VERSION "June 2, 2025"

NS_ :

BS_:

BU_: VEH CH Receiver Receiver ChassisBus VehicleBus PartyBus

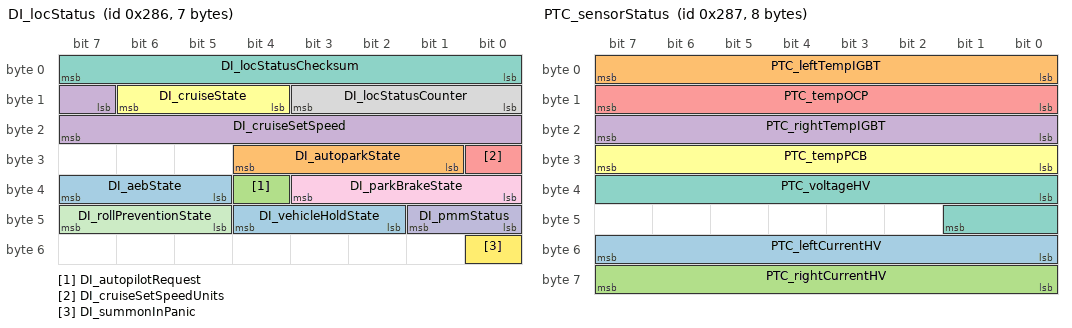
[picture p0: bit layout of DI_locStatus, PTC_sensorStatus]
BO_ 646 DI_locStatus: 7 VEH
 SG_ DI_aebState : 37|3@1+ (1,0) [0|0] "" Vector__XXX
 SG_ DI_autoparkState : 25|4@1+ (1,0) [0|0] "" Vector__XXX
 SG_ DI_autopilotRequest : 36|1@1+ (1,0) [0|0] "" Vector__XXX
 SG_ DI_cruiseSetSpeed : 15|9@1+ (0.5,0) [0|0] "speed" Vector__XXX
 SG_ DI_cruiseSetSpeedUnits : 24|1@1+ (1,0) [0|0] "" Vector__XXX
 SG_ DI_cruiseState : 12|3@1+ (1,0) [0|0] "" Vector__XXX
 SG_ DI_locStatusChecksum : 0|8@1+ (1,0) [0|0] "" Vector__XXX
 SG_ DI_locStatusCounter : 8|4@1+ (1,0) [0|0] "" Vector__XXX
 SG_ DI_parkBrakeState : 32|4@1+ (1,0) [0|0] "" Vector__XXX
 SG_ DI_pmmStatus : 40|2@1+ (1,0) [0|0] "" Vector__XXX
 SG_ DI_rollPreventionState : 45|3@1+ (1,0) [0|0] "" Vector__XXX
 SG_ DI_summonInPanic : 48|1@1+ (1,0) [0|0] "" Vector__XXX
 SG_ DI_vehicleHoldState : 42|3@1+ (1,0) [0|0] "" Vector__XXX

BO_ 647 PTC_sensorStatus: 8 VEH
 SG_ PTC_leftCurrentHV : 48|8@1+ (0.2,0) [0|0] "A" Vector__XXX
 SG_ PTC_leftTempIGBT : 0|8@1+ (1,-40) [0|0] "degC" Vector__XXX
 SG_ PTC_rightCurrentHV : 56|8@1+ (0.2,0) [0|0] "A" Vector__XXX
 SG_ PTC_rightTempIGBT : 16|8@1+ (1,-40) [0|0] "degC" Vector__XXX
 SG_ PTC_tempOCP : 8|8@1+ (1,-40) [0|0] "degC" Vector__XXX
 SG_ PTC_tempPCB : 24|8@1+ (1,-40) [0|0] "degC" Vector__XXX
 SG_ PTC_voltageHV : 32|10@1+ (0.5,0) [0|0] "V" Vector__XXX

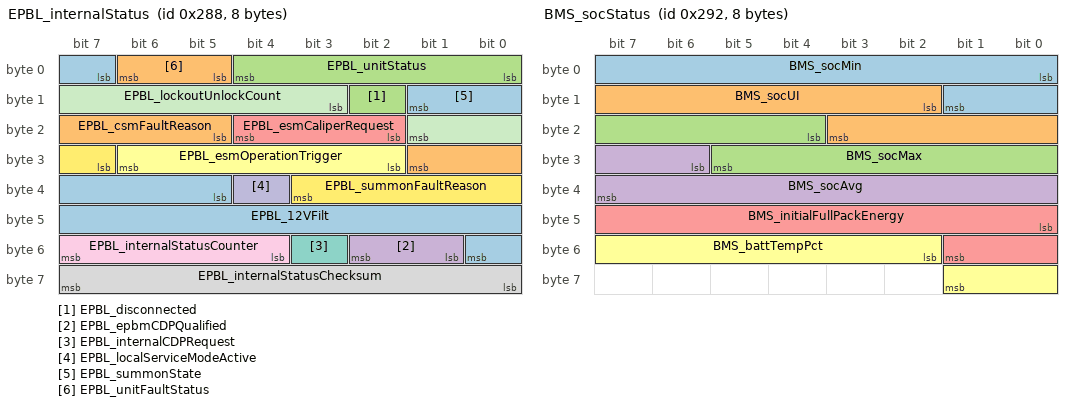
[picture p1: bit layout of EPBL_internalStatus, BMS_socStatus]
BO_ 648 EPBL_internalStatus: 8 VEH
 SG_ EPBL_12VFilt : 37|12@1+ (0.00544368,0) [0|0] "V" Vector__XXX
 SG_ EPBL_csmFaultReason : 21|5@1+ (1,0) [0|0] "" Vector__XXX
 SG_ EPBL_disconnected : 10|1@1+ (1,0) [0|0] "" Vector__XXX
 SG_ EPBL_epbmCDPQualified : 49|2@1+ (1,0) [0|0] "" Vector__XXX
 SG_ EPBL_esmCaliperRequest : 18|3@1+ (1,0) [0|0] "" Vector__XXX
 SG_ EPBL_esmOperationTrigger : 26|5@1+ (1,0) [0|0] "" Vector__XXX
 SG_ EPBL_internalCDPRequest : 51|1@1+ (1,0) [0|0] "" Vector__XXX
 SG_ EPBL_internalStatusChecksum : 56|8@1+ (1,0) [0|0] "" Vector__XXX
 SG_ EPBL_internalStatusCounter : 52|4@1+ (1,0) [0|0] "" Vector__XXX
 SG_ EPBL_localServiceModeActive : 36|1@1+ (1,0) [0|0] "" Vector__XXX
 SG_ EPBL_lockoutUnlockCount : 11|7@1+ (1,0) [0|0] "" Vector__XXX
 SG_ EPBL_summonFaultReason : 31|5@1+ (1,0) [0|0] "" Vector__XXX
 SG_ EPBL_summonState : 7|3@1+ (1,0) [0|0] "" Vector__XXX
 SG_ EPBL_unitFaultStatus : 5|2@1+ (1,0) [0|0] "" Vector__XXX
 SG_ EPBL_unitStatus : 0|5@1+ (1,0) [0|0] "" Vector__XXX

BO_ 658 BMS_socStatus: 8 VEH
 SG_ BMS_socMin : 0|10@1+ (0.1,0) [0|102.3] "%" Vector__XXX
 SG_ BMS_socUI : 10|10@1+ (0.1,0) [0|102.3] "%" Vector__XXX
 SG_ BMS_socMax : 20|10@1+ (0.1,0) [0|102.3] "%" Vector__XXX
 SG_ BMS_socAvg : 30|10@1+ (0.1,0) [0|102.3] "%" Vector__XXX
 SG_ BMS_initialFullPackEnergy : 40|10@1+ (0.1,0) [0|102.3] "kWh" Vector__XXX
 SG_ BMS_battTempPct : 50|8@1+ (0.4,0) [0|100] "%"  Receiver

BO_ 659 UI_chassisControl: 8 VEH
 SG_ UI_accOvertakeEnable : 18|2@1+ (1,0) [0|0] "" Vector__XXX
 SG_ UI_aebEnable : 20|2@1+ (1,0) [0|0] "" Vector__XXX
 SG_ UI_aesEnable : 22|2@1+ (1,0) [0|0] "" Vector__XXX
 SG_ UI_ahlbEnable : 24|2@1+ (1,0) [0|0] "" Vector__XXX
 SG_ UI_autoLaneChangeEnable : 32|2@1+ (1,0) [0|0] "" Vector__XXX
 SG_ UI_autoParkRequest : 28|4@1+ (1,0) [0|0] "" Vector__XXX
 SG_ UI_bsdEnable : 34|2@1+ (1,0) [0|0] "" Vector__XXX
 SG_ UI_chassisControlChecksum : 56|8@1+ (1,0) [0|0] "" Vector__XXX
 SG_ UI_chassisControlCounter : 52|4@1+ (1,0) [0|0] "" Vector__XXX
 SG_ UI_dasDebugEnable : 17|1@1+ (1,0) [0|0] "" Vector__XXX
 SG_ UI_distanceUnits : 16|1@1+ (1,0) [0|0] "" Vector__XXX
 SG_ UI_fcwEnable : 36|2@1+ (1,0) [0|0] "" Vector__XXX
 SG_ UI_fcwSensitivity : 38|2@1+ (1,0) [0|0] "" Vector__XXX
 SG_ UI_latControlEnable : 40|2@1+ (1,0) [0|0] "" Vector__XXX
 SG_ UI_ldwEnable : 42|2@1+ (1,0) [0|0] "" Vector__XXX
 SG_ UI_narrowGarages : 7|1@1+ (1,0) [0|0] "" Vector__XXX
 SG_ UI_parkBrakeRequest : 5|2@1+ (1,0) [0|0] "" Vector__XXX
 SG_ UI_pedalSafetyEnable : 44|2@1+ (1,0) [0|0] "" Vector__XXX
 SG_ UI_rebootAutopilot : 27|1@1+ (1,0) [0|0] "" Vector__XXX
 SG_ UI_redLightStopSignEnable : 46|2@1+ (1,0) [0|0] "" Vector__XXX
 SG_ UI_selfParkTune : 48|4@1+ (1,0) [0|0] "" Vector__XXX
 SG_ UI_steeringTuneRequest : 0|2@1+ (1,0) [0|0] "" Vector__XXX
 SG_ UI_suspensionLevelRequest : 13|3@1+ (1,0) [0|0] "" Vector__XXX
 SG_ UI_tractionControlMode : 2|3@1+ (1,0) [0|0] "" Vector__XXX
 SG_ UI_trailerMode : 12|1@1+ (1,0) [0|0] "" Vector__XXX
 SG_ UI_winchModeRequest : 8|2@1+ (1,0) [0|0] "" Vector__XXX
 SG_ UI_zeroSpeedConfirmed : 10|2@1+ (1,0) [0|0] "" Vector__XXX

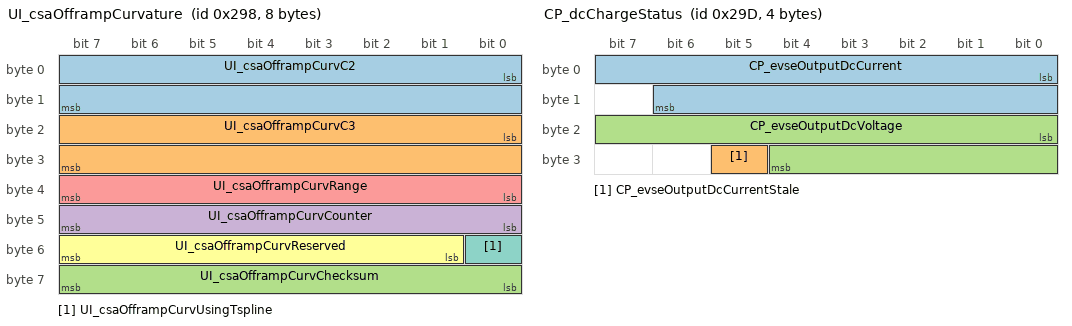
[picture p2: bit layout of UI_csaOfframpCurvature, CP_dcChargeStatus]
BO_ 664 UI_csaOfframpCurvature: 8 VEH
 SG_ UI_csaOfframpCurvC2 : 0|16@1- (1e-06,0) [0|0] "1/m" Vector__XXX
 SG_ UI_csaOfframpCurvC3 : 16|16@1- (4e-09,0) [0|0] "1/m2" Vector__XXX
 SG_ UI_csaOfframpCurvChecksum : 56|8@1+ (1,0) [0|0] "" Vector__XXX
 SG_ UI_csaOfframpCurvCounter : 40|8@1+ (1,0) [0|0] "" Vector__XXX
 SG_ UI_csaOfframpCurvRange : 32|8@1+ (2,0) [0|0] "m" Vector__XXX
 SG_ UI_csaOfframpCurvReserved : 49|7@1+ (1,0) [0|0] "" Vector__XXX
 SG_ UI_csaOfframpCurvUsingTspline : 48|1@1+ (1,0) [0|0] "" Vector__XXX

BO_ 669 CP_dcChargeStatus: 4 VEH
 SG_ CP_evseOutputDcCurrent : 0|15@1- (0.0732467,0) [-1200|1200] "A" Vector__XXX
 SG_ CP_evseOutputDcCurrentStale : 29|1@1+ (1,0) [0|1] "" Vector__XXX
 SG_ CP_evseOutputDcVoltage : 16|13@1+ (0.0732422,0) [0|599.927] "V" Vector__XXX

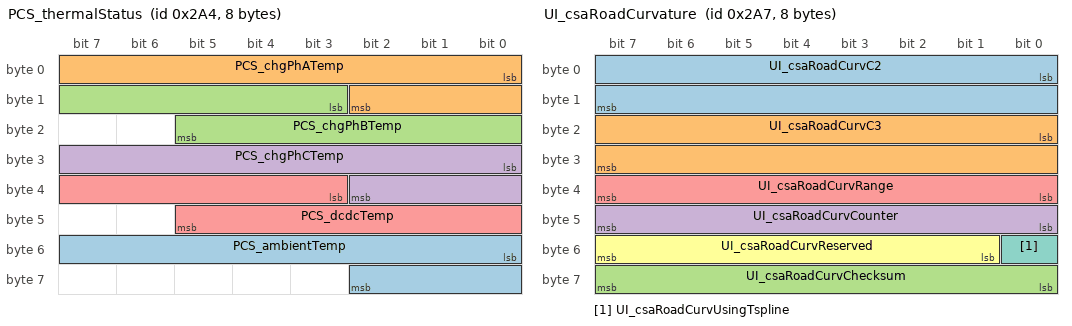
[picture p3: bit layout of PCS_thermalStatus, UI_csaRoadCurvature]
BO_ 676 PCS_thermalStatus: 8 VEH
 SG_ PCS_ambientTemp : 48|11@1- (0.1,40) [0|0] "C" Vector__XXX
 SG_ PCS_chgPhATemp : 0|11@1- (0.1,40) [0|0] "C" Vector__XXX
 SG_ PCS_chgPhBTemp : 11|11@1- (0.1,40) [0|0] "C" Vector__XXX
 SG_ PCS_chgPhCTemp : 24|11@1- (0.1,40) [0|0] "C" Vector__XXX
 SG_ PCS_dcdcTemp : 35|11@1- (0.1,40) [0|0] "C" Vector__XXX

BO_ 679 UI_csaRoadCurvature: 8 VEH
 SG_ UI_csaRoadCurvC2 : 0|16@1- (1e-06,0) [0|0] "1/m" Vector__XXX
 SG_ UI_csaRoadCurvC3 : 16|16@1- (4e-09,0) [0|0] "1/m2" Vector__XXX
 SG_ UI_csaRoadCurvChecksum : 56|8@1+ (1,0) [0|0] "" Vector__XXX
 SG_ UI_csaRoadCurvCounter : 40|8@1+ (1,0) [0|0] "" Vector__XXX
 SG_ UI_csaRoadCurvRange : 32|8@1+ (2,0) [0|0] "m" Vector__XXX
 SG_ UI_csaRoadCurvReserved : 49|7@1+ (1,0) [0|0] "" Vector__XXX
 SG_ UI_csaRoadCurvUsingTspline : 48|1@1+ (1,0) [0|0] "" Vector__XXX

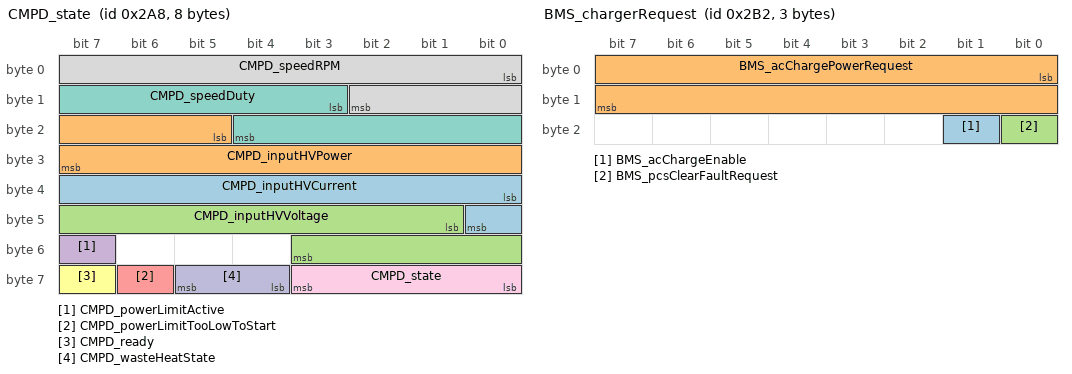
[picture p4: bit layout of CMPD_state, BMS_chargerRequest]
BO_ 680 CMPD_state: 8 VEH
 SG_ CMPD_inputHVCurrent : 32|9@1+ (0.1,0) [0|50] "A" Vector__XXX
 SG_ CMPD_inputHVPower : 21|11@1+ (10,0) [0|20000] "W" Vector__XXX
 SG_ CMPD_inputHVVoltage : 41|11@1+ (0.5,0) [0|1000] "V" Vector__XXX
 SG_ CMPD_powerLimitActive : 55|1@1+ (1,0) [0|1] "" Vector__XXX
 SG_ CMPD_powerLimitTooLowToStart : 62|1@1+ (1,0) [0|1] "" Vector__XXX
 SG_ CMPD_ready : 63|1@1+ (1,0) [0|1] "" Vector__XXX
 SG_ CMPD_speedDuty : 11|10@1+ (0.1,0) [0|100] "%" Vector__XXX
 SG_ CMPD_speedRPM : 0|11@1+ (10,0) [0|20000] "RPM" Vector__XXX
 SG_ CMPD_state : 56|4@1+ (1,0) [0|15] "" Vector__XXX
 SG_ CMPD_wasteHeatState : 60|2@1+ (1,0) [0|3] "" Vector__XXX

BO_ 681 EPBL_status: 8 VEH
 SG_ EPBL_blockDrive : 51|1@1+ (1,0) [0|0] "" Vector__XXX
 SG_ EPBL_bothDisconnected : 50|1@1+ (1,0) [0|0] "" Vector__XXX
 SG_ EPBL_brakeDiscWipeRequest : 30|2@1+ (1,0) [0|0] "" Vector__XXX
 SG_ EPBL_brakeHWConfigMismatch : 19|1@1+ (1,0) [0|0] "" Vector__XXX
 SG_ EPBL_brakeLight : 18|1@1+ (1,0) [0|0] "" Vector__XXX
 SG_ EPBL_cdpRequest : 27|1@1+ (1,0) [0|0] "" Vector__XXX
 SG_ EPBL_espPowerRequest : 46|1@1+ (1,0) [0|0] "" Vector__XXX
 SG_ EPBL_hornRequest : 48|1@1+ (1,0) [0|0] "" Vector__XXX
 SG_ EPBL_okToPark : 47|1@1+ (1,0) [0|0] "" Vector__XXX
 SG_ EPBL_requestUserConfirmation : 21|1@1+ (1,0) [0|0] "" Vector__XXX
 SG_ EPBL_statusChecksum : 56|8@1+ (1,0) [0|0] "" Vector__XXX
 SG_ EPBL_statusCounter : 52|4@1+ (1,0) [0|0] "" Vector__XXX
 SG_ EPBL_summonEnabled : 17|1@1+ (1,0) [0|0] "" Vector__XXX
 SG_ EPBL_systemStatus : 0|4@1+ (1,0) [0|0] "" Vector__XXX
 SG_ EPBL_telltale : 16|1@1+ (1,0) [0|0] "" Vector__XXX
 SG_ EPBL_uiButtonAvailable : 20|1@1+ (1,0) [0|0] "" Vector__XXX
 SG_ EPBL_updateMode : 24|1@1+ (1,0) [0|0] "" Vector__XXX
 SG_ EPBL_winchModeActive : 23|1@1+ (1,0) [0|0] "" Vector__XXX
 SG_ EPBL_winchModeAvailable : 49|1@1+ (1,0) [0|0] "" Vector__XXX
 SG_ EPBL_winchModeTimer : 32|12@1+ (1,0) [0|0] "" Vector__XXX

BO_ 690 BMS_chargerRequest: 3 VEH
 SG_ BMS_acChargeEnable : 17|1@1+ (1,0) [0|0] "" Vector__XXX
 SG_ BMS_acChargePowerRequest : 0|16@1+ (0.001,0) [0|0] "kW" Vector__XXX
 SG_ BMS_pcsClearFaultRequest : 16|1@1+ (1,0) [0|0] "" Vector__XXX

BO_ 691 VCRIGHT_logging1Hz: 8 VEH
 SG_ VCRIGHT_logging1HzIndex M : 0|4@1+ (1,0) [0|11] "" Vector__XXX
 SG_ VCRIGHT_LHPanelAirflowBlocked m3 : 54|1@1+ (1,0) [0|1] "" Vector__XXX
 SG_ VCRIGHT_RHPanelAirflowBlocked m3 : 55|1@1+ (1,0) [0|1] "" Vector__XXX
 SG_ VCRIGHT_cabinTempBreathLevel m1 : 56|8@1+ (0.5,-40) [-40|80] "C" Vector__XXX
 SG_ VCRIGHT_cabinTempFanCurrent m9 : 15|6@1- (0.001,0) [-0.01|0.05] "A" Vector__XXX
 SG_ VCRIGHT_cabinTempFanOutput m9 : 14|1@1+ (1,0) [0|1] "" Vector__XXX
 SG_ VCRIGHT_cabinTempGlassRoof m1 : 8|8@1+ (0.5,-40) [-40|80] "C" Vector__XXX
 SG_ VCRIGHT_cabinTempInterior m1 : 24|8@1+ (0.5,-40) [-40|80] "C" Vector__XXX
 SG_ VCRIGHT_cabinTempInteriorL2 m0 : 24|8@1+ (0.5,-40) [-40|80] "C" Vector__XXX
 SG_ VCRIGHT_cabinTempInteriorL3 m9 : 40|8@1+ (0.5,-40) [-40|80] "C" Vector__XXX
 SG_ VCRIGHT_cabinTempInteriorSunny m1 : 32|8@1+ (0.6,-40) [-40|100] "C" Vector__XXX
 SG_ VCRIGHT_cabinTempInteriorSunnyL2 m0 : 40|8@1+ (0.6,-40) [-40|100] "C" Vector__XXX
 SG_ VCRIGHT_cabinTempInteriorSunnyL3 m9 : 48|8@1+ (0.6,-40) [-40|100] "C" Vector__XXX
 SG_ VCRIGHT_cabinTempSideGlassLeft m1 : 40|8@1+ (0.5,-40) [-40|80] "C" Vector__XXX
 SG_ VCRIGHT_cabinTempSideGlassRight m1 : 48|8@1+ (0.5,-40) [-40|80] "C" Vector__XXX
 SG_ VCRIGHT_cabinTempTopPadAir m9 : 56|8@1+ (0.6,-40) [-40|100] "C" Vector__XXX
 SG_ VCRIGHT_cabinTempWindshield m1 : 16|8@1+ (0.5,-40) [-40|80] "C" Vector__XXX
 SG_ VCRIGHT_cloudinessProbability m9 : 33|7@1+ (1,0) [0|100] "%" Vector__XXX
 SG_ VCRIGHT_convectionDeliveredLeft m4 : 24|8@1+ (2,-254) [-254|256] "W/m2" Vector__XXX
 SG_ VCRIGHT_convectionDeliveredRight m4 : 32|8@1+ (2,-254) [-254|256] "W/m2" Vector__XXX
 SG_ VCRIGHT_convectionTargetLeft m4 : 8|8@1+ (2,-254) [-254|256] "W/m2" Vector__XXX
 SG_ VCRIGHT_convectionTargetRight m4 : 16|8@1+ (2,-254) [-254|256] "W/m2" Vector__XXX
 SG_ VCRIGHT_defrostAirflowBlocked m3 : 57|1@1+ (1,0) [0|1] "" Vector__XXX
 SG_ VCRIGHT_evapCondensationRate m10 : 47|9@1- (0.007,0) [-1|1] "g/s" Vector__XXX
 SG_ VCRIGHT_evapDryingRoutineRuntime m10 : 56|5@1+ (2,0) [0|60] "" Vector__XXX
 SG_ VCRIGHT_evapLoadInFresh m5 : 32|8@1+ (35,0) [0|8000] "W" Vector__XXX
 SG_ VCRIGHT_evapLoadInRecirc m5 : 40|8@1+ (35,0) [0|8000] "W" Vector__XXX
 SG_ VCRIGHT_evapWaterMass m10 : 40|7@1+ (6,0) [0|380] "Grams" Vector__XXX
 SG_ VCRIGHT_filterLifeBlowerTorque m9 : 4|10@1+ (0.006,-1.5) [-1.5|4.5] "Nm" Vector__XXX
 SG_ VCRIGHT_floorAirflowBlocked m3 : 56|1@1+ (1,0) [0|1] "" Vector__XXX
 SG_ VCRIGHT_hvacAirFlowModeRow1 m3 : 29|3@1+ (1,0) [0|7] "" Vector__XXX
 SG_ VCRIGHT_hvacAirFlowModeRow2 m3 : 32|3@1+ (1,0) [0|7] "" Vector__XXX
 SG_ VCRIGHT_hvacAirflowReason m3 : 48|4@1+ (1,0) [0|14] "" Vector__XXX
 SG_ VCRIGHT_hvacAutoTransitionReason m3 : 24|5@1+ (1,0) [0|19] "" Vector__XXX
 SG_ VCRIGHT_hvacCabOvrheatProtActive m9 : 30|1@1+ (1,0) [0|1] "" Vector__XXX
 SG_ VCRIGHT_hvacCabOvrheatProtAllowe m9 : 32|1@1+ (1,0) [0|1] "" Vector__XXX
 SG_ VCRIGHT_hvacCabinPurgeActive m9 : 29|1@1+ (1,0) [0|1] "" Vector__XXX
 SG_ VCRIGHT_hvacCabinPurgeAllowed m9 : 31|1@1+ (1,0) [0|1] "" Vector__XXX
 SG_ VCRIGHT_hvacIntakeEndStop m7 : 56|8@1+ (0.02,0) [0|5] "V" Vector__XXX
 SG_ VCRIGHT_hvacIntakeVoltage m6 : 56|8@1+ (0.02,0) [0|5] "V" Vector__XXX
 SG_ VCRIGHT_hvacIntakeZeroStop m8 : 56|8@1+ (0.02,0) [0|5] "V" Vector__XXX
 SG_ VCRIGHT_hvacLHBleedEndStop m7 : 8|8@1+ (0.02,0) [0|5] "V" Vector__XXX
 SG_ VCRIGHT_hvacLHBleedVoltage m6 : 8|8@1+ (0.02,0) [0|5] "V" Vector__XXX
 SG_ VCRIGHT_hvacLHBleedZeroStop m8 : 8|8@1+ (0.02,0) [0|5] "V" Vector__XXX
 SG_ VCRIGHT_hvacLHVaneEndStop m7 : 24|8@1+ (0.02,0) [0|5] "V" Vector__XXX
 SG_ VCRIGHT_hvacLHVaneVoltage m6 : 24|8@1+ (0.02,0) [0|5] "V" Vector__XXX
 SG_ VCRIGHT_hvacLHVaneZeroStop m8 : 24|8@1+ (0.02,0) [0|5] "V" Vector__XXX
 SG_ VCRIGHT_hvacLowerModeEndStop m7 : 48|8@1+ (0.02,0) [0|5] "V" Vector__XXX
 SG_ VCRIGHT_hvacLowerModeVoltage m6 : 48|8@1+ (0.02,0) [0|5] "V" Vector__XXX
 SG_ VCRIGHT_hvacLowerModeZeroStop m8 : 48|8@1+ (0.02,0) [0|5] "V" Vector__XXX
 SG_ VCRIGHT_hvacMassflowTarget m3 : 40|8@1+ (1,0) [0|200] "g/s" Vector__XXX
 SG_ VCRIGHT_hvacQdotFeedforward m5 : 16|16@1+ (1,-32767) [-32767|32767] "W" Vector__XXX
 SG_ VCRIGHT_hvacQdotLimitedLeft m3 : 52|1@1+ (1,0) [0|1] "" Vector__XXX
 SG_ VCRIGHT_hvacQdotLimitedRight m3 : 53|1@1+ (1,0) [0|1] "" Vector__XXX
 SG_ VCRIGHT_hvacRHBleedEndStop m7 : 16|8@1+ (0.02,0) [0|5] "V" Vector__XXX
 SG_ VCRIGHT_hvacRHBleedVoltage m6 : 16|8@1+ (0.02,0) [0|5] "V" Vector__XXX
 SG_ VCRIGHT_hvacRHBleedZeroStop m8 : 16|8@1+ (0.02,0) [0|5] "V" Vector__XXX
 SG_ VCRIGHT_hvacRHVaneEndStop m7 : 32|8@1+ (0.02,0) [0|5] "V" Vector__XXX
 SG_ VCRIGHT_hvacRHVaneVoltage m6 : 32|8@1+ (0.02,0) [0|5] "V" Vector__XXX
 SG_ VCRIGHT_hvacRHVaneZeroStop m8 : 32|8@1+ (0.02,0) [0|5] "V" Vector__XXX
 SG_ VCRIGHT_hvacSetTempActualLeft m3 : 8|8@1+ (0.1,15) [15|28] "C" Vector__XXX
 SG_ VCRIGHT_hvacSetTempActualRight m3 : 16|8@1+ (0.1,15) [15|28] "C" Vector__XXX
 SG_ VCRIGHT_hvacUpperModeEndStop m7 : 40|8@1+ (0.02,0) [0|5] "V" Vector__XXX
 SG_ VCRIGHT_hvacUpperModeVoltage m6 : 40|8@1+ (0.02,0) [0|5] "V" Vector__XXX
 SG_ VCRIGHT_hvacUpperModeZeroStop m8 : 40|8@1+ (0.02,0) [0|5] "V" Vector__XXX
 SG_ VCRIGHT_leftHeatOvertempProtect m10 : 61|1@1+ (1,0) [0|1] "" Vector__XXX
 SG_ VCRIGHT_pcbaTemperature m2 : 4|11@1+ (0.125,-40) [-40|150] "C" Vector__XXX
 SG_ VCRIGHT_ptcHeaterHvacActNotReady m5 : 7|1@1+ (1,0) [0|1] "" Vector__XXX
 SG_ VCRIGHT_ptcHeaterLAirPathBlocked m5 : 10|1@1+ (1,0) [0|1] "" Vector__XXX
 SG_ VCRIGHT_ptcHeaterNoAirflow m5 : 6|1@1+ (1,0) [0|1] "" Vector__XXX
 SG_ VCRIGHT_ptcHeaterNoHighVoltage m5 : 9|1@1+ (1,0) [0|1] "" Vector__XXX
 SG_ VCRIGHT_ptcHeaterNoUiRequest m5 : 8|1@1+ (1,0) [0|1] "" Vector__XXX
 SG_ VCRIGHT_ptcHeaterPwrDemandLeft m2 : 40|8@1+ (20,0) [0|5000] "W" Vector__XXX
 SG_ VCRIGHT_ptcHeaterPwrDemandRight m2 : 48|8@1+ (20,0) [0|5000] "W" Vector__XXX
 SG_ VCRIGHT_ptcHeaterRAirPathBlocked m5 : 11|1@1+ (1,0) [0|1] "" Vector__XXX
 SG_ VCRIGHT_ptcHeaterReqAirpathBlock m5 : 12|1@1+ (1,0) [0|1] "" Vector__XXX
 SG_ VCRIGHT_ptcHeaterTempDuctFault m5 : 5|1@1+ (1,0) [0|1] "" Vector__XXX
 SG_ VCRIGHT_ptcHeaterTempDuctHigh m5 : 4|1@1+ (1,0) [0|1] "" Vector__XXX
 SG_ VCRIGHT_rightHeatOvertempProtect m10 : 62|1@1+ (1,0) [0|1] "" Vector__XXX
 SG_ VCRIGHT_solarLoadLeftOccupant m4 : 48|7@1+ (2,0) [0|254] "W/m2" Vector__XXX
 SG_ VCRIGHT_solarLoadOnVehFiltered m9 : 21|8@1+ (4,0) [0|1020] "W/m2" Vector__XXX
 SG_ VCRIGHT_solarLoadOnVehicle m4 : 56|8@1+ (4,0) [0|1020] "W/m2" Vector__XXX
 SG_ VCRIGHT_solarLoadRightOccupant m4 : 40|7@1+ (2,0) [0|254] "W/m2" Vector__XXX
 SG_ VCRIGHT_tempDuctModeledLeft m10 : 4|9@1+ (0.3,-40) [-40|105] "C" Vector__XXX
 SG_ VCRIGHT_tempDuctModeledRight m10 : 13|9@1+ (0.3,-40) [-40|105] "C" Vector__XXX
 SG_ VCRIGHT_tempHtrSurfaceModeledL m10 : 22|9@1+ (0.3,-40) [-40|105] "C" Vector__XXX
 SG_ VCRIGHT_tempHtrSurfaceModeledR m10 : 31|9@1+ (0.3,-40) [-40|105] "C" Vector__XXX
 SG_ VCRIGHT_tempIncarCabinDeep m0 : 16|8@1+ (0.5,-40) [-40|85] "C" Vector__XXX
 SG_ VCRIGHT_tempIncarCabinMid m0 : 32|8@1+ (0.5,-40) [-40|85] "C" Vector__XXX
 SG_ VCRIGHT_tempIncarCabinProbe m0 : 8|8@1+ (0.5,-40) [-40|85] "C" Vector__XXX
 SG_ VCRIGHT_wattsHeaterLeftTotal m2 : 16|10@1+ (5,0) [0|4000] "W" Vector__XXX
 SG_ VCRIGHT_wattsHeaterRightTotal m2 : 26|10@1+ (5,0) [0|4000] "W" Vector__XXX

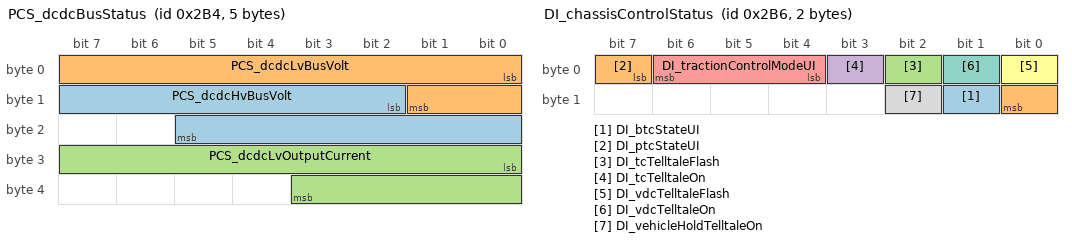
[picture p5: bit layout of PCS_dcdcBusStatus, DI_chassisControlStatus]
BO_ 692 PCS_dcdcBusStatus: 5 VEH
 SG_ PCS_dcdcHvBusVolt : 10|12@1+ (0.146484375,0) [0|599.853515625] "V" X
 SG_ PCS_dcdcLvBusVolt : 0|10@1+ (0.0390625,0) [0|39.9609375] "V" X
 SG_ PCS_dcdcLvOutputCurrent : 24|12@1+ (0.1,0) [0|400] "A" X

BO_ 694 DI_chassisControlStatus: 2 VEH
 SG_ DI_btcStateUI : 9|1@1+ (1,0) [0|0] "" Vector__XXX
 SG_ DI_ptcStateUI : 7|2@1+ (1,0) [0|0] "" Vector__XXX
 SG_ DI_tcTelltaleFlash : 2|1@1+ (1,0) [0|0] "" Vector__XXX
 SG_ DI_tcTelltaleOn : 3|1@1+ (1,0) [0|0] "" Vector__XXX
 SG_ DI_tractionControlModeUI : 4|3@1+ (1,0) [0|0] "" Vector__XXX
 SG_ DI_vdcTelltaleFlash : 0|1@1+ (1,0) [0|0] "" Vector__XXX
 SG_ DI_vdcTelltaleOn : 1|1@1+ (1,0) [0|0] "" Vector__XXX
 SG_ DI_vehicleHoldTelltaleOn : 10|1@1+ (1,0) [0|1] ""  Receiver

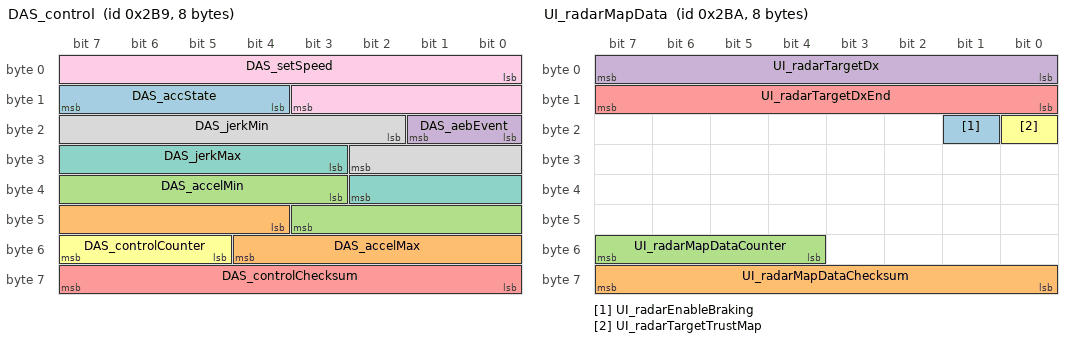
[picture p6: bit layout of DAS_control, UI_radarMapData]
BO_ 697 DAS_control: 8 CH
 SG_ DAS_accState : 12|4@1+ (1,0) [0|0] "" Vector__XXX
 SG_ DAS_accelMax : 44|9@1+ (0.04,-15) [0|0] "m/s^2" Vector__XXX
 SG_ DAS_accelMin : 35|9@1+ (0.04,-15) [0|0] "m/s^2" Vector__XXX
 SG_ DAS_aebEvent : 16|2@1+ (1,0) [0|0] "" Vector__XXX
 SG_ DAS_controlChecksum : 56|8@1+ (1,0) [0|0] "" Vector__XXX
 SG_ DAS_controlCounter : 53|3@1+ (1,0) [0|0] "" Vector__XXX
 SG_ DAS_jerkMax : 27|8@1+ (0.034,0) [0|0] "m/s^3" Vector__XXX
 SG_ DAS_jerkMin : 18|9@1+ (0.018,-9.1) [0|0] "m/s^3" Vector__XXX
 SG_ DAS_setSpeed : 0|12@1+ (0.1,0) [0|0] "kph" Vector__XXX

BO_ 698 UI_radarMapData: 8 VEH
 SG_ UI_radarEnableBraking : 17|1@1+ (1,0) [0|0] "" Vector__XXX
 SG_ UI_radarMapDataChecksum : 56|8@1+ (1,0) [0|0] "" Vector__XXX
 SG_ UI_radarMapDataCounter : 52|4@1+ (1,0) [0|0] "" Vector__XXX
 SG_ UI_radarTargetDx : 0|8@1+ (1,-95) [0|0] "m" Vector__XXX
 SG_ UI_radarTargetDxEnd : 8|8@1+ (1,0) [0|0] "m" Vector__XXX
 SG_ UI_radarTargetTrustMap : 16|1@1+ (1,0) [0|0] "" Vector__XXX

BO_ 701 ID2BDCP_dcPowerLimits: 4 VehicleBus
 SG_ CP_evseInstantDcPowerLimit : 0|13@1+ (0.0622559,0) [0|509.938] "kW"  Receiver
 SG_ CP_evseMaxDcPowerLimit : 16|13@1+ (0.0622559,0) [0|509.938] "kW"  Receiver

BO_ 705 VCFRONT_logging10Hz: 8 VEH
 SG_ VCFRONT_logging10HzIndex M : 0|3@1+ (1,0) [0|7] "" Vector__XXX
 SG_ VCFRONT_activeLouverAbnormalKT m4 : 3|1@1+ (1,0) [0|1] "" Vector__XXX
 SG_ VCFRONT_activeLouverCalibRange m4 : 53|8@1+ (1,630) [630|880] "ticks" Vector__XXX
 SG_ VCFRONT_activeLouverCommSuccess m4 : 63|1@1+ (1,0) [0|1] "" Vector__XXX
 SG_ VCFRONT_activeLouverDemand m4 : 32|7@1+ (1,0) [0|100] "%" Vector__XXX
 SG_ VCFRONT_activeLouverDisconnect m4 : 6|1@1+ (1,0) [0|1] "" Vector__XXX
 SG_ VCFRONT_activeLouverFalsStallCal m4 : 62|1@1+ (1,0) [0|1] "" Vector__XXX
 SG_ VCFRONT_activeLouverFalsStallRun m4 : 61|1@1+ (1,0) [0|1] "" Vector__XXX
 SG_ VCFRONT_activeLouverIsCalibrated m4 : 15|1@1+ (1,0) [0|1] "" Vector__XXX
 SG_ VCFRONT_activeLouverMotorCounts m4 : 16|11@1+ (1,-100) [-100|1900] "ticks" Vector__XXX
 SG_ VCFRONT_activeLouverMotorState m4 : 8|3@1+ (1,0) [0|7] "" Vector__XXX
 SG_ VCFRONT_activeLouverOverCurrent m4 : 4|1@1+ (1,0) [0|1] "" Vector__XXX
 SG_ VCFRONT_activeLouverOverTemp m4 : 5|1@1+ (1,0) [0|1] "" Vector__XXX
 SG_ VCFRONT_activeLouverStallCounter m4 : 40|3@1+ (1,0) [0|7] "" Vector__XXX
 SG_ VCFRONT_activeLouverStallLength m4 : 43|10@1+ (1,0) [0|1000] "ticks" Vector__XXX
 SG_ VCFRONT_activeLouverStalled m4 : 7|1@1+ (1,0) [0|1] "" Vector__XXX
 SG_ VCFRONT_activeLouverState m4 : 11|4@1+ (1,0) [0|8] "" Vector__XXX
 SG_ VCFRONT_compLimitDeadband m3 : 8|1@1+ (1,0) [0|1] "" Vector__XXX
 SG_ VCFRONT_compLimitNvh m3 : 6|1@1+ (1,0) [0|1] "" Vector__XXX
 SG_ VCFRONT_compLimitPresDischargeHi m3 : 3|1@1+ (1,0) [0|1] "" Vector__XXX
 SG_ VCFRONT_compLimitScrollSepRamp m3 : 7|1@1+ (1,0) [0|1] "" Vector__XXX
 SG_ VCFRONT_compLimitScrollSepRegion m3 : 5|1@1+ (1,0) [0|1] "" Vector__XXX
 SG_ VCFRONT_compLimitTempDischargeHi m3 : 4|1@1+ (1,0) [0|1] "" Vector__XXX
 SG_ VCFRONT_compLimitTempDischargeSi m3 : 19|1@1+ (1,0) [0|1] "" Vector__XXX
 SG_ VCFRONT_compRampRateUpMax m3 : 20|6@1+ (0.1,0) [0|6] "%/s" Vector__XXX
 SG_ VCFRONT_compStandbyCoastDownMode m3 : 15|1@1+ (1,0) [0|1] "" Vector__XXX
 SG_ VCFRONT_compStandbyCommunication m3 : 10|1@1+ (1,0) [0|1] "" Vector__XXX
 SG_ VCFRONT_compStandbyHVNotReady m3 : 11|1@1+ (1,0) [0|1] "" Vector__XXX
 SG_ VCFRONT_compStandbyHighSuctionSu m3 : 16|1@1+ (1,0) [0|1] "" Vector__XXX
 SG_ VCFRONT_compStandbyLowAmbient m3 : 12|1@1+ (1,0) [0|1] "" Vector__XXX
 SG_ VCFRONT_compStandbyLowDischPress m3 : 13|1@1+ (1,0) [0|1] "" Vector__XXX
 SG_ VCFRONT_compStandbyMultiplePdCut m3 : 17|1@1+ (1,0) [0|1] "" Vector__XXX
 SG_ VCFRONT_compStandbyRefrigNotOk m3 : 14|1@1+ (1,0) [0|1] "" Vector__XXX
 SG_ VCFRONT_compStandbySelfNotReady m3 : 9|1@1+ (1,0) [0|1] "" Vector__XXX
 SG_ VCFRONT_compStandbyShowroomMode m3 : 18|1@1+ (1,0) [0|1] "" Vector__XXX
 SG_ VCFRONT_coolantFlowAmbSourceActu m0 : 48|8@1+ (0.1,0) [0|25] "LPM" Vector__XXX
 SG_ VCFRONT_coolantFlowAmbSourceTarg m0 : 56|8@1+ (0.1,0) [0|25] "LPM" Vector__XXX
 SG_ VCFRONT_coolantTempBasedMode m2 : 3|2@1+ (1,0) [0|3] "" Vector__XXX
 SG_ VCFRONT_coolantValveAngleActual m2 : 8|11@1+ (0.25,-100) [-100|410] "deg" Vector__XXX
 SG_ VCFRONT_coolantValveAngleTarget m2 : 19|10@1+ (0.25,-5) [-5|245] "deg" Vector__XXX
 SG_ VCFRONT_coolantValveAngleTravel m2 : 40|10@1+ (5,0) [0|5000] "deg" Vector__XXX
 SG_ VCFRONT_coolantValveDuty m2 : 32|8@1- (1,0) [-100|100] "%" Vector__XXX
 SG_ VCFRONT_coolantValveISense m2 : 56|7@1+ (0.01,0) [0|1.2] "A" Vector__XXX
 SG_ VCFRONT_coolantValveModeWrong m2 : 5|1@1+ (1,0) [0|1] "" Vector__XXX
 SG_ VCFRONT_coolantValveState m2 : 29|2@1+ (1,0) [0|3] "" Vector__XXX
 SG_ VCFRONT_exvFlow m3 : 32|10@1+ (0.1,0) [0|100] "%" Vector__XXX
 SG_ VCFRONT_exvIsFlooding m3 : 42|1@1+ (1,0) [0|1] "" Vector__XXX
 SG_ VCFRONT_exvMotorState m3 : 28|4@1+ (1,0) [0|10] "" Vector__XXX
 SG_ VCFRONT_exvPrechillActive m3 : 43|1@1+ (1,0) [0|1] "" Vector__XXX
 SG_ VCFRONT_pumpBatSpiError m0 : 46|1@1+ (1,0) [0|1] "" Vector__XXX
 SG_ VCFRONT_pumpBatteryEnabled m0 : 41|1@1+ (1,0) [0|1] "" Vector__XXX
 SG_ VCFRONT_pumpBatteryInitd m0 : 39|1@1+ (1,0) [0|1] "" Vector__XXX
 SG_ VCFRONT_pumpBatteryOutVoltage m0 : 24|7@1+ (0.2,0) [0|20] "V" Vector__XXX
 SG_ VCFRONT_pumpBatteryPowerOn m0 : 43|1@1+ (1,0) [0|1] "" Vector__XXX
 SG_ VCFRONT_pumpBatteryRPMTarget m0 : 3|10@1+ (10,0) [0|10000] "rpm" Vector__XXX
 SG_ VCFRONT_pumpPowertrainEnabled m0 : 42|1@1+ (1,0) [0|1] "" Vector__XXX
 SG_ VCFRONT_pumpPowertrainInitd m0 : 40|1@1+ (1,0) [0|1] "" Vector__XXX
 SG_ VCFRONT_pumpPowertrainOutVoltage m0 : 32|7@1+ (0.2,0) [0|20] "V" Vector__XXX
 SG_ VCFRONT_pumpPowertrainPowerOn m0 : 44|1@1+ (1,0) [0|1] "" Vector__XXX
 SG_ VCFRONT_pumpPowertrainRPMTarget m0 : 13|10@1+ (10,0) [0|10000] "rpm" Vector__XXX
 SG_ VCFRONT_pumpPtSpiError m0 : 47|1@1+ (1,0) [0|1] "" Vector__XXX
 SG_ VCFRONT_pumpsWake m0 : 45|1@1+ (1,0) [0|1] "" Vector__XXX
 SG_ VCFRONT_radarHeaterCurrent m6 : 8|8@1+ (0.1,0) [0|25.5] "A" Vector__XXX
 SG_ VCFRONT_radarHeaterDuty m6 : 16|7@1+ (1,0) [0|100] "%" Vector__XXX
 SG_ VCFRONT_radarHeaterTargetVoltage m6 : 24|8@1+ (0.1,0) [0|16] "V" Vector__XXX
 SG_ VCFRONT_radiatorFanDemandLimit m1 : 48|7@1+ (1,0) [0|100] "%" Vector__XXX
 SG_ VCFRONT_radiatorFanDemandLimited m1 : 47|1@1+ (1,0) [0|1] "" Vector__XXX
 SG_ VCFRONT_radiatorFanEnabled m1 : 27|1@1+ (1,0) [0|1] "" Vector__XXX
 SG_ VCFRONT_radiatorFanInitd m1 : 26|1@1+ (1,0) [0|1] "" Vector__XXX
 SG_ VCFRONT_radiatorFanOutVoltage m1 : 8|7@1+ (0.2,0) [0|20] "V" Vector__XXX
 SG_ VCFRONT_radiatorFanPhaseCurrent m1 : 32|8@1+ (0.25,-10) [-10|50] "A" Vector__XXX
 SG_ VCFRONT_radiatorFanPhaseIMax m1 : 40|7@1+ (0.25,0) [5|35] "A" Vector__XXX
 SG_ VCFRONT_radiatorFanPowerOn m1 : 28|1@1+ (1,0) [0|1] "" Vector__XXX
 SG_ VCFRONT_radiatorFanRPMTarget m1 : 16|10@1+ (10,0) [0|10000] "rpm" Vector__XXX
 SG_ VCFRONT_refrigerantHasBeenFilled m3 : 27|1@1+ (1,0) [0|1] "" Vector__XXX
 SG_ VCFRONT_refrigerantValvesClosed m3 : 26|1@1+ (1,0) [0|1] "" Vector__XXX
 SG_ VCFRONT_solenoidEvapCurrent m3 : 58|6@1+ (0.04,0) [0|2.4] "A" Vector__XXX
 SG_ VCFRONT_subcoolFeedbackFlow m5 : 13|10@1- (0.1,0) [-50|50] "%" Vector__XXX
 SG_ VCFRONT_subcoolFeedforwardFlow m5 : 3|10@1+ (0.1,0) [0|100] "%" Vector__XXX
 SG_ VCFRONT_subcoolProtectionFlow m5 : 24|10@1+ (0.1,0) [0|100] "%" Vector__XXX
 SG_ VCFRONT_subcoolProtectionType m5 : 34|3@1+ (1,0) [0|4] "" Vector__XXX
 SG_ VCFRONT_tempDischargeSimulated m3 : 44|11@1+ (0.125,-40) [-40|150] "C" Vector__XXX
 SG_ VCFRONT_thmlFanSpiError m1 : 55|1@1+ (1,0) [0|1] "" Vector__XXX
 SG_ VCFRONT_usingSimulatedAmbTemp m3 : 57|1@1+ (1,0) [0|1] "" Vector__XXX
 SG_ VCFRONT_usingSimulatedDischTemp m3 : 56|1@1+ (1,0) [0|1] "" Vector__XXX
 SG_ VCFRONT_usingSimulatedSuctTemp m3 : 55|1@1+ (1,0) [0|1] "" Vector__XXX

BO_ 708 PCS_logging: 8 VEH
 SG_ PCS_logMessageSelect M : 0|5@1+ (1,0) [0|0] "" Vector__XXX
 SG_ PCS_chgPhAInputIrms m0 : 5|9@1+ (0.1,0) [0|0] "A" Vector__XXX
 SG_ PCS_chgPhAIntBusV m0 : 14|9@1+ (1,0) [0|0] "V" Vector__XXX
 SG_ PCS_chgPhAIntBusVTarget m0 : 23|9@1+ (1,0) [0|0] "V" Vector__XXX
 SG_ PCS_chgPhAOutputI m0 : 32|8@1+ (0.1,0) [0|0] "A" Vector__XXX
 SG_ PCS_chgPhBInputIrms m1 : 5|9@1+ (0.1,0) [0|0] "A" Vector__XXX
 SG_ PCS_chgPhBIntBusV m1 : 14|9@1+ (1,0) [0|0] "V" Vector__XXX
 SG_ PCS_chgPhBIntBusVTarget m1 : 23|9@1+ (1,0) [0|0] "V" Vector__XXX
 SG_ PCS_chgPhBOutputI m1 : 32|8@1+ (0.1,0) [0|0] "A" Vector__XXX
 SG_ PCS_chgPhCInputIrms m2 : 5|9@1+ (0.1,0) [0|0] "A" Vector__XXX
 SG_ PCS_chgPhCIntBusV m2 : 14|9@1+ (1,0) [0|0] "V" Vector__XXX
 SG_ PCS_chgPhCIntBusVTarget m2 : 23|9@1+ (1,0) [0|0] "V" Vector__XXX
 SG_ PCS_chgPhCOutputI m2 : 32|8@1+ (0.1,0) [0|0] "A" Vector__XXX
 SG_ PCS_chgInputL1NVrms m3 : 5|12@1+ (0.2,0) [0|0] "V" Vector__XXX
 SG_ PCS_chgInputL2NVrms m3 : 17|12@1+ (0.2,0) [0|0] "V" Vector__XXX
 SG_ PCS_chgInputL3NVrms m3 : 29|12@1+ (0.2,0) [0|0] "V" Vector__XXX
 SG_ PCS_chgInputL1L2Vrms m3 : 41|12@1+ (0.2,0) [0|0] "V" Vector__XXX
 SG_ PCS_chgInputNGVrms m3 : 53|9@1+ (1,0) [0|0] "V" Vector__XXX
 SG_ PCS_chgInputFrequencyL1N m4 : 8|12@1+ (0.01,40) [0|0] "Hz" Vector__XXX
 SG_ PCS_chgInputFrequencyL2N m4 : 20|12@1+ (0.01,40) [0|0] "Hz" Vector__XXX
 SG_ PCS_chgInputFrequencyL3N m4 : 32|12@1+ (0.01,40) [0|0] "Hz" Vector__XXX
 SG_ PCS_chgInternalPhaseConfig m4 : 44|3@1+ (1,0) [0|0] "" Vector__XXX
 SG_ PCS_chgOutputV m4 : 48|12@1+ (0.146484,0) [0|0] "V" Vector__XXX
 SG_ PCS_chgPhAState m5 : 5|4@1+ (1,0) [0|0] "" Vector__XXX
 SG_ PCS_chgPhBState m5 : 9|4@1+ (1,0) [0|0] "" Vector__XXX
 SG_ PCS_chgPhCState m5 : 13|4@1+ (1,0) [0|0] "" Vector__XXX
 SG_ PCS_chgPhALastShutdownReason m5 : 17|5@1+ (1,0) [0|0] "" Vector__XXX
 SG_ PCS_chgPhBLastShutdownReason m5 : 22|5@1+ (1,0) [0|0] "" Vector__XXX
 SG_ PCS_chgPhCLastShutdownReason m5 : 27|5@1+ (1,0) [0|0] "" Vector__XXX
 SG_ PCS_chgPhARetryCount m5 : 32|3@1+ (1,0) [0|0] "" Vector__XXX
 SG_ PCS_chgPhBRetryCount m5 : 35|3@1+ (1,0) [0|0] "" Vector__XXX
 SG_ PCS_chgPhCRetryCount m5 : 38|3@1+ (1,0) [0|0] "" Vector__XXX
 SG_ PCS_chgRetryCount m5 : 41|3@1+ (1,0) [0|0] "" Vector__XXX
 SG_ PCS_chgPhManCurrentToDist m5 : 44|10@1+ (0.1,0) [0|0] "A" Vector__XXX
 SG_ PCS_chgL1NPllLocked m5 : 54|1@1+ (1,0) [0|0] "" Vector__XXX
 SG_ PCS_chgL2NPllLocked m5 : 55|1@1+ (1,0) [0|0] "" Vector__XXX
 SG_ PCS_chgL3NPllLocked m5 : 56|1@1+ (1,0) [0|0] "" Vector__XXX
 SG_ PCS_chgL1L2PllLocked m5 : 57|1@1+ (1,0) [0|0] "" Vector__XXX
 SG_ PCS_chgNgPllLocked m5 : 58|1@1+ (1,0) [0|0] "" Vector__XXX
 SG_ PCS_chgPhManOptimalPhsToUse m5 : 59|2@1+ (1,0) [0|0] "" Vector__XXX
 SG_ PCS_chg5VL1Enable m5 : 61|1@1+ (1,0) [0|0] "" Vector__XXX
 SG_ PCS_dcdcMaxLvOutputCurrent m6 : 28|12@1+ (0.1,0) [0|0] "A" Vector__XXX
 SG_ PCS_dcdcCurrentLimit m6 : 40|12@1+ (0.1,0) [0|0] "A" Vector__XXX
 SG_ PCS_dcdcLvOutputCurrentTempLimit m6 : 52|12@1+ (0.1,0) [0|0] "A" Vector__XXX
 SG_ PCS_dcdcUnifiedCommand m7 : 5|10@1+ (0.001,0) [0|0] "1" Vector__XXX
 SG_ PCS_dcdcCLAControllerOutput m7 : 16|10@1+ (0.001,0) [0|0] "1" Vector__XXX
 SG_ PCS_dcdcTankVoltage m7 : 26|11@1- (1,0) [0|0] "V" Vector__XXX
 SG_ PCS_dcdcTankVoltageTarget m7 : 37|10@1+ (1,0) [0|0] "V" Vector__XXX
 SG_ PCS_dcdcClaCurrentFreq m7 : 48|12@1+ (0.0976563,0) [0|0] "kHz" Vector__XXX
 SG_ PCS_dcdcTCommMeasured m8 : 8|16@1- (0.00195313,0) [0|0] "us" Vector__XXX
 SG_ PCS_dcdcShortTimeUs m8 : 24|16@1+ (0.000488281,0) [0|0] "us" Vector__XXX
 SG_ PCS_dcdcHalfPeriodUs m8 : 40|16@1+ (0.000488281,0) [0|0] "us" Vector__XXX
 SG_ PCS_cpu2BootState m9 : 5|2@1+ (1,0) [0|0] "" Vector__XXX
 SG_ PCS_acChargeSelfTestState m9 : 7|1@1+ (1,0) [0|0] "" Vector__XXX
 SG_ PCS_1V5Min10s m9 : 8|11@1+ (0.001,0) [0|0] "V" Vector__XXX
 SG_ PCS_1V5Max10s m9 : 19|11@1+ (0.001,0) [0|0] "V" Vector__XXX
 SG_ PCS_1V2Min10s m9 : 32|11@1+ (0.001,0) [0|0] "V" Vector__XXX
 SG_ PCS_1V2Max10s m9 : 43|11@1+ (0.001,0) [0|0] "V" Vector__XXX
 SG_ PCS_numAlertsSet m9 : 56|7@1+ (1,0) [0|0] "" Vector__XXX
 SG_ PCS_chgPhAIntBusVMin10s m10 : 5|9@1+ (1,0) [0|0] "V" Vector__XXX
 SG_ PCS_chgPhAIntBusVMax10s m10 : 14|9@1+ (1,0) [0|0] "V" Vector__XXX
 SG_ PCS_chgPhAPchgVoltDeltaMax10s m10 : 23|8@1+ (0.5,0) [0|0] "V" Vector__XXX
 SG_ PCS_chgPhALifetimekWh m10 : 31|24@1+ (0.01,0) [0|0] "kWh" Vector__XXX
 SG_ PCS_chgPhATransientRetryCount m10 : 55|9@1+ (0.1,0) [0|0] "-" Vector__XXX
 SG_ PCS_chgPhBIntBusVMin10s m11 : 5|9@1+ (1,0) [0|0] "V" Vector__XXX
 SG_ PCS_chgPhBIntBusVMax10s m11 : 14|9@1+ (1,0) [0|0] "V" Vector__XXX
 SG_ PCS_chgPhBPchgVoltDeltaMax10s m11 : 23|8@1+ (0.5,0) [0|0] "V" Vector__XXX
 SG_ PCS_chgPhBLifetimekWh m11 : 31|24@1+ (0.01,0) [0|0] "kWh" Vector__XXX
 SG_ PCS_chgPhBTransientRetryCount m11 : 55|9@1+ (0.1,0) [0|0] "-" Vector__XXX
 SG_ PCS_chgPhCIntBusVMin10s m12 : 5|9@1+ (1,0) [0|0] "V" Vector__XXX
 SG_ PCS_chgPhCIntBusVMax10s m12 : 14|9@1+ (1,0) [0|0] "V" Vector__XXX
 SG_ PCS_chgPhCPchgVoltDeltaMax10s m12 : 23|8@1+ (0.5,0) [0|0] "V" Vector__XXX
 SG_ PCS_chgPhCLifetimekWh m12 : 31|24@1+ (0.01,0) [0|0] "kWh" Vector__XXX
 SG_ PCS_chgPhCTransientRetryCount m12 : 55|9@1+ (0.1,0) [0|0] "-" Vector__XXX
 SG_ PCS_chgInputL1NVPeak10s m13 : 5|9@1+ (1,0) [0|0] "V" Vector__XXX
 SG_ PCS_chgInputL2NVPeak10s m13 : 14|9@1+ (1,0) [0|0] "V" Vector__XXX
 SG_ PCS_chgInputL3NVPeak10s m13 : 23|9@1+ (1,0) [0|0] "V" Vector__XXX
 SG_ PCS_chgInputFreqWobblePHAPeak m13 : 32|8@1+ (0.01,0) [0|0] "Hz" Vector__XXX
 SG_ PCS_chgInputFreqWobblePHBPeak m13 : 40|8@1+ (0.01,0) [0|0] "Hz" Vector__XXX
 SG_ PCS_chgInputFreqWobblePHCPeak m13 : 48|8@1+ (0.01,0) [0|0] "Hz" Vector__XXX
 SG_ PCS_dLogPhAChannel1Content m14 : 5|2@1+ (1,0) [0|0] "" Vector__XXX
 SG_ PCS_dLogPhBChannel1Content m14 : 8|2@1+ (1,0) [0|0] "" Vector__XXX
 SG_ PCS_dLogPhCChannel1Content m14 : 10|2@1+ (1,0) [0|0] "" Vector__XXX
 SG_ PCS_dLogPhAChannel1Data m14 : 16|16@1- (0.02,0) [0|0] "-" Vector__XXX
 SG_ PCS_dLogPhBChannel1Data m14 : 32|16@1- (0.02,0) [0|0] "-" Vector__XXX
 SG_ PCS_dLogPhCChannel1Data m14 : 48|16@1- (0.02,0) [0|0] "-" Vector__XXX
 SG_ PCS_dLogPhAChannel2Content m15 : 5|2@1+ (1,0) [0|0] "" Vector__XXX
 SG_ PCS_dLogPhBChannel2Content m15 : 8|2@1+ (1,0) [0|0] "" Vector__XXX
 SG_ PCS_dLogPhCChannel2Content m15 : 10|2@1+ (1,0) [0|0] "" Vector__XXX
 SG_ PCS_dLogPhAChannel2Data m15 : 16|16@1- (0.02,0) [0|0] "-" Vector__XXX
 SG_ PCS_dLogPhBChannel2Data m15 : 32|16@1- (0.02,0) [0|0] "-" Vector__XXX
 SG_ PCS_dLogPhCChannel2Data m15 : 48|16@1- (0.02,0) [0|0] "-" Vector__XXX
 SG_ PCS_dLogPhAChannel3Content m16 : 5|2@1+ (1,0) [0|0] "" Vector__XXX
 SG_ PCS_dLogPhBChannel3Content m16 : 8|2@1+ (1,0) [0|0] "" Vector__XXX
 SG_ PCS_dLogPhCChannel3Content m16 : 10|2@1+ (1,0) [0|0] "" Vector__XXX
 SG_ PCS_dLogPhAChannel3Data m16 : 16|16@1- (0.02,0) [0|0] "-" Vector__XXX
 SG_ PCS_dLogPhBChannel3Data m16 : 32|16@1- (0.02,0) [0|0] "-" Vector__XXX
 SG_ PCS_dLogPhCChannel3Data m16 : 48|16@1- (0.02,0) [0|0] "-" Vector__XXX
 SG_ PCS_dLogPhAChannel4Content m17 : 5|2@1+ (1,0) [0|0] "" Vector__XXX
 SG_ PCS_dLogPhBChannel4Content m17 : 8|2@1+ (1,0) [0|0] "" Vector__XXX
 SG_ PCS_dLogPhCChannel4Content m17 : 10|2@1+ (1,0) [0|0] "" Vector__XXX
 SG_ PCS_dLogPhAChannel4Data m17 : 16|16@1- (0.02,0) [0|0] "-" Vector__XXX
 SG_ PCS_dLogPhBChannel4Data m17 : 32|16@1- (0.02,0) [0|0] "-" Vector__XXX
 SG_ PCS_dLogPhCChannel4Data m17 : 48|16@1- (0.02,0) [0|0] "-" Vector__XXX
 SG_ PCS_dcdcIntervalMaxFrequency m18 : 8|12@1+ (1,0) [0|0] "kHz" Vector__XXX
 SG_ PCS_dcdcIntervalMaxHvBusVolt m18 : 24|13@1+ (0.1,0) [0|0] "V" Vector__XXX
 SG_ PCS_dcdcIntervalMaxLvBusVolt m18 : 37|9@1+ (0.1,0) [0|0] "V" Vector__XXX
 SG_ PCS_dcdcIntervalMaxLvOutputCurr m18 : 48|12@1+ (1,0) [0|0] "A" Vector__XXX
 SG_ PCS_dcdcIntervalMinFrequency m19 : 8|12@1+ (1,0) [0|0] "kHz" Vector__XXX
 SG_ PCS_dcdcIntervalMinHvBusVolt m19 : 24|13@1+ (0.1,0) [0|0] "V" Vector__XXX
 SG_ PCS_dcdcIntervalMinLvBusVolt m19 : 37|9@1+ (0.1,0) [0|0] "V" Vector__XXX
 SG_ PCS_dcdcIntervalMinLvOutputCurr m19 : 48|12@1+ (1,0) [0|0] "A" Vector__XXX
 SG_ PCS_chgPhANoFlowBucket m20 : 5|9@1+ (0.01,0) [0|0] "-" Vector__XXX
 SG_ PCS_chgPhBNoFlowBucket m20 : 14|9@1+ (0.01,0) [0|0] "-" Vector__XXX
 SG_ PCS_chgPhCNoFlowBucket m20 : 23|9@1+ (0.01,0) [0|0] "-" Vector__XXX
 SG_ PCS_chgInputL1NVdc m21 : 5|10@1- (1,0) [0|0] "V" Vector__XXX
 SG_ PCS_chgInputL2NVdc m21 : 16|10@1- (1,0) [0|0] "V" Vector__XXX
 SG_ PCS_chgInputL3NVdc m21 : 26|10@1- (1,0) [0|0] "V" Vector__XXX
 SG_ PCS_chgInputL1L2Vdc m21 : 36|10@1- (1,0) [0|0] "V" Vector__XXX
 SG_ PCS_chgInputNGVdc m21 : 46|10@1- (1,0) [0|0] "V" Vector__XXX
 SG_ PCS_dcdc12vSupportLifetimekWh m22 : 8|24@1+ (0.01,0) [0|0] "kWh" Vector__XXX

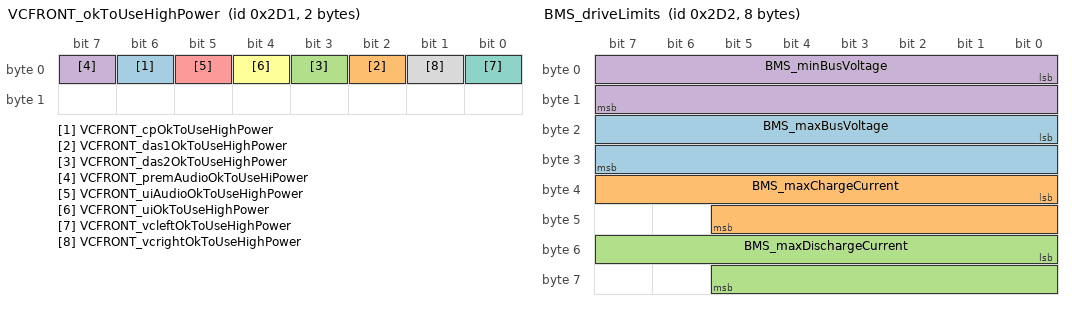
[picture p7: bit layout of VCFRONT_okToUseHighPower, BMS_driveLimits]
BO_ 721 VCFRONT_okToUseHighPower: 2 VEH
 SG_ VCFRONT_cpOkToUseHighPower : 6|1@1+ (1,0) [0|0] "" Vector__XXX
 SG_ VCFRONT_das1OkToUseHighPower : 2|1@1+ (1,0) [0|0] "" Vector__XXX
 SG_ VCFRONT_das2OkToUseHighPower : 3|1@1+ (1,0) [0|0] "" Vector__XXX
 SG_ VCFRONT_premAudioOkToUseHiPower : 7|1@1+ (1,0) [0|0] "" Vector__XXX
 SG_ VCFRONT_uiAudioOkToUseHighPower : 5|1@1+ (1,0) [0|0] "" Vector__XXX
 SG_ VCFRONT_uiOkToUseHighPower : 4|1@1+ (1,0) [0|0] "" Vector__XXX
 SG_ VCFRONT_vcleftOkToUseHighPower : 0|1@1+ (1,0) [0|0] "" Vector__XXX
 SG_ VCFRONT_vcrightOkToUseHighPower : 1|1@1+ (1,0) [0|0] "" Vector__XXX

BO_ 722 BMS_driveLimits: 8 VEH
 SG_ BMS_maxBusVoltage : 16|16@1+ (0.01,0) [0|430] "V" Vector__XXX
 SG_ BMS_maxChargeCurrent : 32|14@1+ (0.1,0) [0|1638.2] "A" Vector__XXX
 SG_ BMS_maxDischargeCurrent : 48|14@1+ (0.128,0) [0|2096.9] "A" Vector__XXX
 SG_ BMS_minBusVoltage : 0|16@1+ (0.01,0) [0|430] "V" Vector__XXX

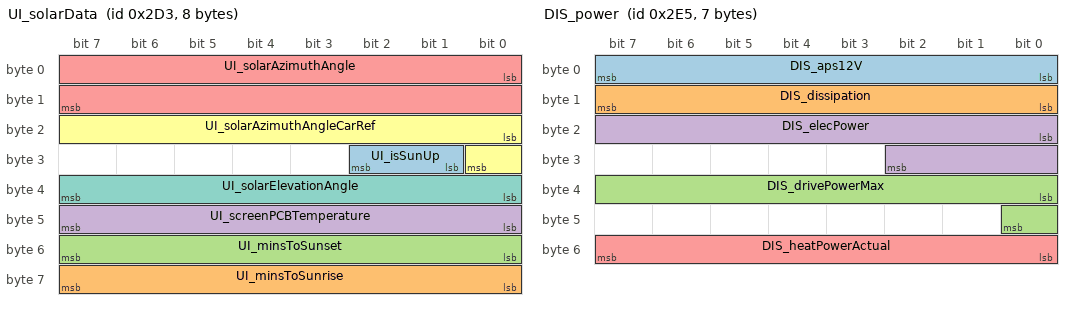
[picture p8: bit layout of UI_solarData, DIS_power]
BO_ 723 UI_solarData: 8 VEH
 SG_ UI_isSunUp : 25|2@1+ (1,0) [0|0] "" Vector__XXX
 SG_ UI_minsToSunrise : 56|8@1+ (10,0) [0|0] "min" Vector__XXX
 SG_ UI_minsToSunset : 48|8@1+ (10,0) [0|0] "min" Vector__XXX
 SG_ UI_screenPCBTemperature : 40|8@1- (0.5,40) [0|0] "degC" Vector__XXX
 SG_ UI_solarAzimuthAngle : 0|16@1- (1,0) [0|0] "degrees" Vector__XXX
 SG_ UI_solarAzimuthAngleCarRef : 16|9@1- (1,0) [0|0] "degrees" Vector__XXX
 SG_ UI_solarElevationAngle : 32|8@1- (1,0) [0|0] "degrees" Vector__XXX

BO_ 737 VCFRONT_status: 8 VEH
 SG_ VCFRONT_statusIndex M : 0|3@1+ (1,0) [0|6] "" Vector__XXX
 SG_ VCFRONT_12VARailStable m5 : 5|1@1+ (1,0) [0|1] "" Vector__XXX
 SG_ VCFRONT_12VBRailStable m5 : 6|1@1+ (1,0) [0|1] "" Vector__XXX
 SG_ VCFRONT_12VOverchargeCounter m4 : 16|4@1+ (1,0) [0|15] "" Vector__XXX
 SG_ VCFRONT_5VARailStable m5 : 3|1@1+ (1,0) [0|1] "" Vector__XXX
 SG_ VCFRONT_5VBRailStable m5 : 4|1@1+ (1,0) [0|1] "" Vector__XXX
 SG_ VCFRONT_AS8510Voltage m5 : 28|12@1+ (0.00544368,0) [0|22.2864] "V" Vector__XXX
 SG_ VCFRONT_ChargePumpVoltageStable m5 : 9|1@1+ (1,0) [0|1] "" Vector__XXX
 SG_ VCFRONT_HSDInitCompleteU13 m5 : 11|1@1+ (1,0) [0|1] "" Vector__XXX
 SG_ VCFRONT_HSDInitCompleteU16 m5 : 12|1@1+ (1,0) [0|1] "" Vector__XXX
 SG_ VCFRONT_IBSFault m4 : 15|1@1+ (1,0) [0|1] "" Vector__XXX
 SG_ VCFRONT_PCSMia m4 : 14|1@1+ (1,0) [0|1] "" Vector__XXX
 SG_ VCFRONT_PEResetLineState m5 : 10|1@1+ (1,0) [0|1] "" Vector__XXX
 SG_ VCFRONT_airCompressorStatus m0 : 25|3@1+ (1,0) [0|7] "" Vector__XXX
 SG_ VCFRONT_anyClosureOpen m0 : 49|1@1+ (1,0) [0|1] "" Vector__XXX
 SG_ VCFRONT_anyDoorOpen m0 : 50|1@1+ (1,0) [0|1] "" Vector__XXX
 SG_ VCFRONT_batterySMState m1 : 16|4@1+ (1,0) [0|8] "" Vector__XXX
 SG_ VCFRONT_chargeNeeded m4 : 13|1@1+ (1,0) [0|1] "" Vector__XXX
 SG_ VCFRONT_chillerDemandActive m3 : 26|1@1+ (1,0) [0|1] "" Vector__XXX
 SG_ VCFRONT_compPerfRecoveryLimited m3 : 27|1@1+ (1,0) [0|1] "" Vector__XXX
 SG_ VCFRONT_coolantFillRoutineStatus m3 : 50|2@1+ (1,0) [0|3] "" Vector__XXX
 SG_ VCFRONT_crashDetectedType m0 : 20|2@1+ (1,0) [0|2] "" Vector__XXX
 SG_ VCFRONT_crashState m0 : 22|2@1+ (1,0) [0|2] "" Vector__XXX
 SG_ VCFRONT_crashUnlockOverrideSet m0 : 24|1@1+ (1,0) [0|1] "" Vector__XXX
 SG_ VCFRONT_epasWakeLine m1 : 4|1@1+ (1,0) [0|1] "" Vector__XXX
 SG_ VCFRONT_freezeEvapITerm m3 : 24|1@1+ (1,0) [0|1] "" Vector__XXX
 SG_ VCFRONT_frunkAccessPost m0 : 62|1@1+ (1,0) [0|1] "" Vector__XXX
 SG_ VCFRONT_frunkInteriorRelSwitch m0 : 48|1@1+ (1,0) [0|1] "" Vector__XXX
 SG_ VCFRONT_frunkLatchStatus m0 : 3|4@1+ (1,0) [0|8] "" Vector__XXX
 SG_ VCFRONT_frunkLatchType m0 : 58|2@1+ (1,0) [0|2] "" Vector__XXX
 SG_ VCFRONT_hasLowRefrigerant m3 : 29|1@1+ (1,0) [0|1] "" Vector__XXX
 SG_ VCFRONT_headlampLeftFanStatus m0 : 60|1@1+ (1,0) [0|1] "" Vector__XXX
 SG_ VCFRONT_headlampRightFanStatus m0 : 61|1@1+ (1,0) [0|1] "" Vector__XXX
 SG_ VCFRONT_headlightLeftVPosition m0 : 28|10@1+ (1,0) [0|1023] "ticks" Vector__XXX
 SG_ VCFRONT_headlightRightVPosition m0 : 38|10@1+ (1,0) [0|1023] "ticks" Vector__XXX
 SG_ VCFRONT_homelinkCommStatus m2 : 48|2@1+ (1,0) [0|3] "" Vector__XXX
 SG_ VCFRONT_homelinkV2Response0 m2 : 8|8@1+ (1,0) [0|255] "" Vector__XXX
 SG_ VCFRONT_homelinkV2Response1 m2 : 16|8@1+ (1,0) [0|255] "" Vector__XXX
 SG_ VCFRONT_homelinkV2Response2 m2 : 24|8@1+ (1,0) [0|255] "" Vector__XXX
 SG_ VCFRONT_homelinkV2Response3 m2 : 32|8@1+ (1,0) [0|255] "" Vector__XXX
 SG_ VCFRONT_homelinkV2Response4 m2 : 40|8@1+ (1,0) [0|255] "" Vector__XXX
 SG_ VCFRONT_hornOn m0 : 51|1@1+ (1,0) [0|1] "" Vector__XXX
 SG_ VCFRONT_hvacPerfTestCommand m3 : 48|2@1+ (1,0) [0|2] "" Vector__XXX
 SG_ VCFRONT_iBoosterStateDBG m1 : 5|3@1+ (1,0) [0|4] "" Vector__XXX
 SG_ VCFRONT_iBoosterWakeLine m1 : 3|1@1+ (1,0) [0|1] "" Vector__XXX
 SG_ VCFRONT_isActiveHeatingBattery m0 : 63|1@1+ (1,0) [0|1] "" Vector__XXX
 SG_ VCFRONT_isColdStartRunning m3 : 30|1@1+ (1,0) [0|1] "" Vector__XXX
 SG_ VCFRONT_isEvapOperationAllowed m3 : 25|1@1+ (1,0) [0|1] "" Vector__XXX
 SG_ VCFRONT_isHeatPumpOilPurgeActive m3 : 31|1@1+ (1,0) [0|1] "" Vector__XXX
 SG_ VCFRONT_maxEvapHeatRejection m3 : 8|8@1+ (65,0) [0|16575] "W" Vector__XXX
 SG_ VCFRONT_minEvapHeatRejection m3 : 16|8@1+ (10,0) [0|2500] "W" Vector__XXX
 SG_ VCFRONT_pressureRefrigDischarge m3 : 40|8@1+ (0.125,0) [0|31.75] "bar" Vector__XXX
 SG_ VCFRONT_pressureRefrigSuction m3 : 32|7@1+ (0.125,0) [0|11.5] "bar" Vector__XXX
 SG_ VCFRONT_radarHeaterState m0 : 52|3@1+ (1,0) [0|4] "" Vector__XXX
 SG_ VCFRONT_railAState m5 : 7|1@1+ (1,0) [0|1] "" Vector__XXX
 SG_ VCFRONT_railBState m5 : 8|1@1+ (1,0) [0|1] "" Vector__XXX
 SG_ VCFRONT_refrigFillRoutineStatus m3 : 52|2@1+ (1,0) [0|3] ""  Receiver
 SG_ VCFRONT_reverseBatteryFault m4 : 30|1@1+ (1,0) [0|1] "" Vector__XXX
 SG_ VCFRONT_shortedCellFaultCounter m4 : 44|3@1+ (1,0) [0|7] "" Vector__XXX
 SG_ VCFRONT_silentWakeIBSCurrent m4 : 32|12@1- (0.1,-204.7) [-409.5|0] "mA" Vector__XXX
 SG_ VCFRONT_sleepCurrent m1 : 32|12@1- (0.1,-204.7) [-409.5|0] "mA" Vector__XXX
 SG_ VCFRONT_tempCompTargetVoltage m4 : 3|10@1+ (0.01,9) [9|16] "V" Vector__XXX
 SG_ VCFRONT_timeSpentSleeping m1 : 24|8@1+ (1,0) [0|255] "s" Vector__XXX
 SG_ VCFRONT_vbatMonitorVoltage m5 : 16|12@1+ (0.00544368,0) [0|22.2864] "V" Vector__XXX
 SG_ VCFRONT_vbatProt m5 : 40|12@1+ (0.00544368,0) [0|22.2919] "V" Vector__XXX
 SG_ VCFRONT_vehicleStatusDBG m1 : 8|5@1+ (1,0) [0|17] "" Vector__XXX
 SG_ VCFRONT_voltageDropCounter m4 : 20|4@1+ (1,0) [0|15] "" Vector__XXX
 SG_ VCFRONT_voltageFloorReachedCount m4 : 24|4@1+ (1,0) [0|15] "" Vector__XXX
 SG_ VCFRONT_voltageProfile m4 : 28|2@1+ (1,0) [0|3] "" Vector__XXX
 SG_ VCFRONT_wiperPosition m0 : 12|3@1+ (1,0) [0|4] "" Vector__XXX
 SG_ VCFRONT_wiperSpeed m0 : 8|4@1+ (1,0) [0|8] "" Vector__XXX
 SG_ VCFRONT_wiperState m0 : 16|4@1+ (1,0) [0|12] "" Vector__XXX

BO_ 741 DIS_power: 7 VEH
 SG_ DIS_aps12V : 0|8@1+ (0.1,0) [0|0] "V" Vector__XXX
 SG_ DIS_dissipation : 8|8@1+ (125,0) [0|0] "W" Vector__XXX
 SG_ DIS_drivePowerMax : 32|9@1+ (1,0) [0|0] "kW" Vector__XXX
 SG_ DIS_elecPower : 16|11@1- (0.5,0) [0|0] "kW" Vector__XXX
 SG_ DIS_heatPowerActual : 48|8@1+ (0.08,0) [0|0] "kW" Vector__XXX

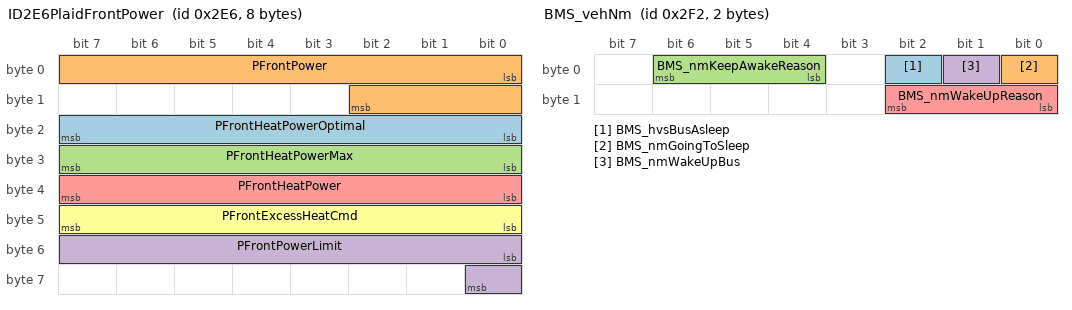
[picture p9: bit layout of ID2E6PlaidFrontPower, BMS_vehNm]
BO_ 742 ID2E6PlaidFrontPower: 8 VehicleBus
 SG_ PFrontHeatPowerOptimal : 16|8@1+ (0.08,0) [0|20.4] "kW"  Receiver
 SG_ PFrontPower : 0|11@1- (0.5,0) [-512|511.5] "kW"  Receiver
 SG_ PFrontHeatPowerMax : 24|8@1+ (0.08,0) [0|20.4] "kW"  Receiver
 SG_ PFrontPowerLimit : 48|9@1+ (1,0) [0|400] "kW"  Receiver
 SG_ PFrontHeatPower : 32|8@1+ (0.08,0) [0|20.4] "kW"  Receiver
 SG_ PFrontExcessHeatCmd : 40|8@1+ (0.08,0) [0|20] "kW"  Receiver

BO_ 744 EPBR_status: 8 VEH
 SG_ EPBR_blockDrive : 51|1@1+ (1,0) [0|0] "" Vector__XXX
 SG_ EPBR_bothDisconnected : 50|1@1+ (1,0) [0|0] "" Vector__XXX
 SG_ EPBR_brakeDiscWipeRequest : 30|2@1+ (1,0) [0|0] "" Vector__XXX
 SG_ EPBR_brakeHWConfigMismatch : 19|1@1+ (1,0) [0|0] "" Vector__XXX
 SG_ EPBR_brakeLight : 18|1@1+ (1,0) [0|0] "" Vector__XXX
 SG_ EPBR_cdpRequest : 27|1@1+ (1,0) [0|0] "" Vector__XXX
 SG_ EPBR_espPowerRequest : 46|1@1+ (1,0) [0|0] "" Vector__XXX
 SG_ EPBR_hornRequest : 48|1@1+ (1,0) [0|0] "" Vector__XXX
 SG_ EPBR_okToPark : 47|1@1+ (1,0) [0|0] "" Vector__XXX
 SG_ EPBR_requestUserConfirmation : 21|1@1+ (1,0) [0|0] "" Vector__XXX
 SG_ EPBR_statusChecksum : 56|8@1+ (1,0) [0|0] "" Vector__XXX
 SG_ EPBR_statusCounter : 52|4@1+ (1,0) [0|0] "" Vector__XXX
 SG_ EPBR_summonEnabled : 17|1@1+ (1,0) [0|0] "" Vector__XXX
 SG_ EPBR_systemStatus : 0|4@1+ (1,0) [0|0] "" Vector__XXX
 SG_ EPBR_telltale : 16|1@1+ (1,0) [0|0] "" Vector__XXX
 SG_ EPBR_uiButtonAvailable : 20|1@1+ (1,0) [0|0] "" Vector__XXX
 SG_ EPBR_updateMode : 24|1@1+ (1,0) [0|0] "" Vector__XXX
 SG_ EPBR_winchModeActive : 23|1@1+ (1,0) [0|0] "" Vector__XXX
 SG_ EPBR_winchModeAvailable : 49|1@1+ (1,0) [0|0] "" Vector__XXX
 SG_ EPBR_winchModeTimer : 32|12@1+ (1,0) [0|0] "" Vector__XXX

BO_ 753 VCFRONT_eFuseDebugStatus: 8 VEH
 SG_ VCFRONT_eFuseDebugStatusIndex M : 0|5@1+ (1,0) [0|0] "" Vector__XXX
 SG_ VCFRONT_rightControllerState m0 : 8|2@1+ (1,0) [0|0] "" Vector__XXX
 SG_ VCFRONT_rightControllerFault m0 : 10|1@1+ (1,0) [0|0] "" Vector__XXX
 SG_ VCFRONT_vcrightSelfTestResult m0 : 11|4@1+ (1,0) [0|0] "" Vector__XXX
 SG_ VCFRONT_rightControllerTemp m0 : 15|11@1+ (0.125,-40) [0|0] "degC" Vector__XXX
 SG_ VCFRONT_rightControllerVoltage m0 : 31|16@1+ (0.1,0) [0|0] "V" Vector__XXX
 SG_ VCFRONT_rightControllerCurrent m0 : 47|16@1+ (0.1,0) [0|0] "A" Vector__XXX
 SG_ VCFRONT_leftControllerState m1 : 8|2@1+ (1,0) [0|0] "" Vector__XXX
 SG_ VCFRONT_leftControllerFault m1 : 10|1@1+ (1,0) [0|0] "" Vector__XXX
 SG_ VCFRONT_vcleftSelfTestResult m1 : 11|4@1+ (1,0) [0|0] "" Vector__XXX
 SG_ VCFRONT_leftControllerTemp m1 : 15|11@1+ (0.125,-40) [0|0] "degC" Vector__XXX
 SG_ VCFRONT_leftControllerVoltage m1 : 31|16@1+ (0.1,0) [0|0] "V" Vector__XXX
 SG_ VCFRONT_leftControllerCurrent m1 : 47|16@1+ (0.1,0) [0|0] "A" Vector__XXX
 SG_ VCFRONT_PCSState m2 : 8|2@1+ (1,0) [0|0] "" Vector__XXX
 SG_ VCFRONT_PCSFault m2 : 10|1@1+ (1,0) [0|0] "" Vector__XXX
 SG_ VCFRONT_pcsSelfTestResult m2 : 11|4@1+ (1,0) [0|0] "" Vector__XXX
 SG_ VCFRONT_PCSTemp m2 : 15|11@1+ (0.125,-40) [0|0] "degC" Vector__XXX
 SG_ VCFRONT_PCSVoltage m2 : 31|16@1+ (0.1,0) [0|0] "V" Vector__XXX
 SG_ VCFRONT_PCSCurrent m2 : 47|16@1- (0.1,0) [0|0] "A" Vector__XXX
 SG_ VCFRONT_iBoosterState m3 : 8|2@1+ (1,0) [0|0] "" Vector__XXX
 SG_ VCFRONT_iBoosterFault m3 : 10|1@1+ (1,0) [0|0] "" Vector__XXX
 SG_ VCFRONT_iBoosterSelfTestResult m3 : 11|4@1+ (1,0) [0|0] "" Vector__XXX
 SG_ VCFRONT_iBoosterTemp m3 : 15|11@1+ (0.125,-40) [0|0] "degC" Vector__XXX
 SG_ VCFRONT_iBoosterVoltage m3 : 31|16@1+ (0.1,0) [0|0] "V" Vector__XXX
 SG_ VCFRONT_iBoosterCurrent m3 : 47|16@1+ (0.1,0) [0|0] "A" Vector__XXX
 SG_ VCFRONT_EPAS3PState m4 : 8|2@1+ (1,0) [0|0] "" Vector__XXX
 SG_ VCFRONT_EPAS3PFault m4 : 10|1@1+ (1,0) [0|0] "" Vector__XXX
 SG_ VCFRONT_EPAS3PSelfTestResult m4 : 11|4@1+ (1,0) [0|0] "" Vector__XXX
 SG_ VCFRONT_EPAS3PTemp m4 : 15|11@1+ (0.125,-40) [0|0] "degC" Vector__XXX
 SG_ VCFRONT_EPAS3PVoltage m4 : 31|16@1+ (0.1,0) [0|0] "V" Vector__XXX
 SG_ VCFRONT_EPAS3PCurrent m4 : 47|16@1+ (0.1,0) [0|0] "A" Vector__XXX
 SG_ VCFRONT_EPAS3SState m5 : 8|2@1+ (1,0) [0|0] "" Vector__XXX
 SG_ VCFRONT_EPAS3SFault m5 : 10|1@1+ (1,0) [0|0] "" Vector__XXX
 SG_ VCFRONT_EPAS3SSelfTestResult m5 : 11|4@1+ (1,0) [0|0] "" Vector__XXX
 SG_ VCFRONT_EPAS3STemp m5 : 15|11@1+ (0.125,-40) [0|0] "degC" Vector__XXX
 SG_ VCFRONT_EPAS3SVoltage m5 : 31|16@1+ (0.1,0) [0|0] "V" Vector__XXX
 SG_ VCFRONT_EPAS3SCurrent m5 : 47|16@1+ (0.1,0) [0|0] "A" Vector__XXX
 SG_ VCFRONT_ESPMotorState m6 : 8|2@1+ (1,0) [0|0] "" Vector__XXX
 SG_ VCFRONT_ESPMotorFault m6 : 10|1@1+ (1,0) [0|0] "" Vector__XXX
 SG_ VCFRONT_ESPMotorSelfTestResult m6 : 11|4@1+ (1,0) [0|0] "" Vector__XXX
 SG_ VCFRONT_ESPMotorTemp m6 : 15|11@1+ (0.125,-40) [0|0] "degC" Vector__XXX
 SG_ VCFRONT_ESPMotorVoltage m6 : 31|16@1+ (0.1,0) [0|0] "V" Vector__XXX
 SG_ VCFRONT_ESPMotorCurrent m6 : 47|16@1+ (0.1,0) [0|0] "A" Vector__XXX
 SG_ VCFRONT_ESPValveState m7 : 8|2@1+ (1,0) [0|0] "" Vector__XXX
 SG_ VCFRONT_ESPValveFault m7 : 10|1@1+ (1,0) [0|0] "" Vector__XXX
 SG_ VCFRONT_ESPValveTemp m7 : 12|11@1+ (0.125,-40) [0|0] "degC" Vector__XXX
 SG_ VCFRONT_ESPValveVoltage m7 : 28|16@1+ (0.1,0) [0|0] "V" Vector__XXX
 SG_ VCFRONT_ESPValveCurrent m7 : 44|16@1+ (0.1,0) [0|0] "A" Vector__XXX
 SG_ VCFRONT_autopilot1State m8 : 8|2@1+ (1,0) [0|0] "" Vector__XXX
 SG_ VCFRONT_autopilot1Fault m8 : 10|1@1+ (1,0) [0|0] "" Vector__XXX
 SG_ VCFRONT_autopilot1Temp m8 : 11|11@1+ (0.125,-40) [0|0] "degC" Vector__XXX
 SG_ VCFRONT_autopilot1Voltage m8 : 27|16@1+ (0.1,0) [0|0] "V" Vector__XXX
 SG_ VCFRONT_autopilot1Current m8 : 43|16@1+ (0.1,0) [0|0] "A" Vector__XXX
 SG_ VCFRONT_autopilot2State m9 : 8|2@1+ (1,0) [0|0] "" Vector__XXX
 SG_ VCFRONT_autopilot2Fault m9 : 10|1@1+ (1,0) [0|0] "" Vector__XXX
 SG_ VCFRONT_autopilot2Temp m9 : 11|11@1+ (0.125,-40) [0|0] "degC" Vector__XXX
 SG_ VCFRONT_autopilot2Voltage m9 : 27|16@1+ (0.1,0) [0|0] "V" Vector__XXX
 SG_ VCFRONT_autopilot2Current m9 : 43|16@1+ (0.1,0) [0|0] "A" Vector__XXX
 SG_ VCFRONT_sleepBypassState m10 : 8|1@1+ (1,0) [0|0] "" Vector__XXX
 SG_ VCFRONT_sleepBypassFault m10 : 9|1@1+ (1,0) [0|0] "" Vector__XXX
 SG_ VCFRONT_sleepBypassVoltage m10 : 10|16@1+ (0.1,0) [0|0] "V" Vector__XXX
 SG_ VCFRONT_sleepBypassCurrent m10 : 26|16@1+ (0.1,0) [0|0] "A" Vector__XXX
 SG_ VCFRONT_uiAudioState m11 : 5|1@1+ (1,0) [0|0] "" Vector__XXX
 SG_ VCFRONT_uiAudioFault m11 : 6|1@1+ (1,0) [0|0] "" Vector__XXX
 SG_ VCFRONT_uiAudioCurrent m11 : 8|16@1+ (0.1,0) [0|0] "A" Vector__XXX
 SG_ VCFRONT_uiState m11 : 24|1@1+ (1,0) [0|0] "" Vector__XXX
 SG_ VCFRONT_uiFault m11 : 25|1@1+ (1,0) [0|0] "" Vector__XXX
 SG_ VCFRONT_uiCurrent m11 : 32|16@1+ (0.1,0) [0|0] "A" Vector__XXX
 SG_ VCFRONT_headlampLeftState m12 : 8|1@1+ (1,0) [0|0] "" Vector__XXX
 SG_ VCFRONT_headlampLeftFault m12 : 9|1@1+ (1,0) [0|0] "" Vector__XXX
 SG_ VCFRONT_headlampLeftCurrent m12 : 10|10@1+ (0.1,0) [0|0] "A" Vector__XXX
 SG_ VCFRONT_headlampLeftVoltage m12 : 20|8@1+ (0.1,0) [0|0] "V" Vector__XXX
 SG_ VCFRONT_headlampRightState m12 : 28|1@1+ (1,0) [0|0] "" Vector__XXX
 SG_ VCFRONT_headlampRightFault m12 : 29|1@1+ (1,0) [0|0] "" Vector__XXX
 SG_ VCFRONT_headlampRightCurrent m12 : 30|10@1+ (0.1,0) [0|0] "A" Vector__XXX
 SG_ VCFRONT_headlampRightVoltage m12 : 40|8@1+ (0.1,0) [0|0] "V" Vector__XXX
 SG_ VCFRONT_headlampLeftTemperature m12 : 48|8@1- (1,-40) [0|0] "degC" Vector__XXX
 SG_ VCFRONT_headlampRightTemperature m12 : 56|8@1- (1,-40) [0|0] "degC" Vector__XXX
 SG_ VCFRONT_vbatFusedHighState m13 : 8|1@1+ (1,0) [0|0] "" Vector__XXX
 SG_ VCFRONT_vbatFusedHighFault m13 : 9|1@1+ (1,0) [0|0] "" Vector__XXX
 SG_ VCFRONT_vbatFusedSelfTestResult m13 : 10|4@1+ (1,0) [0|0] "" Vector__XXX
 SG_ VCFRONT_vbatFusedHighTemp m13 : 14|11@1+ (0.125,-40) [0|0] "degC" Vector__XXX
 SG_ VCFRONT_vbatFusedHighVoltage m13 : 30|16@1+ (0.1,0) [0|0] "V" Vector__XXX
 SG_ VCFRONT_vbatFusedHighCurrent m13 : 46|16@1+ (0.1,0) [0|0] "A" Vector__XXX
 SG_ VCFRONT_pump1AndFanState m14 : 5|1@1+ (1,0) [0|0] "" Vector__XXX
 SG_ VCFRONT_pump1AndFanCurrent m14 : 6|16@1+ (0.1,0) [0|0] "A" Vector__XXX
 SG_ VCFRONT_pump1AndFanVoltage m14 : 22|12@1+ (0.1,0) [0|0] "V" Vector__XXX
 SG_ VCFRONT_pump2AndAirCompState m14 : 34|1@1+ (1,0) [0|0] "" Vector__XXX
 SG_ VCFRONT_pump2AndAirCompCurrent m14 : 35|16@1+ (0.1,0) [0|0] "A" Vector__XXX
 SG_ VCFRONT_pump2AndAirCompVoltage m14 : 51|12@1+ (0.1,0) [0|0] "V" Vector__XXX
 SG_ VCFRONT_railA_12v m15 : 8|12@1+ (0.00544368,0) [0|0] "V" Vector__XXX
 SG_ VCFRONT_railB_12v m15 : 20|12@1+ (0.00544368,0) [0|0] "V" Vector__XXX
 SG_ VCFRONT_railA_5v m15 : 32|12@1+ (0.00544368,0) [0|0] "V" Vector__XXX
 SG_ VCFRONT_railB_5v m15 : 44|12@1+ (0.00544368,0) [0|0] "V" Vector__XXX
 SG_ VCFRONT_eFuseLockoutVoltage m16 : 8|12@1+ (0.00544368,0) [0|0] "V" Vector__XXX
 SG_ VCFRONT_ChargePumpVoltage m16 : 24|16@1+ (0.00544368,0) [0|0] "V" Vector__XXX
 SG_ VCFRONT_vbatProt m16 : 40|12@1+ (0.00544368,0) [0|0] "V" Vector__XXX

BO_ 754 BMS_vehNm: 2 VEH
 SG_ BMS_hvsBusAsleep : 2|1@1+ (1,0) [0|0] "" Vector__XXX
 SG_ BMS_nmGoingToSleep : 0|1@1+ (1,0) [0|0] "" Vector__XXX
 SG_ BMS_nmKeepAwakeReason : 4|3@1+ (1,0) [0|0] "" Vector__XXX
 SG_ BMS_nmWakeUpBus : 1|1@1+ (1,0) [0|0] "" Vector__XXX
 SG_ BMS_nmWakeUpReason : 8|3@1+ (1,0) [0|0] "" Vector__XXX

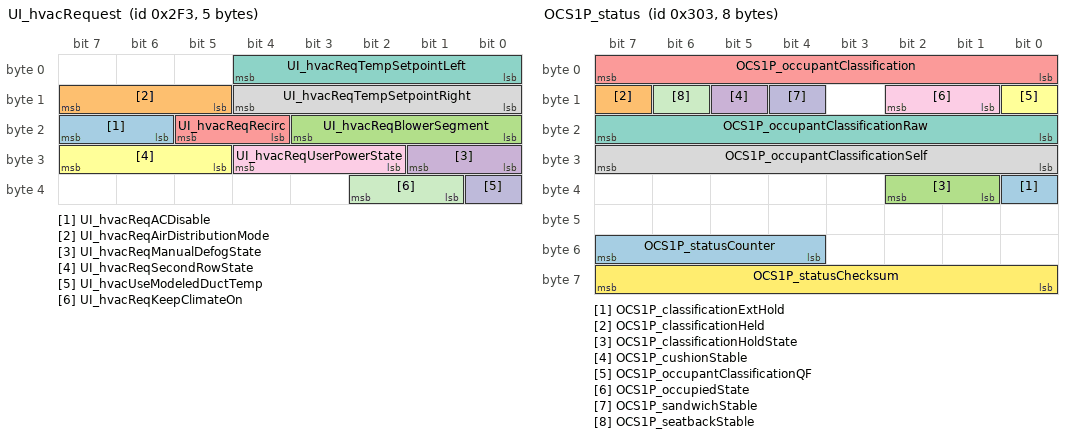
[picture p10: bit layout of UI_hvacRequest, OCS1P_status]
BO_ 755 UI_hvacRequest: 5 VEH
 SG_ UI_hvacReqACDisable : 22|2@1+ (1,0) [0|0] "" Vector__XXX
 SG_ UI_hvacReqAirDistributionMode : 13|3@1+ (1,0) [0|0] "" Vector__XXX
 SG_ UI_hvacReqBlowerSegment : 16|4@1+ (1,0) [0|0] "" Vector__XXX
 SG_ UI_hvacReqManualDefogState : 24|2@1+ (1,0) [0|0] "" Vector__XXX
 SG_ UI_hvacReqRecirc : 20|2@1+ (1,0) [0|0] "" Vector__XXX
 SG_ UI_hvacReqSecondRowState : 29|3@1+ (1,0) [0|0] "" Vector__XXX
 SG_ UI_hvacReqTempSetpointLeft : 0|5@1+ (0.5,15) [0|0] "degC" Vector__XXX
 SG_ UI_hvacReqTempSetpointRight : 8|5@1+ (0.5,15) [0|0] "degC" Vector__XXX
 SG_ UI_hvacReqUserPowerState : 26|3@1+ (1,0) [0|0] "" Vector__XXX
 SG_ UI_hvacUseModeledDuctTemp : 32|1@1+ (1,0) [0|0] "" Vector__XXX
 SG_ UI_hvacReqKeepClimateOn : 33|2@1+ (1,0) [0|3] "" Vector__XXX

BO_ 768 BMS_info: 8 VEH
 SG_ BMS_infoIndex M : 0|8@1+ (1,0) [0|0] "" Vector__XXX
 SG_ BMS_buildType m10 : 8|3@1+ (1,0) [0|0] "" Vector__XXX
 SG_ BMS_buildConfigId m10 : 16|16@1+ (1,0) [0|0] "" Vector__XXX
 SG_ BMS_hardwareId m10 : 32|16@1+ (1,0) [0|0] "" Vector__XXX
 SG_ BMS_componentId m10 : 48|16@1+ (1,0) [0|0] "" Vector__XXX
 SG_ BMS_pcbaId m11 : 16|8@1+ (1,0) [0|0] "" Vector__XXX
 SG_ BMS_assemblyId m11 : 24|8@1+ (1,0) [0|0] "" Vector__XXX
 SG_ BMS_usageId m11 : 32|16@1+ (1,0) [0|0] "" Vector__XXX
 SG_ BMS_subUsageId m11 : 48|16@1+ (1,0) [0|0] "" Vector__XXX
 SG_ BMS_platformType m13 : 8|8@1+ (1,0) [0|0] "" Vector__XXX
 SG_ BMS_appCrc m13 : 32|32@1+ (1,0) [0|0] "" Vector__XXX
 SG_ BMS_appGitHash m17 : 10|54@1+ (4,0) [0|0] "" Vector__XXX
 SG_ BMS_bootGitHash m18 : 10|54@1+ (4,0) [0|0] "" Vector__XXX
 SG_ BMS_bootUdsProtoVersion m20 : 8|8@1+ (1,0) [0|0] "" Vector__XXX
 SG_ BMS_bootCrc m20 : 32|32@1+ (1,0) [0|0] "" Vector__XXX

BO_ 769 VCFRONT_info: 8 VEH
 SG_ VCFRONT_infoIndex M : 0|8@1+ (1,0) [0|0] "" Vector__XXX
 SG_ VCFRONT_infoBuildType m10 : 8|3@1+ (1,0) [0|0] "" Vector__XXX
 SG_ VCFRONT_infoBuildConfigId m10 : 16|16@1+ (1,0) [0|0] "" Vector__XXX
 SG_ VCFRONT_infoHardwareId m10 : 32|16@1+ (1,0) [0|0] "" Vector__XXX
 SG_ VCFRONT_infoComponentId m10 : 48|16@1+ (1,0) [0|0] "" Vector__XXX
 SG_ VCFRONT_infoPcbaId m11 : 8|8@1+ (1,0) [0|0] "" Vector__XXX
 SG_ VCFRONT_infoAssemblyId m11 : 16|8@1+ (1,0) [0|0] "" Vector__XXX
 SG_ VCFRONT_infoUsageId m11 : 24|16@1+ (1,0) [0|0] "" Vector__XXX
 SG_ VCFRONT_infoSubUsageId m11 : 40|16@1+ (1,0) [0|0] "" Vector__XXX
 SG_ VCFRONT_infoAppCrc m13 : 8|32@1+ (1,0) [0|0] "" Vector__XXX
 SG_ VCFRONT_hcmlAppCRC m16 : 32|32@1+ (1,0) [0|0] "" Vector__XXX
 SG_ VCFRONT_infoAppGitHash m17 : 10|54@1+ (4,0) [0|0] "" Vector__XXX
 SG_ VCFRONT_infoBootGitHash m18 : 10|54@1+ (4,0) [0|0] "" Vector__XXX
 SG_ VCFRONT_infoPlatformType m19 : 8|8@1+ (1,0) [0|0] "" Vector__XXX
 SG_ VCFRONT_infoBootUdsProtoVersion m20 : 8|16@1+ (1,0) [0|0] "" Vector__XXX
 SG_ VCFRONT_infoBootCrc m20 : 24|32@1+ (1,0) [0|0] "" Vector__XXX
 SG_ VCFRONT_hcmrAppCRC m23 : 32|32@1+ (1,0) [0|0] "" Vector__XXX
 SG_ VCFRONT_infoSubcomponent3 m24 : 32|32@1+ (1,0) [0|0] "" Vector__XXX
 SG_ VCFRONT_infoSubcomponent4 m31 : 32|32@1+ (1,0) [0|0] "" Vector__XXX
 SG_ VCFRONT_infoSubcomponent5 m32 : 32|32@1+ (1,0) [0|4294970000] ""  Receiver
 SG_ VCFRONT_infoSubcomponent6 m33 : 32|32@1+ (1,0) [0|4294970000] ""  Receiver

BO_ 770 VCLEFT_info: 8 VEH
 SG_ VCLEFT_infoIndex M : 0|8@1+ (1,0) [0|0] "" Vector__XXX
 SG_ VCLEFT_infoBuildType m10 : 8|3@1+ (1,0) [0|0] "" Vector__XXX
 SG_ VCLEFT_infoBuildConfigId m10 : 16|16@1+ (1,0) [0|0] "" Vector__XXX
 SG_ VCLEFT_infoHardwareId m10 : 32|16@1+ (1,0) [0|0] "" Vector__XXX
 SG_ VCLEFT_infoComponentId m10 : 48|16@1+ (1,0) [0|0] "" Vector__XXX
 SG_ VCLEFT_infoPcbaId m11 : 8|8@1+ (1,0) [0|0] "" Vector__XXX
 SG_ VCLEFT_infoAssemblyId m11 : 16|8@1+ (1,0) [0|0] "" Vector__XXX
 SG_ VCLEFT_infoUsageId m11 : 24|16@1+ (1,0) [0|0] "" Vector__XXX
 SG_ VCLEFT_infoSubUsageId m11 : 40|16@1+ (1,0) [0|0] "" Vector__XXX
 SG_ VCLEFT_infoAppCrc m13 : 8|32@1+ (1,0) [0|0] "" Vector__XXX
 SG_ VCLEFT_infoSubcomponent1 m16 : 32|32@1+ (1,0) [0|0] "" Vector__XXX
 SG_ VCLEFT_infoAppGitHash m17 : 10|54@1+ (4,0) [0|0] "" Vector__XXX
 SG_ VCLEFT_infoBootGitHash m18 : 10|54@1+ (4,0) [0|0] "" Vector__XXX
 SG_ VCLEFT_infoPlatformType m19 : 8|8@1+ (1,0) [0|0] "" Vector__XXX
 SG_ VCLEFT_infoBootUdsProtoVersion m20 : 8|16@1+ (1,0) [0|0] "" Vector__XXX
 SG_ VCLEFT_infoBootCrc m20 : 24|32@1+ (1,0) [0|0] "" Vector__XXX
 SG_ VCLEFT_swcAppCRC m23 : 32|32@1+ (1,0) [0|0] "" Vector__XXX
 SG_ VCLEFT_infoSubcomponent3 m24 : 32|32@1+ (1,0) [0|0] "" Vector__XXX
 SG_ VCLEFT_infoCBCAppCRC m31 : 32|32@1+ (1,0) [0|0] "" Vector__XXX

BO_ 771 OCS1P_status: 8 VEH
 SG_ OCS1P_classificationExtHold : 32|1@1+ (1,0) [0|0] "" Vector__XXX
 SG_ OCS1P_classificationHeld : 15|1@1+ (1,0) [0|0] "" Vector__XXX
 SG_ OCS1P_classificationHoldState : 33|2@1+ (1,0) [0|0] "" Vector__XXX
 SG_ OCS1P_cushionStable : 13|1@1+ (1,0) [0|0] "" Vector__XXX
 SG_ OCS1P_occupantClassification : 0|8@1+ (1,0) [0|0] "" Vector__XXX
 SG_ OCS1P_occupantClassificationQF : 8|1@1+ (1,0) [0|0] "" Vector__XXX
 SG_ OCS1P_occupantClassificationRaw : 16|8@1+ (1,0) [0|0] "" Vector__XXX
 SG_ OCS1P_occupantClassificationSelf : 24|8@1+ (1,0) [0|0] "" Vector__XXX
 SG_ OCS1P_occupiedState : 9|2@1+ (1,0) [0|0] "" Vector__XXX
 SG_ OCS1P_sandwichStable : 12|1@1+ (1,0) [0|0] "" Vector__XXX
 SG_ OCS1P_seatbackStable : 14|1@1+ (1,0) [0|0] "" Vector__XXX
 SG_ OCS1P_statusChecksum : 56|8@1+ (1,0) [0|0] "" Vector__XXX
 SG_ OCS1P_statusCounter : 52|4@1+ (1,0) [0|0] "" Vector__XXX

BO_ 772 PM_alertMatrix1: 8 VEH
 SG_ PM_a001_absoluteTorque : 0|1@1+ (1,0) [0|0] "" Vector__XXX
 SG_ PM_a002_accumulatedTorque : 1|1@1+ (1,0) [0|0] "" Vector__XXX
 SG_ PM_a003_torqueReversal : 2|1@1+ (1,0) [0|0] "" Vector__XXX
 SG_ PM_a004_regenTorque : 3|1@1+ (1,0) [0|0] "" Vector__XXX
 SG_ PM_a005_torqueInNeutral : 4|1@1+ (1,0) [0|0] "" Vector__XXX
 SG_ PM_a006_inconsistentDIGear : 5|1@1+ (1,0) [0|0] "" Vector__XXX
 SG_ PM_a007_watchdogReset : 6|1@1+ (1,0) [0|0] "" Vector__XXX
 SG_ PM_a008_memoryError : 7|1@1+ (1,0) [0|0] "" Vector__XXX
 SG_ PM_a009_espMIA : 8|1@1+ (1,0) [0|0] "" Vector__XXX
 SG_ PM_a010_diMIA : 9|1@1+ (1,0) [0|0] "" Vector__XXX
 SG_ PM_a011_phaseCurrentIrrational : 10|1@1+ (1,0) [0|0] "" Vector__XXX
 SG_ PM_a012_canDataBusA : 11|1@1+ (1,0) [0|0] "" Vector__XXX
 SG_ PM_a013_canHardwareBusA : 12|1@1+ (1,0) [0|0] "" Vector__XXX
 SG_ PM_a014_accelPedalError : 13|1@1+ (1,0) [0|0] "" Vector__XXX
 SG_ PM_a015_shifterMIA : 14|1@1+ (1,0) [0|0] "" Vector__XXX
 SG_ PM_a016_cruiseMIA : 15|1@1+ (1,0) [0|0] "" Vector__XXX
 SG_ PM_a017_brakeMIA : 16|1@1+ (1,0) [0|0] "" Vector__XXX
 SG_ PM_a018_encoderIrrational : 17|1@1+ (1,0) [0|0] "" Vector__XXX
 SG_ PM_a019_statorTempIrrational : 18|1@1+ (1,0) [0|0] "" Vector__XXX
 SG_ PM_a023_crsCmdOffStateOn : 22|1@1+ (1,0) [0|0] "" Vector__XXX
 SG_ PM_a024_brakeIrrational : 23|1@1+ (1,0) [0|0] "" Vector__XXX
 SG_ PM_a026_diHeartBeatMIA : 25|1@1+ (1,0) [0|0] "" Vector__XXX
 SG_ PM_a027_torqueOutOfMap : 26|1@1+ (1,0) [0|0] "" Vector__XXX
 SG_ PM_a028_torqueCmdError : 27|1@1+ (1,0) [0|0] "" Vector__XXX
 SG_ PM_a030_inconsistentAebState : 29|1@1+ (1,0) [0|0] "" Vector__XXX
 SG_ PM_a031_highStackUsage : 30|1@1+ (1,0) [0|0] "" Vector__XXX
 SG_ PM_a032_registerConfigError : 31|1@1+ (1,0) [0|0] "" Vector__XXX
 SG_ PM_a033_selfTest : 32|1@1+ (1,0) [0|0] "" Vector__XXX
 SG_ PM_a034_trqCrossCheck : 33|1@1+ (1,0) [0|0] "" Vector__XXX
 SG_ PM_a038_inconsistentTorqueSign : 37|1@1+ (1,0) [0|0] "" Vector__XXX
 SG_ PM_a039_disMIA : 38|1@1+ (1,0) [0|0] "" Vector__XXX
 SG_ PM_a040_pmMIA : 39|1@1+ (1,0) [0|0] "" Vector__XXX
 SG_ PM_a041_dasMIA : 40|1@1+ (1,0) [0|0] "" Vector__XXX
 SG_ PM_a042_gtwMIA : 41|1@1+ (1,0) [0|0] "" Vector__XXX
 SG_ PM_a043_inconsistentConfig : 42|1@1+ (1,0) [0|0] "" Vector__XXX
 SG_ PM_a044_ebrIntervention : 43|1@1+ (1,0) [0|0] "" Vector__XXX
 SG_ PM_a045_motorMovementDetected : 44|1@1+ (1,0) [0|0] "" Vector__XXX
 SG_ PM_a046_inconsVehicleHoldState : 45|1@1+ (1,0) [0|0] "" Vector__XXX
 SG_ PM_a047_inconsAutoparkState : 46|1@1+ (1,0) [0|0] "" Vector__XXX
 SG_ PM_a048_stabilityControlInhibit : 47|1@1+ (1,0) [0|0] "" Vector__XXX
 SG_ PM_a049_stbCtrlInWrongDir : 48|1@1+ (1,0) [0|0] "" Vector__XXX
 SG_ PM_a050_excessiveStbCtrlTrq : 49|1@1+ (1,0) [0|0] "" Vector__XXX
 SG_ PM_a051_unintDecelStbCtrl : 50|1@1+ (1,0) [0|0] "" Vector__XXX
 SG_ PM_a052_stbCtrlDrvrDecelCflct : 51|1@1+ (1,0) [0|0] "" Vector__XXX
 SG_ PM_a053_vcfrontMIA : 52|1@1+ (1,0) [0|0] "" Vector__XXX
 SG_ PM_a054_uiMIA : 53|1@1+ (1,0) [0|0] "" Vector__XXX
 SG_ PM_a055_resolver : 54|1@1+ (1,0) [0|0] "" Vector__XXX
 SG_ PM_a056_canHardwareBusB : 55|1@1+ (1,0) [0|0] "" Vector__XXX
 SG_ PM_a057_canDataBusB : 56|1@1+ (1,0) [0|0] "" Vector__XXX
 SG_ PM_a058_cmpMIA : 57|1@1+ (1,0) [0|0] "" Vector__XXX
 SG_ PM_a059_ptcMIA : 58|1@1+ (1,0) [0|0] "" Vector__XXX
 SG_ PM_a061_DIPMVersionMismatch : 60|1@1+ (1,0) [0|0] "" Vector__XXX
 SG_ PM_a063_debugAlert : 62|1@1+ (1,0) [0|0] "" Vector__XXX
 SG_ PM_a064_torqueIntervention : 63|1@1+ (1,0) [0|0] "" Vector__XXX

BO_ 774 VCRIGHT_info: 8 VEH
 SG_ VCRIGHT_infoIndex M : 0|8@1+ (1,0) [0|0] "" Vector__XXX
 SG_ VCRIGHT_infoBuildType m10 : 8|3@1+ (1,0) [0|0] "" Vector__XXX
 SG_ VCRIGHT_infoBuildConfigId m10 : 16|16@1+ (1,0) [0|0] "" Vector__XXX
 SG_ VCRIGHT_infoHardwareId m10 : 32|16@1+ (1,0) [0|0] "" Vector__XXX
 SG_ VCRIGHT_infoComponentId m10 : 48|16@1+ (1,0) [0|0] "" Vector__XXX
 SG_ VCRIGHT_infoPcbaId m11 : 8|8@1+ (1,0) [0|0] "" Vector__XXX
 SG_ VCRIGHT_infoAssemblyId m11 : 16|8@1+ (1,0) [0|0] "" Vector__XXX
 SG_ VCRIGHT_infoUsageId m11 : 24|16@1+ (1,0) [0|0] "" Vector__XXX
 SG_ VCRIGHT_infoSubUsageId m11 : 40|16@1+ (1,0) [0|0] "" Vector__XXX
 SG_ VCRIGHT_infoAppCrc m13 : 8|32@1+ (1,0) [0|0] "" Vector__XXX
 SG_ VCRIGHT_infoAppGitHash m17 : 10|54@1+ (4,0) [0|0] "" Vector__XXX
 SG_ VCRIGHT_infoBootGitHash m18 : 10|54@1+ (4,0) [0|0] "" Vector__XXX
 SG_ VCRIGHT_infoPlatformType m19 : 8|8@1+ (1,0) [0|0] "" Vector__XXX
 SG_ VCRIGHT_infoBootUdsProtoVersion m20 : 8|16@1+ (1,0) [0|0] "" Vector__XXX
 SG_ VCRIGHT_infoBootCrc m20 : 24|32@1+ (1,0) [0|0] "" Vector__XXX

BO_ 777 DAS_object: 8 CH
 SG_ DAS_objectId M : 0|3@1+ (1,0) [0|0] "" Vector__XXX
 SG_ DAS_leadVehType m0 : 3|3@1+ (1,0) [0|0] "" Vector__XXX
 SG_ DAS_leadVehRelevantForControl m0 : 7|1@1+ (1,0) [0|0] "" Vector__XXX
 SG_ DAS_leadVehDx m0 : 8|8@1+ (0.5,0) [0|0] "m" Vector__XXX
 SG_ DAS_leadVehVxRel m0 : 16|4@1+ (4,-30) [0|0] "m/s" Vector__XXX
 SG_ DAS_leadVehDy m0 : 20|7@1+ (0.35,-22.05) [0|0] "m" Vector__XXX
 SG_ DAS_leadVehId m0 : 27|7@1+ (1,0) [0|0] "" Vector__XXX
 SG_ DAS_leadVeh2Type m0 : 34|3@1+ (1,0) [0|0] "" Vector__XXX
 SG_ DAS_leadVeh2RelevantForControl m0 : 38|1@1+ (1,0) [0|0] "" Vector__XXX
 SG_ DAS_leadVeh2Dx m0 : 39|8@1+ (0.5,0) [0|0] "m" Vector__XXX
 SG_ DAS_leadVeh2VxRel m0 : 47|4@1+ (4,-30) [0|0] "m/s" Vector__XXX
 SG_ DAS_leadVeh2Dy m0 : 51|7@1+ (0.35,-22.05) [0|0] "m" Vector__XXX
 SG_ DAS_leadVeh2Id m0 : 58|6@1+ (1,0) [0|0] "" Vector__XXX
 SG_ DAS_leftVehType m1 : 3|3@1+ (1,0) [0|0] "" Vector__XXX
 SG_ DAS_leftVehRelevantForControl m1 : 7|1@1+ (1,0) [0|0] "" Vector__XXX
 SG_ DAS_leftVehDx m1 : 8|8@1+ (0.5,0) [0|0] "m" Vector__XXX
 SG_ DAS_leftVehVxRel m1 : 16|4@1+ (4,-30) [0|0] "m/s" Vector__XXX
 SG_ DAS_leftVehDy m1 : 20|7@1+ (0.35,-22.05) [0|0] "m" Vector__XXX
 SG_ DAS_leftVehId m1 : 27|7@1+ (1,0) [0|0] "" Vector__XXX
 SG_ DAS_leftVeh2Type m1 : 34|3@1+ (1,0) [0|0] "" Vector__XXX
 SG_ DAS_leftVeh2RelevantForControl m1 : 38|1@1+ (1,0) [0|0] "" Vector__XXX
 SG_ DAS_leftVeh2Dx m1 : 39|8@1+ (0.5,0) [0|0] "m" Vector__XXX
 SG_ DAS_leftVeh2VxRel m1 : 47|4@1+ (4,-30) [0|0] "m/s" Vector__XXX
 SG_ DAS_leftVeh2Dy m1 : 51|7@1+ (0.35,-22.05) [0|0] "m" Vector__XXX
 SG_ DAS_leftVeh2Id m1 : 58|6@1+ (1,0) [0|0] "" Vector__XXX
 SG_ DAS_rightVehType m2 : 3|3@1+ (1,0) [0|0] "" Vector__XXX
 SG_ DAS_rightVehRelevantForControl m2 : 7|1@1+ (1,0) [0|0] "" Vector__XXX
 SG_ DAS_rightVehDx m2 : 8|8@1+ (0.5,0) [0|0] "m" Vector__XXX
 SG_ DAS_rightVehVxRel m2 : 16|4@1+ (4,-30) [0|0] "m/s" Vector__XXX
 SG_ DAS_rightVehDy m2 : 20|7@1+ (0.35,-22.05) [0|0] "m" Vector__XXX
 SG_ DAS_rightVehId m2 : 27|7@1+ (1,0) [0|0] "" Vector__XXX
 SG_ DAS_rightVeh2Type m2 : 34|3@1+ (1,0) [0|0] "" Vector__XXX
 SG_ DAS_rightVeh2RelevantForControl m2 : 38|1@1+ (1,0) [0|0] "" Vector__XXX
 SG_ DAS_rightVeh2Dx m2 : 39|8@1+ (0.5,0) [0|0] "m" Vector__XXX
 SG_ DAS_rightVeh2VxRel m2 : 47|4@1+ (4,-30) [0|0] "m/s" Vector__XXX
 SG_ DAS_rightVeh2Dy m2 : 51|7@1+ (0.35,-22.05) [0|0] "m" Vector__XXX
 SG_ DAS_rightVeh2Id m2 : 58|6@1+ (1,0) [0|0] "" Vector__XXX
 SG_ DAS_cutinVehType m3 : 3|3@1+ (1,0) [0|0] "" Vector__XXX
 SG_ DAS_cutinVehRelevantForControl m3 : 7|1@1+ (1,0) [0|0] "" Vector__XXX
 SG_ DAS_cutinVehDx m3 : 8|8@1+ (0.5,0) [0|0] "m" Vector__XXX
 SG_ DAS_cutinVehVxRel m3 : 16|4@1+ (4,-30) [0|0] "m/s" Vector__XXX
 SG_ DAS_cutinVehDy m3 : 20|7@1+ (0.35,-22.05) [0|0] "m" Vector__XXX
 SG_ DAS_cutinVehId m3 : 27|7@1+ (1,0) [0|0] "" Vector__XXX
 SG_ DAS_roadSignColor m4 : 3|3@1+ (1,0) [0|0] "" Vector__XXX
 SG_ DAS_roadSignId m4 : 6|8@1+ (1,0) [0|0] "" Vector__XXX
 SG_ DAS_roadSignStopLineDist m4 : 14|10@1+ (0.2,-20) [0|0] "m" Vector__XXX
 SG_ DAS_roadSignControlActive m4 : 24|1@1+ (1,0) [0|0] "" Vector__XXX
 SG_ DAS_roadSignSource m4 : 25|2@1+ (1,0) [0|0] "" Vector__XXX
 SG_ DAS_roadSignArrow m4 : 27|3@1+ (1,0) [0|0] "" Vector__XXX
 SG_ DAS_roadSignOrientation m4 : 30|2@1+ (1,0) [0|0] "" Vector__XXX
 SG_ DAS_leadVehHeading m5 : 8|8@1+ (0.0245437,-3.14159) [0|0] "rad" Vector__XXX
 SG_ DAS_leadVeh2Heading m5 : 16|8@1+ (0.0245437,-3.14159) [0|0] "rad" Vector__XXX
 SG_ DAS_leftVehHeading m5 : 24|8@1+ (0.0245437,-3.14159) [0|0] "rad" Vector__XXX
 SG_ DAS_leftVeh2Heading m5 : 32|8@1+ (0.0245437,-3.14159) [0|0] "rad" Vector__XXX
 SG_ DAS_rightVehHeading m5 : 40|8@1+ (0.0245437,-3.14159) [0|0] "rad" Vector__XXX
 SG_ DAS_rightVeh2Heading m5 : 48|8@1+ (0.0245437,-3.14159) [0|0] "rad" Vector__XXX
 SG_ DAS_cutinVehHeading m5 : 56|8@1+ (0.0245437,-3.14159) [0|0] "rad" Vector__XXX

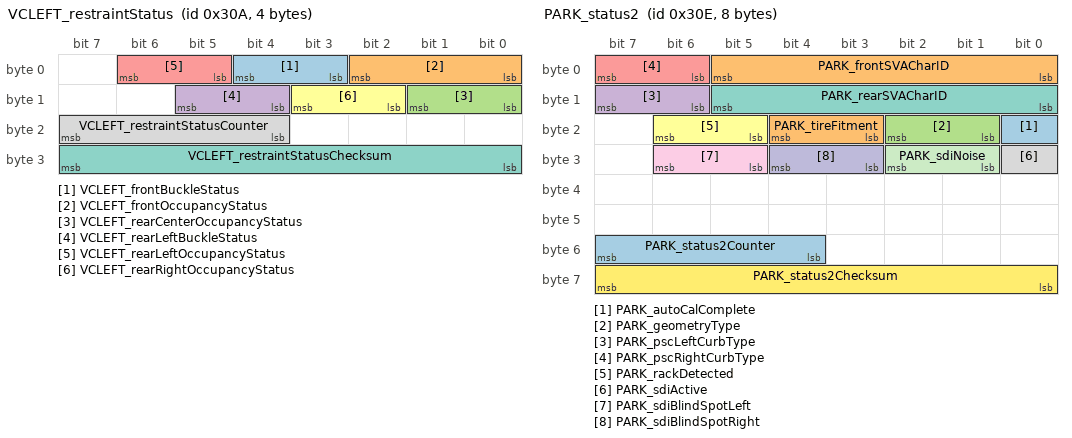
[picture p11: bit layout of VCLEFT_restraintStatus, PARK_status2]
BO_ 778 VCLEFT_restraintStatus: 4 VEH
 SG_ VCLEFT_frontBuckleStatus : 3|2@1+ (1,0) [0|0] "" Vector__XXX
 SG_ VCLEFT_frontOccupancyStatus : 0|3@1+ (1,0) [0|0] "" Vector__XXX
 SG_ VCLEFT_rearCenterOccupancyStatus : 8|2@1+ (1,0) [0|0] "" Vector__XXX
 SG_ VCLEFT_rearLeftBuckleStatus : 12|2@1+ (1,0) [0|0] "" Vector__XXX
 SG_ VCLEFT_rearLeftOccupancyStatus : 5|2@1+ (1,0) [0|0] "" Vector__XXX
 SG_ VCLEFT_rearRightOccupancyStatus : 10|2@1+ (1,0) [0|0] "" Vector__XXX
 SG_ VCLEFT_restraintStatusChecksum : 24|8@1+ (1,0) [0|0] "" Vector__XXX
 SG_ VCLEFT_restraintStatusCounter : 20|4@1+ (1,0) [0|0] "" Vector__XXX

BO_ 782 PARK_status2: 8 CH
 SG_ PARK_autoCalComplete : 16|1@1+ (1,0) [0|0] "" Vector__XXX
 SG_ PARK_frontSVACharID : 0|6@1+ (1,0) [0|0] "" Vector__XXX
 SG_ PARK_geometryType : 17|2@1+ (1,0) [0|0] "" Vector__XXX
 SG_ PARK_pscLeftCurbType : 14|2@1+ (1,0) [0|0] "" Vector__XXX
 SG_ PARK_pscRightCurbType : 6|2@1+ (1,0) [0|0] "" Vector__XXX
 SG_ PARK_rackDetected : 21|2@1+ (1,0) [0|0] "" Vector__XXX
 SG_ PARK_rearSVACharID : 8|6@1+ (1,0) [0|0] "" Vector__XXX
 SG_ PARK_sdiActive : 24|1@1+ (1,0) [0|0] "" Vector__XXX
 SG_ PARK_sdiBlindSpotLeft : 29|2@1+ (1,0) [0|0] "" Vector__XXX
 SG_ PARK_sdiBlindSpotRight : 27|2@1+ (1,0) [0|0] "" Vector__XXX
 SG_ PARK_sdiNoise : 25|2@1+ (1,0) [0|0] "" Vector__XXX
 SG_ PARK_status2Checksum : 56|8@1+ (1,0) [0|0] "" Vector__XXX
 SG_ PARK_status2Counter : 52|4@1+ (1,0) [0|0] "" Vector__XXX
 SG_ PARK_tireFitment : 19|2@1+ (1,0) [0|0] "" Vector__XXX

BO_ 784 HVP_info: 8 VEH
 SG_ HVP_infoIndex M : 0|8@1+ (1,0) [0|0] "" Vector__XXX
 SG_ HVP_buildType m10 : 8|3@1+ (1,0) [0|0] "" Vector__XXX
 SG_ HVP_buildConfigId m10 : 16|16@1+ (1,0) [0|0] "" Vector__XXX
 SG_ HVP_hardwareId m10 : 32|16@1+ (1,0) [0|0] "" Vector__XXX
 SG_ HVP_componentId m10 : 48|16@1+ (1,0) [0|0] "" Vector__XXX
 SG_ HVP_pcbaId m11 : 16|8@1+ (1,0) [0|0] "" Vector__XXX
 SG_ HVP_assemblyId m11 : 24|8@1+ (1,0) [0|0] "" Vector__XXX
 SG_ HVP_usageId m11 : 32|16@1+ (1,0) [0|0] "" Vector__XXX
 SG_ HVP_subUsageId m11 : 48|16@1+ (1,0) [0|0] "" Vector__XXX
 SG_ HVP_platformType m13 : 8|8@1+ (1,0) [0|0] "" Vector__XXX
 SG_ HVP_appCrc m13 : 32|32@1+ (1,0) [0|0] "" Vector__XXX
 SG_ HVP_appGitHash m17 : 10|54@1+ (4,0) [0|0] "" Vector__XXX
 SG_ HVP_bootGitHash m18 : 10|54@1+ (4,0) [0|0] "" Vector__XXX
 SG_ HVP_bootUdsProtoVersion m20 : 8|8@1+ (1,0) [0|0] "" Vector__XXX
 SG_ HVP_bootCrc m20 : 32|32@1+ (1,0) [0|0] "" Vector__XXX

BO_ 785 EPAS3S_info: 8 CH
 SG_ EPAS3S_infoIndex M : 0|8@1+ (1,0) [0|0] "" Vector__XXX
 SG_ EPAS3S_infoBuildType m10 : 8|8@1+ (1,0) [0|0] "" Vector__XXX
 SG_ EPAS3S_infoComponentID m10 : 48|16@1+ (1,0) [0|0] "" Vector__XXX
 SG_ EPAS3S_infoPcbaID m11 : 16|8@1+ (1,0) [0|0] "" Vector__XXX
 SG_ EPAS3S_infoAssemblyID m11 : 24|8@1+ (1,0) [0|0] "" Vector__XXX
 SG_ EPAS3S_infoUsageID m11 : 32|16@1+ (1,0) [0|0] "" Vector__XXX
 SG_ EPAS3S_infoBootUdsProtoVersion m20 : 8|8@1+ (1,0) [0|0] "" Vector__XXX
 SG_ EPAS3S_infoBootloaderCRC m20 : 32|32@1+ (1,0) [0|0] "" Vector__XXX
 SG_ EPAS3S_infoApplicationCRC m13 : 32|32@1+ (1,0) [0|0] "" Vector__XXX

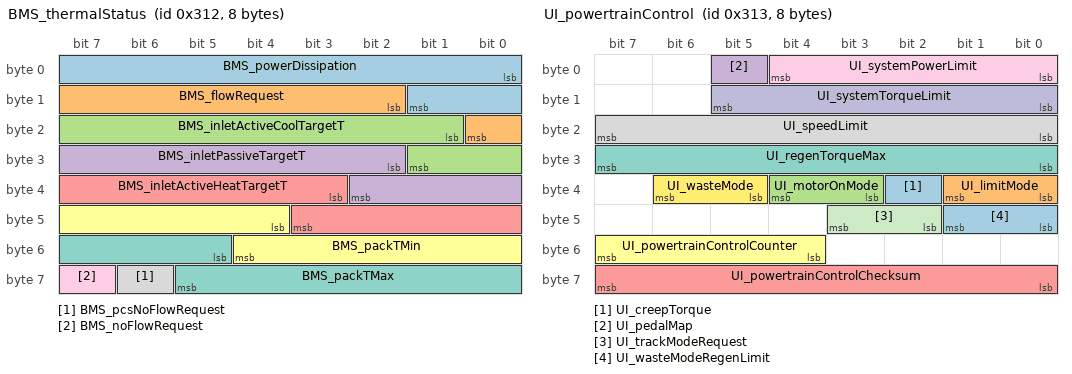
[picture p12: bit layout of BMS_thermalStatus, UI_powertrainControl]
BO_ 786 BMS_thermalStatus: 8 VEH
 SG_ BMS_powerDissipation : 0|10@1+ (0.02,0) [0|0] "kW" Vector__XXX
 SG_ BMS_flowRequest : 10|7@1+ (0.3,0) [0|0] "LPM" Vector__XXX
 SG_ BMS_inletActiveCoolTargetT : 17|9@1+ (0.25,-25) [0|0] "DegC" Vector__XXX
 SG_ BMS_inletPassiveTargetT : 26|9@1+ (0.25,-25) [0|0] "DegC" Vector__XXX
 SG_ BMS_inletActiveHeatTargetT : 35|9@1+ (0.25,-25) [0|0] "DegC" Vector__XXX
 SG_ BMS_packTMin : 44|9@1+ (0.25,-25) [-25|100] "DegC" Vector__XXX
 SG_ BMS_packTMax : 53|9@1+ (0.25,-25) [-25|100] "DegC" Vector__XXX
 SG_ BMS_pcsNoFlowRequest : 62|1@1+ (1,0) [0|0] "" Vector__XXX
 SG_ BMS_noFlowRequest : 63|1@1+ (1,0) [0|0] "" Vector__XXX

BO_ 787 UI_powertrainControl: 8 VEH
 SG_ UI_creepTorque : 34|1@1+ (1,0) [0|0] "" Vector__XXX
 SG_ UI_limitMode : 32|2@1+ (1,0) [0|0] "" Vector__XXX
 SG_ UI_motorOnMode : 35|2@1+ (1,0) [0|0] "" Vector__XXX
 SG_ UI_pedalMap : 5|1@1+ (1,0) [0|0] "" Vector__XXX
 SG_ UI_powertrainControlChecksum : 56|8@1+ (1,0) [0|0] "" Vector__XXX
 SG_ UI_powertrainControlCounter : 52|4@1+ (1,0) [0|0] "" Vector__XXX
 SG_ UI_regenTorqueMax : 24|8@1+ (0.5,0) [0|0] "%" Vector__XXX
 SG_ UI_speedLimit : 16|8@1+ (1,50) [0|0] "kph" Vector__XXX
 SG_ UI_systemPowerLimit : 0|5@1+ (20,20) [0|0] "kW" Vector__XXX
 SG_ UI_systemTorqueLimit : 8|6@1+ (100,4000) [0|0] "Nm" Vector__XXX
 SG_ UI_trackModeRequest : 42|2@1+ (1,0) [0|0] "" Vector__XXX
 SG_ UI_wasteMode : 37|2@1+ (1,0) [0|0] "" Vector__XXX
 SG_ UI_wasteModeRegenLimit : 40|2@1+ (1,0) [0|0] "" Vector__XXX

BO_ 789 DI_temperature: 8 VEH
 SG_ DI_temperatureIndex M : 0|1@1+ (1,0) [0|1] "" Vector__XXX
 SG_ DI_inverterT m0 : 8|8@1+ (1,-40) [0|0] "DegC" Vector__XXX
 SG_ DI_statorT m0 : 16|8@1+ (1,-40) [0|0] "DegC" Vector__XXX
 SG_ DI_dcCapT m0 : 24|8@1+ (1,-40) [0|0] "DegC" Vector__XXX
 SG_ DI_heatsinkT m0 : 32|8@1+ (1,-40) [0|0] "DegC" Vector__XXX
 SG_ DI_inverterTpct m0 : 40|8@1+ (0.4,0) [0|0] "%" Vector__XXX
 SG_ DI_statorTpct m0 : 48|8@1+ (0.4,0) [0|0] "%" Vector__XXX
 SG_ DI_inverterTQF m0 : 56|2@1+ (1,0) [0|3] "" Vector__XXX

BO_ 790 PM_info: 8 VEH
 SG_ PM_infoIndex M : 0|8@1+ (1,0) [0|0] "" Vector__XXX
 SG_ PM_buildType m10 : 8|8@1+ (1,0) [0|0] "" Vector__XXX
 SG_ PM_buildConfigurationId m10 : 16|16@1+ (1,0) [0|0] "" Vector__XXX
 SG_ PM_hardwareId m10 : 32|8@1+ (1,0) [0|0] "" Vector__XXX
 SG_ PM_componentId m10 : 48|16@1+ (1,0) [0|0] "" Vector__XXX
 SG_ PM_pcbaId m11 : 16|8@1+ (1,0) [0|0] "" Vector__XXX
 SG_ PM_assemblyId m11 : 24|8@1+ (1,0) [0|0] "" Vector__XXX
 SG_ PM_usageId m11 : 32|16@1+ (1,0) [0|0] "" Vector__XXX
 SG_ PM_subUsageId m11 : 48|16@1+ (1,0) [0|0] "" Vector__XXX
 SG_ PM_applicationCrc m13 : 32|32@1+ (1,0) [0|0] "" Vector__XXX
 SG_ PM_bootloaderSvnRevision m14 : 8|24@1+ (1,0) [0|0] "" Vector__XXX
 SG_ PM_bootloaderSvnUrlHash m14 : 32|32@1+ (1,0) [0|0] "" Vector__XXX
 SG_ PM_appGitHash m17 : 10|54@1+ (4,0) [0|0] "" Vector__XXX
 SG_ PM_bootGitHash m18 : 10|54@1+ (4,0) [0|0] "" Vector__XXX
 SG_ PM_platformTyp m19 : 8|8@1+ (1,0) [0|0] "" Vector__XXX
 SG_ PM_udsProtocolVersion m20 : 8|8@1+ (1,0) [0|0] "" Vector__XXX
 SG_ PM_bootloaderCrc m20 : 32|32@1+ (1,0) [0|0] "" Vector__XXX

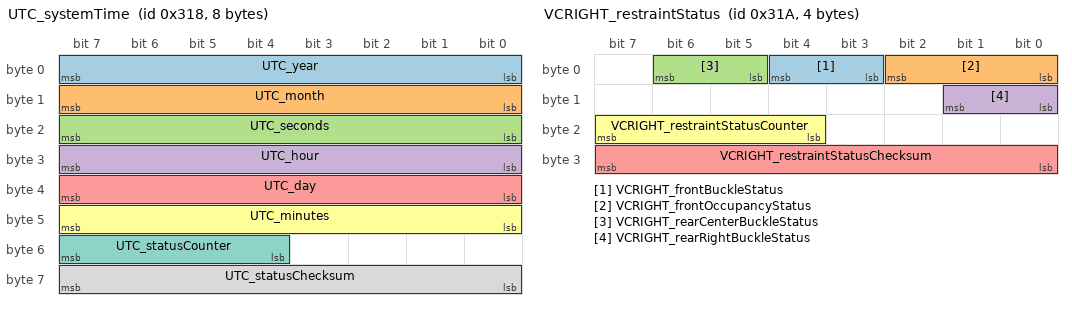
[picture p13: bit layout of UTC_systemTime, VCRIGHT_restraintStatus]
BO_ 792 UTC_systemTime: 8 VEH
 SG_ UTC_year : 0|8@1+ (1,0) [0|0] "" Vector__XXX
 SG_ UTC_month : 8|8@1+ (1,0) [0|0] "" Vector__XXX
 SG_ UTC_seconds : 16|8@1+ (1,0) [0|0] "" Vector__XXX
 SG_ UTC_hour : 24|8@1+ (1,0) [0|0] "" Vector__XXX
 SG_ UTC_day : 32|8@1+ (1,0) [0|0] "" Vector__XXX
 SG_ UTC_minutes : 40|8@1+ (1,0) [0|0] "" Vector__XXX
 SG_ UTC_statusCounter : 52|4@1+ (1,0) [0|0] "" Vector__XXX
 SG_ UTC_statusChecksum : 56|8@1+ (1,0) [0|0] "" Vector__XXX

BO_ 793 VCSEC_info: 8 VEH
 SG_ VCSEC_infoIndex M : 0|8@1+ (1,0) [0|0] "" Vector__XXX
 SG_ VCSEC_infoBuildType m10 : 8|3@1+ (1,0) [0|0] "" Vector__XXX
 SG_ VCSEC_infoBuildConfigId m10 : 16|16@1+ (1,0) [0|0] "" Vector__XXX
 SG_ VCSEC_infoHardwareId m10 : 32|16@1+ (1,0) [0|0] "" Vector__XXX
 SG_ VCSEC_infoComponentId m10 : 48|16@1+ (1,0) [0|0] "" Vector__XXX
 SG_ VCSEC_infoPcbaId m11 : 8|8@1+ (1,0) [0|0] "" Vector__XXX
 SG_ VCSEC_infoAssemblyId m11 : 16|8@1+ (1,0) [0|0] "" Vector__XXX
 SG_ VCSEC_infoUsageId m11 : 32|16@1+ (1,0) [0|0] "" Vector__XXX
 SG_ VCSEC_infoSubUsageId m11 : 48|16@1+ (1,0) [0|0] "" Vector__XXX
 SG_ VCSEC_infoAppCrc m13 : 32|32@1+ (1,0) [0|0] "" Vector__XXX
 SG_ VCSEC_infoSubcomponent1 m16 : 32|32@1+ (1,0) [0|0] "" Vector__XXX
 SG_ VCSEC_infoAppGitHash m17 : 10|54@1+ (4,0) [0|0] "" Vector__XXX
 SG_ VCSEC_infoBootGitHash m18 : 10|54@1+ (4,0) [0|0] "" Vector__XXX
 SG_ VCSEC_infoPlatformType m19 : 8|8@1+ (1,0) [0|0] "" Vector__XXX
 SG_ VCSEC_infoBootUdsProtoVersion m20 : 8|16@1+ (1,0) [0|0] "" Vector__XXX
 SG_ VCSEC_infoBootCrc m20 : 24|32@1+ (1,0) [0|0] "" Vector__XXX
 SG_ VCSEC_infoSubcomponent2 m23 : 32|32@1+ (1,0) [0|0] "" Vector__XXX
 SG_ VCSEC_infoSubcomponent3 m24 : 32|32@1+ (1,0) [0|0] "" Vector__XXX
 SG_ VCSEC_infoSubcomponent4 m31 : 32|32@1+ (1,0) [0|0] "" Vector__XXX

BO_ 794 VCRIGHT_restraintStatus: 4 VEH
 SG_ VCRIGHT_frontBuckleStatus : 3|2@1+ (1,0) [0|0] "" Vector__XXX
 SG_ VCRIGHT_frontOccupancyStatus : 0|3@1+ (1,0) [0|0] "" Vector__XXX
 SG_ VCRIGHT_rearCenterBuckleStatus : 5|2@1+ (1,0) [0|0] "" Vector__XXX
 SG_ VCRIGHT_rearRightBuckleStatus : 8|2@1+ (1,0) [0|0] "" Vector__XXX
 SG_ VCRIGHT_restraintStatusChecksum : 24|8@1+ (1,0) [0|0] "" Vector__XXX
 SG_ VCRIGHT_restraintStatusCounter : 20|4@1+ (1,0) [0|0] "" Vector__XXX

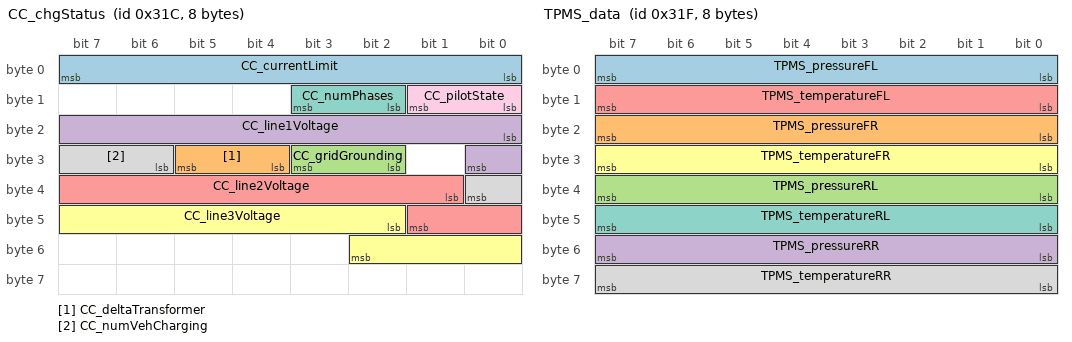
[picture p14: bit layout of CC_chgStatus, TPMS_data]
BO_ 796 CC_chgStatus: 8 VEH
 SG_ CC_currentLimit : 0|8@1+ (0.5,0) [0|0] "A" Vector__XXX
 SG_ CC_deltaTransformer : 28|2@1+ (1,0) [0|0] "" Vector__XXX
 SG_ CC_gridGrounding : 26|2@1+ (1,0) [0|0] "" Vector__XXX
 SG_ CC_line1Voltage : 16|9@1+ (1,0) [0|0] "V" Vector__XXX
 SG_ CC_line2Voltage : 33|9@1+ (1,0) [0|0] "V" Vector__XXX
 SG_ CC_line3Voltage : 42|9@1+ (1,0) [0|0] "V" Vector__XXX
 SG_ CC_numPhases : 10|2@1+ (1,0) [0|0] "" Vector__XXX
 SG_ CC_numVehCharging : 30|3@1+ (1,0) [0|0] "" Vector__XXX
 SG_ CC_pilotState : 8|2@1+ (1,0) [0|0] "" Vector__XXX

BO_ 797 CC_chgStatus2: 8 VEH
 SG_ CC_chgStatus2Index M : 0|8@1+ (1,0) [0|0] "" Vector__XXX
 SG_ CC_buttonState m0 : 8|1@1+ (1,0) [0|0] "" Vector__XXX

BO_ 798 CP_alertMatrix: 8 VEH
 SG_ CP_matrixIndex M : 0|4@1+ (1,0) [0|0] "" Vector__XXX
 SG_ CP_a001_canRx m0 : 4|1@1+ (1,0) [0|0] "" Vector__XXX
 SG_ CP_a002_canTx m0 : 5|1@1+ (1,0) [0|0] "" Vector__XXX
 SG_ CP_a003_canError m0 : 6|1@1+ (1,0) [0|0] "" Vector__XXX
 SG_ CP_a004_proximityRationality m0 : 7|1@1+ (1,0) [0|0] "" Vector__XXX
 SG_ CP_a005_gbdcLiveDisconnect m0 : 8|1@1+ (1,0) [0|0] "" Vector__XXX
 SG_ CP_a006_lostCommsBMS m0 : 9|1@1+ (1,0) [0|0] "" Vector__XXX
 SG_ CP_a007_watchdog m0 : 10|1@1+ (1,0) [0|0] "" Vector__XXX
 SG_ CP_a008_memoryError m0 : 11|1@1+ (1,0) [0|0] "" Vector__XXX
 SG_ CP_a009_coverOpen m0 : 12|1@1+ (1,0) [0|0] "" Vector__XXX
 SG_ CP_a010_pilotRationality m0 : 13|1@1+ (1,0) [0|0] "" Vector__XXX
 SG_ CP_a011_eeprom m0 : 14|1@1+ (1,0) [0|0] "" Vector__XXX
 SG_ CP_a012_ledDriver m0 : 15|1@1+ (1,0) [0|0] "" Vector__XXX
 SG_ CP_a013_lostCommsGTW m0 : 16|1@1+ (1,0) [0|0] "" Vector__XXX
 SG_ CP_a014_lostCommsCHG m0 : 17|1@1+ (1,0) [0|0] "" Vector__XXX
 SG_ CP_a015_apsVov m0 : 18|1@1+ (1,0) [0|0] "" Vector__XXX
 SG_ CP_a016_apsVuv m0 : 19|1@1+ (1,0) [0|0] "" Vector__XXX
 SG_ CP_a017_fiveVov m0 : 20|1@1+ (1,0) [0|0] "" Vector__XXX
 SG_ CP_a018_fiveVuv m0 : 21|1@1+ (1,0) [0|0] "" Vector__XXX
 SG_ CP_a019_threeVov m0 : 22|1@1+ (1,0) [0|0] "" Vector__XXX
 SG_ CP_a020_threeVuv m0 : 23|1@1+ (1,0) [0|0] "" Vector__XXX
 SG_ CP_a021_zeroVov m0 : 24|1@1+ (1,0) [0|0] "" Vector__XXX
 SG_ CP_a022_zeroVuv m0 : 25|1@1+ (1,0) [0|0] "" Vector__XXX
 SG_ CP_a023_gbdcSessionFailed m0 : 26|1@1+ (1,0) [0|0] "" Vector__XXX
 SG_ CP_a024_ledsUC m0 : 27|1@1+ (1,0) [0|0] "" Vector__XXX
 SG_ CP_a025_ledsOC m0 : 28|1@1+ (1,0) [0|0] "" Vector__XXX
 SG_ CP_a026_networkManagement m0 : 29|1@1+ (1,0) [0|0] "" Vector__XXX
 SG_ CP_a027_doorSensorOutOfSpec m0 : 30|1@1+ (1,0) [0|0] "" Vector__XXX
 SG_ CP_a028_insertEnableMismatch m0 : 31|1@1+ (1,0) [0|0] "" Vector__XXX
 SG_ CP_a029_doorClosedProxPilot m0 : 32|1@1+ (1,0) [0|0] "" Vector__XXX
 SG_ CP_a030_busOff m0 : 33|1@1+ (1,0) [0|0] "" Vector__XXX
 SG_ CP_a031_doorClosedCommandedOpen m0 : 34|1@1+ (1,0) [0|0] "" Vector__XXX
 SG_ CP_a032_doorOpenExpectedClosed m0 : 35|1@1+ (1,0) [0|0] "" Vector__XXX
 SG_ CP_a033_spiOpen m0 : 36|1@1+ (1,0) [0|0] "" Vector__XXX
 SG_ CP_a034_calibrationIncomplete m0 : 37|1@1+ (1,0) [0|0] "" Vector__XXX
 SG_ CP_a035_latchMovement_1 m0 : 38|1@1+ (1,0) [0|0] "" Vector__XXX
 SG_ CP_a036_latchNotDisengaged m0 : 39|1@1+ (1,0) [0|0] "" Vector__XXX
 SG_ CP_a037_latchNotEngaged m0 : 40|1@1+ (1,0) [0|0] "" Vector__XXX
 SG_ CP_a038_latchNotBlocking m0 : 41|1@1+ (1,0) [0|0] "" Vector__XXX
 SG_ CP_a039_latchMovement_2 m0 : 42|1@1+ (1,0) [0|0] "" Vector__XXX
 SG_ CP_a040_doNotUse m0 : 43|1@1+ (1,0) [0|0] "" Vector__XXX
 SG_ CP_a041_doorSensorUnplugged m0 : 44|1@1+ (1,0) [0|0] "" Vector__XXX
 SG_ CP_a042_doorAssemblyBroken m0 : 45|1@1+ (1,0) [0|0] "" Vector__XXX
 SG_ CP_a043_doorPotIrrational m0 : 46|1@1+ (1,0) [0|0] "" Vector__XXX
 SG_ CP_a044_lostCommsHVP m0 : 47|1@1+ (1,0) [0|0] "" Vector__XXX
 SG_ CP_a045_lostCommsVCSEC m0 : 48|1@1+ (1,0) [0|0] "" Vector__XXX
 SG_ CP_a046_lostCommsEVSE m0 : 49|1@1+ (1,0) [0|0] "" Vector__XXX
 SG_ CP_a047_lostCommsVCFRONT m0 : 50|1@1+ (1,0) [0|0] "" Vector__XXX
 SG_ CP_a048_lostCommsUI m0 : 51|1@1+ (1,0) [0|0] "" Vector__XXX
 SG_ CP_a049_multipleCablesDetected m0 : 52|1@1+ (1,0) [0|0] "" Vector__XXX
 SG_ CP_a050_latchNotConnected m0 : 53|1@1+ (1,0) [0|0] "" Vector__XXX
 SG_ CP_a051_doorInductiveSensorMIA m0 : 54|1@1+ (1,0) [0|0] "" Vector__XXX
 SG_ CP_a052_evseNotSupported m0 : 55|1@1+ (1,0) [0|0] "" Vector__XXX
 SG_ CP_a053_proxLatchedNoPilot m0 : 56|1@1+ (1,0) [0|0] "" Vector__XXX
 SG_ CP_a054_cableNotSecured m0 : 57|1@1+ (1,0) [0|0] "" Vector__XXX
 SG_ CP_a055_chargeStoppedNoPilot m0 : 58|1@1+ (1,0) [0|0] "" Vector__XXX
 SG_ CP_a056_proxDisconnected m0 : 59|1@1+ (1,0) [0|0] "" Vector__XXX
 SG_ CP_a057_evseFaulted m0 : 60|1@1+ (1,0) [0|0] "" Vector__XXX
 SG_ CP_a058_acChargingBlocked m0 : 61|1@1+ (1,0) [0|0] "" Vector__XXX
 SG_ CP_a059_swcanError m0 : 62|1@1+ (1,0) [0|0] "" Vector__XXX
 SG_ CP_a060_lostCommsPCS m0 : 63|1@1+ (1,0) [0|0] "" Vector__XXX
 SG_ CP_a061_uhfReceiverMIA m1 : 4|1@1+ (1,0) [0|0] "" Vector__XXX
 SG_ CP_a062_scOutOfService m1 : 5|1@1+ (1,0) [0|0] "" Vector__XXX
 SG_ CP_a063_scUpdateInProgress m1 : 6|1@1+ (1,0) [0|0] "" Vector__XXX
 SG_ CP_a064_superchargingBlocked m1 : 7|1@1+ (1,0) [0|0] "" Vector__XXX
 SG_ CP_a065_selfTestFailed m1 : 8|1@1+ (1,0) [0|0] "" Vector__XXX
 SG_ CP_a066_proxLatchedIdlePilot m1 : 9|1@1+ (1,0) [0|0] "" Vector__XXX
 SG_ CP_a067_gbdcConnFault m1 : 10|1@1+ (1,0) [0|0] "" Vector__XXX
 SG_ CP_a068_doorSensorMismatch m1 : 11|1@1+ (1,0) [0|0] "" Vector__XXX
 SG_ CP_a069_doorInductiveSensorError m1 : 12|1@1+ (1,0) [0|0] "" Vector__XXX
 SG_ CP_a256_unused m1 : 13|1@1+ (1,0) [0|0] "" Vector__XXX

BO_ 799 TPMS_data: 8 CH
 SG_ TPMS_pressureFL : 0|8@1+ (0.025,0) [0|0] "bar" Vector__XXX
 SG_ TPMS_pressureFR : 16|8@1+ (0.025,0) [0|0] "bar" Vector__XXX
 SG_ TPMS_pressureRL : 32|8@1+ (0.025,0) [0|0] "bar" Vector__XXX
 SG_ TPMS_pressureRR : 48|8@1+ (0.025,0) [0|0] "bar" Vector__XXX
 SG_ TPMS_temperatureFL : 8|8@1+ (1,-40) [0|0] "degC" Vector__XXX
 SG_ TPMS_temperatureFR : 24|8@1+ (1,-40) [0|0] "degC" Vector__XXX
 SG_ TPMS_temperatureRL : 40|8@1+ (1,-40) [0|0] "degC" Vector__XXX
 SG_ TPMS_temperatureRR : 56|8@1+ (1,-40) [0|0] "degC" Vector__XXX

BO_ 800 BMS_alertMatrix: 8 VEH
 SG_ BMS_matrixIndex M : 0|4@1+ (1,0) [0|0] "" Vector__XXX
 SG_ BMS_a017_SW_Brick_OV m0 : 20|1@1+ (1,0) [0|0] "" Vector__XXX
 SG_ BMS_a018_SW_Brick_UV m0 : 21|1@1+ (1,0) [0|0] "" Vector__XXX
 SG_ BMS_a019_SW_Module_OT m0 : 22|1@1+ (1,0) [0|0] "" Vector__XXX
 SG_ BMS_a021_SW_Dr_Limits_Regulation m0 : 24|1@1+ (1,0) [0|0] "" Vector__XXX
 SG_ BMS_a022_SW_Over_Current m0 : 25|1@1+ (1,0) [0|0] "" Vector__XXX
 SG_ BMS_a023_SW_Stack_OV m0 : 26|1@1+ (1,0) [0|0] "" Vector__XXX
 SG_ BMS_a024_SW_Islanded_Brick m0 : 27|1@1+ (1,0) [0|0] "" Vector__XXX
 SG_ BMS_a025_SW_PwrBalance_Anomaly m0 : 28|1@1+ (1,0) [0|0] "" Vector__XXX
 SG_ BMS_a026_SW_HFCurrent_Anomaly m0 : 29|1@1+ (1,0) [0|0] "" Vector__XXX
 SG_ BMS_a034_SW_Passive_Isolation m0 : 37|1@1+ (1,0) [0|0] "" Vector__XXX
 SG_ BMS_a035_SW_Isolation m0 : 38|1@1+ (1,0) [0|0] "" Vector__XXX
 SG_ BMS_a036_SW_HvpHvilFault m0 : 39|1@1+ (1,0) [0|0] "" Vector__XXX
 SG_ BMS_a037_SW_Flood_Port_Open m0 : 40|1@1+ (1,0) [0|0] "" Vector__XXX
 SG_ BMS_a039_SW_DC_Link_Over_Voltage m0 : 42|1@1+ (1,0) [0|0] "" Vector__XXX
 SG_ BMS_a041_SW_Power_On_Reset m0 : 44|1@1+ (1,0) [0|0] "" Vector__XXX
 SG_ BMS_a042_SW_MPU_Error m0 : 45|1@1+ (1,0) [0|0] "" Vector__XXX
 SG_ BMS_a043_SW_Watch_Dog_Reset m0 : 46|1@1+ (1,0) [0|0] "" Vector__XXX
 SG_ BMS_a044_SW_Assertion m0 : 47|1@1+ (1,0) [0|0] "" Vector__XXX
 SG_ BMS_a045_SW_Exception m0 : 48|1@1+ (1,0) [0|0] "" Vector__XXX
 SG_ BMS_a046_SW_Task_Stack_Usage m0 : 49|1@1+ (1,0) [0|0] "" Vector__XXX
 SG_ BMS_a047_SW_Task_Stack_Overflow m0 : 50|1@1+ (1,0) [0|0] "" Vector__XXX
 SG_ BMS_a048_SW_Log_Upload_Request m0 : 51|1@1+ (1,0) [0|0] "" Vector__XXX
 SG_ BMS_a050_SW_Brick_Voltage_MIA m0 : 53|1@1+ (1,0) [0|0] "" Vector__XXX
 SG_ BMS_a051_SW_HVC_Vref_Bad m0 : 54|1@1+ (1,0) [0|0] "" Vector__XXX
 SG_ BMS_a052_SW_PCS_MIA m0 : 55|1@1+ (1,0) [0|0] "" Vector__XXX
 SG_ BMS_a053_SW_ThermalModel_Sanity m0 : 56|1@1+ (1,0) [0|0] "" Vector__XXX
 SG_ BMS_a054_SW_Ver_Supply_Fault m0 : 57|1@1+ (1,0) [0|0] "" Vector__XXX
 SG_ BMS_a059_SW_Pack_Voltage_Sensing m0 : 62|1@1+ (1,0) [0|0] "" Vector__XXX
 SG_ BMS_a060_SW_Leakage_Test_Failure m0 : 63|1@1+ (1,0) [0|0] "" Vector__XXX
 SG_ BMS_a061_robinBrickOverVoltage m1 : 4|1@1+ (1,0) [0|0] "" Vector__XXX
 SG_ BMS_a062_SW_BrickV_Imbalance m1 : 5|1@1+ (1,0) [0|0] "" Vector__XXX
 SG_ BMS_a063_SW_ChargePort_Fault m1 : 6|1@1+ (1,0) [0|0] "" Vector__XXX
 SG_ BMS_a064_SW_SOC_Imbalance m1 : 7|1@1+ (1,0) [0|0] "" Vector__XXX
 SG_ BMS_a069_SW_Low_Power m1 : 12|1@1+ (1,0) [0|0] "" Vector__XXX
 SG_ BMS_a071_SW_SM_TransCon_Not_Met m1 : 14|1@1+ (1,0) [0|0] "" Vector__XXX
 SG_ BMS_a075_SW_Chg_Disable_Failure m1 : 18|1@1+ (1,0) [0|0] "" Vector__XXX
 SG_ BMS_a076_SW_Dch_While_Charging m1 : 19|1@1+ (1,0) [0|0] "" Vector__XXX
 SG_ BMS_a077_SW_Charger_Regulation m1 : 20|1@1+ (1,0) [0|0] "" Vector__XXX
 SG_ BMS_a081_SW_Ctr_Close_Blocked m1 : 24|1@1+ (1,0) [0|0] "" Vector__XXX
 SG_ BMS_a082_SW_Ctr_Force_Open m1 : 25|1@1+ (1,0) [0|0] "" Vector__XXX
 SG_ BMS_a083_SW_Ctr_Close_Failure m1 : 26|1@1+ (1,0) [0|0] "" Vector__XXX
 SG_ BMS_a084_SW_Sleep_Wake_Aborted m1 : 27|1@1+ (1,0) [0|0] "" Vector__XXX
 SG_ BMS_a087_SW_Feim_Test_Blocked m1 : 30|1@1+ (1,0) [0|0] "" Vector__XXX
 SG_ BMS_a088_SW_VcFront_MIA_InDrive m1 : 31|1@1+ (1,0) [0|0] "" Vector__XXX
 SG_ BMS_a089_SW_VcFront_MIA m1 : 32|1@1+ (1,0) [0|0] "" Vector__XXX
 SG_ BMS_a090_SW_Gateway_MIA m1 : 33|1@1+ (1,0) [0|0] "" Vector__XXX
 SG_ BMS_a091_SW_ChargePort_MIA m1 : 34|1@1+ (1,0) [0|0] "" Vector__XXX
 SG_ BMS_a092_SW_ChargePort_Mia_On_Hvs m1 : 35|1@1+ (1,0) [0|0] "" Vector__XXX
 SG_ BMS_a094_SW_Drive_Inverter_MIA m1 : 37|1@1+ (1,0) [0|0] "" Vector__XXX
 SG_ BMS_a099_SW_BMB_Communication m1 : 42|1@1+ (1,0) [0|0] "" Vector__XXX
 SG_ BMS_a105_SW_One_Module_Tsense m1 : 48|1@1+ (1,0) [0|0] "" Vector__XXX
 SG_ BMS_a106_SW_All_Module_Tsense m1 : 49|1@1+ (1,0) [0|0] "" Vector__XXX
 SG_ BMS_a107_SW_Stack_Voltage_MIA m1 : 50|1@1+ (1,0) [0|0] "" Vector__XXX
 SG_ BMS_a121_SW_NVRAM_Config_Error m2 : 4|1@1+ (1,0) [0|0] "" Vector__XXX
 SG_ BMS_a122_SW_BMS_Therm_Irrational m2 : 5|1@1+ (1,0) [0|0] "" Vector__XXX
 SG_ BMS_a123_SW_Internal_Isolation m2 : 6|1@1+ (1,0) [0|0] "" Vector__XXX
 SG_ BMS_a127_SW_shunt_SNA m2 : 10|1@1+ (1,0) [0|0] "" Vector__XXX
 SG_ BMS_a128_SW_shunt_MIA m2 : 11|1@1+ (1,0) [0|0] "" Vector__XXX
 SG_ BMS_a129_SW_VSH_Failure m2 : 12|1@1+ (1,0) [0|0] "" Vector__XXX
 SG_ BMS_a130_IO_CAN_Error m2 : 13|1@1+ (1,0) [0|0] "" Vector__XXX
 SG_ BMS_a131_Bleed_FET_Failure m2 : 14|1@1+ (1,0) [0|0] "" Vector__XXX
 SG_ BMS_a132_HW_BMB_OTP_Uncorrctbl m2 : 15|1@1+ (1,0) [0|0] "" Vector__XXX
 SG_ BMS_a134_SW_Delayed_Ctr_Off m2 : 17|1@1+ (1,0) [0|0] "" Vector__XXX
 SG_ BMS_a136_SW_Module_OT_Warning m2 : 19|1@1+ (1,0) [0|0] "" Vector__XXX
 SG_ BMS_a137_SW_Brick_UV_Warning m2 : 20|1@1+ (1,0) [0|0] "" Vector__XXX
 SG_ BMS_a138_SW_Brick_OV_Warning m2 : 21|1@1+ (1,0) [0|0] "" Vector__XXX
 SG_ BMS_a139_SW_DC_Link_V_Irrational m2 : 22|1@1+ (1,0) [0|0] "" Vector__XXX
 SG_ BMS_a141_SW_BMB_Status_Warning m2 : 24|1@1+ (1,0) [0|0] "" Vector__XXX
 SG_ BMS_a144_Hvp_Config_Mismatch m2 : 27|1@1+ (1,0) [0|0] "" Vector__XXX
 SG_ BMS_a145_SW_SOC_Change m2 : 28|1@1+ (1,0) [0|0] "" Vector__XXX
 SG_ BMS_a146_SW_Brick_Overdischarged m2 : 29|1@1+ (1,0) [0|0] "" Vector__XXX
 SG_ BMS_a149_SW_Missing_Config_Block m2 : 32|1@1+ (1,0) [0|0] "" Vector__XXX
 SG_ BMS_a151_SW_external_isolation m2 : 34|1@1+ (1,0) [0|0] "" Vector__XXX
 SG_ BMS_a156_SW_BMB_Vref_bad m2 : 39|1@1+ (1,0) [0|0] "" Vector__XXX
 SG_ BMS_a157_SW_HVP_HVS_Comms m2 : 40|1@1+ (1,0) [0|0] "" Vector__XXX
 SG_ BMS_a158_SW_HVP_HVI_Comms m2 : 41|1@1+ (1,0) [0|0] "" Vector__XXX
 SG_ BMS_a159_SW_HVP_ECU_Error m2 : 42|1@1+ (1,0) [0|0] "" Vector__XXX
 SG_ BMS_a161_SW_DI_Open_Request m2 : 44|1@1+ (1,0) [0|0] "" Vector__XXX
 SG_ BMS_a162_SW_No_Power_For_Support m2 : 45|1@1+ (1,0) [0|0] "" Vector__XXX
 SG_ BMS_a163_SW_Contactor_Mismatch m2 : 46|1@1+ (1,0) [0|0] "" Vector__XXX
 SG_ BMS_a164_SW_Uncontrolled_Regen m2 : 47|1@1+ (1,0) [0|0] "" Vector__XXX
 SG_ BMS_a165_SW_Pack_Partial_Weld m2 : 48|1@1+ (1,0) [0|0] "" Vector__XXX
 SG_ BMS_a166_SW_Pack_Full_Weld m2 : 49|1@1+ (1,0) [0|0] "" Vector__XXX
 SG_ BMS_a167_SW_FC_Partial_Weld m2 : 50|1@1+ (1,0) [0|0] "" Vector__XXX
 SG_ BMS_a168_SW_FC_Full_Weld m2 : 51|1@1+ (1,0) [0|0] "" Vector__XXX
 SG_ BMS_a169_SW_FC_Pack_Weld m2 : 52|1@1+ (1,0) [0|0] "" Vector__XXX
 SG_ BMS_a170_SW_Limp_Mode m2 : 53|1@1+ (1,0) [0|0] "" Vector__XXX
 SG_ BMS_a171_SW_Stack_Voltage_Sense m2 : 54|1@1+ (1,0) [0|0] "" Vector__XXX
 SG_ BMS_a174_SW_Charge_Failure m2 : 57|1@1+ (1,0) [0|0] "" Vector__XXX
 SG_ BMS_a176_SW_GracefulPowerOff m2 : 59|1@1+ (1,0) [0|0] "" Vector__XXX
 SG_ BMS_a179_SW_Hvp_12V_Fault m2 : 62|1@1+ (1,0) [0|0] "" Vector__XXX
 SG_ BMS_a180_SW_ECU_reset_blocked m2 : 63|1@1+ (1,0) [0|0] "" Vector__XXX

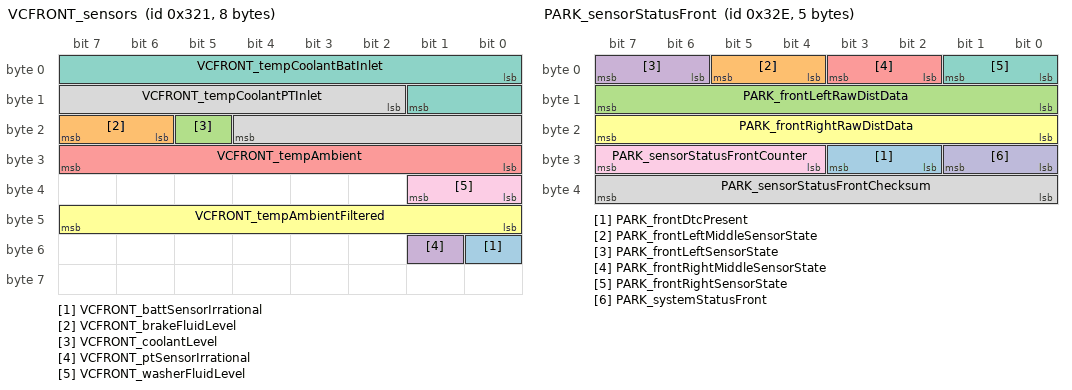
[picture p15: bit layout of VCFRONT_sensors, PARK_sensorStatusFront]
BO_ 801 VCFRONT_sensors: 8 VEH
 SG_ VCFRONT_battSensorIrrational : 48|1@1+ (1,0) [0|0] "" Vector__XXX
 SG_ VCFRONT_brakeFluidLevel : 22|2@1+ (1,0) [0|0] "" Vector__XXX
 SG_ VCFRONT_coolantLevel : 21|1@1+ (1,0) [0|0] "" Vector__XXX
 SG_ VCFRONT_ptSensorIrrational : 49|1@1+ (1,0) [0|0] "" Vector__XXX
 SG_ VCFRONT_tempAmbient : 24|8@1+ (0.5,-40) [0|0] "degC" Vector__XXX
 SG_ VCFRONT_tempAmbientFiltered : 40|8@1+ (0.5,-40) [0|0] "degC" Vector__XXX
 SG_ VCFRONT_tempCoolantBatInlet : 0|10@1+ (0.125,-40) [0|0] "degC" Vector__XXX
 SG_ VCFRONT_tempCoolantPTInlet : 10|11@1+ (0.125,-40) [0|0] "degC" Vector__XXX
 SG_ VCFRONT_washerFluidLevel : 32|2@1+ (1,0) [0|0] "" Vector__XXX

BO_ 805 FC_alertMatrix1: 8 VEH
 SG_ FC_a001_scPostOutOfService : 0|1@1+ (1,0) [0|0] "" Vector__XXX
 SG_ FC_a002_scPowerShared : 1|1@1+ (1,0) [0|0] "" Vector__XXX

BO_ 806 PARK_info: 8 CH
 SG_ PARK_infoIndex M : 0|8@1+ (1,0) [0|0] "" Vector__XXX
 SG_ PARK_infoBuildType m10 : 8|8@1+ (1,0) [0|0] "" Vector__XXX
 SG_ PARK_infoComponentID m10 : 48|16@1+ (1,0) [0|0] "" Vector__XXX
 SG_ PARK_infoPcbaID m11 : 16|8@1+ (1,0) [0|0] "" Vector__XXX
 SG_ PARK_infoAssemblyID m11 : 24|8@1+ (1,0) [0|0] "" Vector__XXX
 SG_ PARK_infoUsageID m11 : 32|16@1+ (1,0) [0|0] "" Vector__XXX
 SG_ PARK_infoBootUdsProtoVersion m20 : 8|8@1+ (1,0) [0|0] "" Vector__XXX
 SG_ PARK_infoBootloaderCRC m20 : 32|32@1+ (1,0) [0|0] "" Vector__XXX
 SG_ PARK_infoApplicationCRC m13 : 32|32@1+ (1,0) [0|0] "" Vector__XXX

BO_ 808 ESP_info: 8 VEH
 SG_ ESP_infoIndex M : 0|8@1+ (1,0) [0|0] "" Vector__XXX
 SG_ ESP_infoBuildType m10 : 8|8@1+ (1,0) [0|0] "" Vector__XXX
 SG_ ESP_infoComponentID m10 : 48|16@1+ (1,0) [0|0] "" Vector__XXX
 SG_ ESP_infoPcbaID m11 : 16|8@1+ (1,0) [0|0] "" Vector__XXX
 SG_ ESP_infoAssemblyID m11 : 24|8@1+ (1,0) [0|0] "" Vector__XXX
 SG_ ESP_infoUsageID m11 : 32|16@1+ (1,0) [0|0] "" Vector__XXX
 SG_ ESP_infoApplicationCRC m13 : 32|32@0+ (1,0) [0|0] "" Vector__XXX
 SG_ ESP_infoVehicleVariant m16 : 16|8@1+ (1,0) [0|0] "" Vector__XXX
 SG_ ESP_infoBootUdsProtoVersion m20 : 8|8@1+ (1,0) [0|0] "" Vector__XXX
 SG_ ESP_infoBootloaderCRC m20 : 32|32@1+ (1,0) [0|0] "" Vector__XXX
 SG_ ESP_infoVariantCRC m22 : 32|32@0+ (1,0) [0|0] "" Vector__XXX

BO_ 809 APP_warningMatrix0: 8 CH
 SG_ APP_w001_DEPRECATED : 0|1@1+ (1,0) [0|0] "" Vector__XXX
 SG_ APP_w002_ldwDisabled : 1|1@1+ (1,0) [0|0] "" Vector__XXX
 SG_ APP_w003_isaDisabled : 2|1@1+ (1,0) [0|0] "" Vector__XXX
 SG_ APP_w004_accDisabled : 3|1@1+ (1,0) [0|0] "" Vector__XXX
 SG_ APP_w005_fcwCancelled : 4|1@1+ (1,0) [0|0] "" Vector__XXX
 SG_ APP_w006_aebCancelled : 5|1@1+ (1,0) [0|0] "" Vector__XXX
 SG_ APP_w007_ahlbDisabled : 6|1@1+ (1,0) [0|0] "" Vector__XXX
 SG_ APP_w008_parkDisabled : 7|1@1+ (1,0) [0|0] "" Vector__XXX
 SG_ APP_w009_aebFault : 8|1@1+ (1,0) [0|0] "" Vector__XXX
 SG_ APP_w010_radcCalibIssue : 9|1@1+ (1,0) [0|0] "" Vector__XXX
 SG_ APP_w011_scaEvent : 10|1@1+ (1,0) [0|0] "" Vector__XXX
 SG_ APP_w012_Cam_BootFailure : 11|1@1+ (1,0) [0|0] "" Vector__XXX
 SG_ APP_w013_Cam_Watchdog : 12|1@1+ (1,0) [0|0] "" Vector__XXX
 SG_ APP_w014_swAssert : 13|1@1+ (1,0) [0|0] "" Vector__XXX
 SG_ APP_w015_Camera_Failsafes : 14|1@1+ (1,0) [0|0] "" Vector__XXX
 SG_ APP_w016_aeb_e_event : 15|1@1+ (1,0) [0|0] "" Vector__XXX
 SG_ APP_w017_Cam_Msg_MIA : 16|1@1+ (1,0) [0|0] "" Vector__XXX
 SG_ APP_w018_ECU_Power_Issue : 17|1@1+ (1,0) [0|0] "" Vector__XXX
 SG_ APP_w019_ECU_Stack_Overflow : 18|1@1+ (1,0) [0|0] "" Vector__XXX
 SG_ APP_w020_ECU_checkstopError : 19|1@1+ (1,0) [0|0] "" Vector__XXX
 SG_ APP_w021_ECU_Temperature_Issue : 20|1@1+ (1,0) [0|0] "" Vector__XXX
 SG_ APP_w022_ECU_EEPROM_Failure : 21|1@1+ (1,0) [0|0] "" Vector__XXX
 SG_ APP_w023_ECU_Cam_Statemismatc : 22|1@1+ (1,0) [0|0] "" Vector__XXX
 SG_ APP_w024_ECU_Watchdog_Reset : 23|1@1+ (1,0) [0|0] "" Vector__XXX
 SG_ APP_w025_LC_Steering_Override : 24|1@1+ (1,0) [0|0] "" Vector__XXX
 SG_ APP_w026_ECU_timingIssue : 25|1@1+ (1,0) [0|0] "" Vector__XXX
 SG_ APP_w027_ECU_Reset_Fault : 26|1@1+ (1,0) [0|0] "" Vector__XXX
 SG_ APP_w028_spi_rx_error : 27|1@1+ (1,0) [0|0] "" Vector__XXX
 SG_ APP_w029_spi_tx_error : 28|1@1+ (1,0) [0|0] "" Vector__XXX
 SG_ APP_w030_Heater_Issue : 29|1@1+ (1,0) [0|0] "" Vector__XXX
 SG_ APP_w031_canRxError : 30|1@1+ (1,0) [0|0] "" Vector__XXX
 SG_ APP_w032_canTxError : 31|1@1+ (1,0) [0|0] "" Vector__XXX
 SG_ APP_w033_gtwMia : 32|1@1+ (1,0) [0|0] "" Vector__XXX
 SG_ APP_w034_sccmMia : 33|1@1+ (1,0) [0|0] "" Vector__XXX
 SG_ APP_w035_espMia : 34|1@1+ (1,0) [0|0] "" Vector__XXX
 SG_ APP_w036_bdyMia : 35|1@1+ (1,0) [0|0] "" Vector__XXX
 SG_ APP_w037_camTacIssue : 36|1@1+ (1,0) [0|0] "" Vector__XXX
 SG_ APP_w038_camFailure : 37|1@1+ (1,0) [0|0] "" Vector__XXX
 SG_ APP_w039_sdm_rcm_Mia : 38|1@1+ (1,0) [0|0] "" Vector__XXX
 SG_ APP_w040_autopilotAngleSaturated : 39|1@1+ (1,0) [0|0] "" Vector__XXX
 SG_ APP_w041_autopilotRateSaturated : 40|1@1+ (1,0) [0|0] "" Vector__XXX
 SG_ APP_w042_autopilotAborting : 41|1@1+ (1,0) [0|0] "" Vector__XXX
 SG_ APP_w043_camLongRunTime : 42|1@1+ (1,0) [0|0] "" Vector__XXX
 SG_ APP_w044_appMobileyeFailure : 43|1@1+ (1,0) [0|0] "" Vector__XXX
 SG_ APP_w045_radMia : 44|1@1+ (1,0) [0|0] "" Vector__XXX
 SG_ APP_w046_eepromRecordAbsent : 45|1@1+ (1,0) [0|0] "" Vector__XXX
 SG_ APP_w047_edrEvent : 46|1@1+ (1,0) [0|0] "" Vector__XXX
 SG_ APP_w048_APP_Features_Disabled : 47|1@1+ (1,0) [0|0] "" Vector__XXX
 SG_ APP_w049_eyeqVersionMismatch : 48|1@1+ (1,0) [0|0] "" Vector__XXX
 SG_ APP_w050_aeb_event : 49|1@1+ (1,0) [0|0] "" Vector__XXX
 SG_ APP_w051_radcEcuIssue : 50|1@1+ (1,0) [0|0] "" Vector__XXX
 SG_ APP_w052_radcSensorIssue : 51|1@1+ (1,0) [0|0] "" Vector__XXX
 SG_ APP_w053_radcCommIssue : 52|1@1+ (1,0) [0|0] "" Vector__XXX
 SG_ APP_w054_camAutofix : 53|1@1+ (1,0) [0|0] "" Vector__XXX
 SG_ APP_w055_radcVersionMismatch : 54|1@1+ (1,0) [0|0] "" Vector__XXX
 SG_ APP_w056_diMia : 55|1@1+ (1,0) [0|0] "" Vector__XXX
 SG_ APP_w057_mcuMia : 56|1@1+ (1,0) [0|0] "" Vector__XXX
 SG_ APP_w058_epbMia : 57|1@1+ (1,0) [0|0] "" Vector__XXX
 SG_ APP_w059_parkMia : 58|1@1+ (1,0) [0|0] "" Vector__XXX
 SG_ APP_w060_fcw_event : 59|1@1+ (1,0) [0|0] "" Vector__XXX
 SG_ APP_w061_airSuspensionMia : 60|1@1+ (1,0) [0|0] "" Vector__XXX
 SG_ APP_w062_radcAlignment : 61|1@1+ (1,0) [0|0] "" Vector__XXX
 SG_ APP_w063_parkVersionMismatch : 62|1@1+ (1,0) [0|0] "" Vector__XXX
 SG_ APP_w064_epasMia : 63|1@1+ (1,0) [0|0] "" Vector__XXX

BO_ 810 DAS_warningMatrix0: 8 VEH
 SG_ DAS_w002_ldwDisabled : 1|1@1+ (1,0) [0|0] "" Vector__XXX
 SG_ DAS_w003_isaDisabled : 2|1@1+ (1,0) [0|0] "" Vector__XXX
 SG_ DAS_w004_accDisabled : 3|1@1+ (1,0) [0|0] "" Vector__XXX
 SG_ DAS_w005_fcwCancelled : 4|1@1+ (1,0) [0|0] "" Vector__XXX
 SG_ DAS_w006_aebCancelled : 5|1@1+ (1,0) [0|0] "" Vector__XXX
 SG_ DAS_w007_ahlbDisabled : 6|1@1+ (1,0) [0|0] "" Vector__XXX
 SG_ DAS_w008_parkDisabled : 7|1@1+ (1,0) [0|0] "" Vector__XXX
 SG_ DAS_w009_aebFault : 8|1@1+ (1,0) [0|0] "" Vector__XXX
 SG_ DAS_w010_radcCalibIssue : 9|1@1+ (1,0) [0|0] "" Vector__XXX
 SG_ DAS_w011_scaEvent : 10|1@1+ (1,0) [0|0] "" Vector__XXX
 SG_ DAS_w012_Cam_BootFailure : 11|1@1+ (1,0) [0|0] "" Vector__XXX
 SG_ DAS_w013_Cam_Watchdog : 12|1@1+ (1,0) [0|0] "" Vector__XXX
 SG_ DAS_w014_swAssert : 13|1@1+ (1,0) [0|0] "" Vector__XXX
 SG_ DAS_w015_Camera_Failsafes : 14|1@1+ (1,0) [0|0] "" Vector__XXX
 SG_ DAS_w016_aeb_e_event : 15|1@1+ (1,0) [0|0] "" Vector__XXX
 SG_ DAS_w017_Cam_Msg_MIA : 16|1@1+ (1,0) [0|0] "" Vector__XXX
 SG_ DAS_w018_ECU_Power_Issue : 17|1@1+ (1,0) [0|0] "" Vector__XXX
 SG_ DAS_w019_ECU_Stack_Overflow : 18|1@1+ (1,0) [0|0] "" Vector__XXX
 SG_ DAS_w020_ECU_checkstopError : 19|1@1+ (1,0) [0|0] "" Vector__XXX
 SG_ DAS_w021_ECU_Temperature_Issue : 20|1@1+ (1,0) [0|0] "" Vector__XXX
 SG_ DAS_w022_ECU_EEPROM_Failure : 21|1@1+ (1,0) [0|0] "" Vector__XXX
 SG_ DAS_w023_ECU_Cam_Statemismatc : 22|1@1+ (1,0) [0|0] "" Vector__XXX
 SG_ DAS_w024_ECU_Watchdog_Reset : 23|1@1+ (1,0) [0|0] "" Vector__XXX
 SG_ DAS_w025_LC_Steering_Override : 24|1@1+ (1,0) [0|0] "" Vector__XXX
 SG_ DAS_w026_ECU_timingIssue : 25|1@1+ (1,0) [0|0] "" Vector__XXX
 SG_ DAS_w027_ECU_Reset_Fault : 26|1@1+ (1,0) [0|0] "" Vector__XXX
 SG_ DAS_w028_spi_rx_error : 27|1@1+ (1,0) [0|0] "" Vector__XXX
 SG_ DAS_w029_spi_tx_error : 28|1@1+ (1,0) [0|0] "" Vector__XXX
 SG_ DAS_w030_Heater_Issue : 29|1@1+ (1,0) [0|0] "" Vector__XXX
 SG_ DAS_w031_canRxError : 30|1@1+ (1,0) [0|0] "" Vector__XXX
 SG_ DAS_w032_canTxError : 31|1@1+ (1,0) [0|0] "" Vector__XXX
 SG_ DAS_w033_gtwMia : 32|1@1+ (1,0) [0|0] "" Vector__XXX
 SG_ DAS_w034_sccmMia : 33|1@1+ (1,0) [0|0] "" Vector__XXX
 SG_ DAS_w035_espMia : 34|1@1+ (1,0) [0|0] "" Vector__XXX
 SG_ DAS_w036_bdyMia : 35|1@1+ (1,0) [0|0] "" Vector__XXX
 SG_ DAS_w037_camTacIssue : 36|1@1+ (1,0) [0|0] "" Vector__XXX
 SG_ DAS_w038_camFailure : 37|1@1+ (1,0) [0|0] "" Vector__XXX
 SG_ DAS_w039_sdm_rcm_Mia : 38|1@1+ (1,0) [0|0] "" Vector__XXX
 SG_ DAS_w040_autopilotAngleSaturated : 39|1@1+ (1,0) [0|0] "" Vector__XXX
 SG_ DAS_w041_autopilotRateSaturated : 40|1@1+ (1,0) [0|0] "" Vector__XXX
 SG_ DAS_w042_autopilotAborting : 41|1@1+ (1,0) [0|0] "" Vector__XXX
 SG_ DAS_w043_camLongRunTime : 42|1@1+ (1,0) [0|0] "" Vector__XXX
 SG_ DAS_w044_appMobileyeFailure : 43|1@1+ (1,0) [0|0] "" Vector__XXX
 SG_ DAS_w045_radMia : 44|1@1+ (1,0) [0|0] "" Vector__XXX
 SG_ DAS_w046_eepromRecordAbsent : 45|1@1+ (1,0) [0|0] "" Vector__XXX
 SG_ DAS_w047_edrEvent : 46|1@1+ (1,0) [0|0] "" Vector__XXX
 SG_ DAS_w048_DAS_Features_Disabled : 47|1@1+ (1,0) [0|0] "" Vector__XXX
 SG_ DAS_w049_eyeqVersionMismatch : 48|1@1+ (1,0) [0|0] "" Vector__XXX
 SG_ DAS_w050_aeb_event : 49|1@1+ (1,0) [0|0] "" Vector__XXX
 SG_ DAS_w051_radcEcuIssue : 50|1@1+ (1,0) [0|0] "" Vector__XXX
 SG_ DAS_w052_radcSensorIssue : 51|1@1+ (1,0) [0|0] "" Vector__XXX
 SG_ DAS_w053_radcCommIssue : 52|1@1+ (1,0) [0|0] "" Vector__XXX
 SG_ DAS_w054_camAutofix : 53|1@1+ (1,0) [0|0] "" Vector__XXX
 SG_ DAS_w055_radcVersionMismatch : 54|1@1+ (1,0) [0|0] "" Vector__XXX
 SG_ DAS_w056_diMia : 55|1@1+ (1,0) [0|0] "" Vector__XXX
 SG_ DAS_w057_mcuMia : 56|1@1+ (1,0) [0|0] "" Vector__XXX
 SG_ DAS_w058_epbMia : 57|1@1+ (1,0) [0|0] "" Vector__XXX
 SG_ DAS_w059_parkMia : 58|1@1+ (1,0) [0|0] "" Vector__XXX
 SG_ DAS_w060_fcw_event : 59|1@1+ (1,0) [0|0] "" Vector__XXX
 SG_ DAS_w061_airSuspensionMia : 60|1@1+ (1,0) [0|0] "" Vector__XXX
 SG_ DAS_w062_radcAlignment : 61|1@1+ (1,0) [0|0] "" Vector__XXX
 SG_ DAS_w063_parkVersionMismatch : 62|1@1+ (1,0) [0|0] "" Vector__XXX
 SG_ DAS_w064_epasMia : 63|1@1+ (1,0) [0|0] "" Vector__XXX

BO_ 811 APS_warningMatrix0: 8 CH
 SG_ APS_w001_DEPRECATED : 0|1@1+ (1,0) [0|0] "" Vector__XXX
 SG_ APS_w002_ldwDisabled : 1|1@1+ (1,0) [0|0] "" Vector__XXX
 SG_ APS_w003_isaDisabled : 2|1@1+ (1,0) [0|0] "" Vector__XXX
 SG_ APS_w004_accDisabled : 3|1@1+ (1,0) [0|0] "" Vector__XXX
 SG_ APS_w005_fcwCancelled : 4|1@1+ (1,0) [0|0] "" Vector__XXX
 SG_ APS_w006_aebCancelled : 5|1@1+ (1,0) [0|0] "" Vector__XXX
 SG_ APS_w007_ahlbDisabled : 6|1@1+ (1,0) [0|0] "" Vector__XXX
 SG_ APS_w008_parkDisabled : 7|1@1+ (1,0) [0|0] "" Vector__XXX
 SG_ APS_w009_aebFault : 8|1@1+ (1,0) [0|0] "" Vector__XXX
 SG_ APS_w010_radcCalibIssue : 9|1@1+ (1,0) [0|0] "" Vector__XXX
 SG_ APS_w011_scaEvent : 10|1@1+ (1,0) [0|0] "" Vector__XXX
 SG_ APS_w012_Cam_BootFailure : 11|1@1+ (1,0) [0|0] "" Vector__XXX
 SG_ APS_w013_Cam_Watchdog : 12|1@1+ (1,0) [0|0] "" Vector__XXX
 SG_ APS_w014_swAssert : 13|1@1+ (1,0) [0|0] "" Vector__XXX
 SG_ APS_w015_Camera_Failsafes : 14|1@1+ (1,0) [0|0] "" Vector__XXX
 SG_ APS_w016_aeb_e_event : 15|1@1+ (1,0) [0|0] "" Vector__XXX
 SG_ APS_w017_Cam_Msg_MIA : 16|1@1+ (1,0) [0|0] "" Vector__XXX
 SG_ APS_w018_ECU_Power_Issue : 17|1@1+ (1,0) [0|0] "" Vector__XXX
 SG_ APS_w019_ECU_Stack_Overflow : 18|1@1+ (1,0) [0|0] "" Vector__XXX
 SG_ APS_w020_ECU_checkstopError : 19|1@1+ (1,0) [0|0] "" Vector__XXX
 SG_ APS_w021_ECU_Temperature_Issue : 20|1@1+ (1,0) [0|0] "" Vector__XXX
 SG_ APS_w022_ECU_EEPROM_Failure : 21|1@1+ (1,0) [0|0] "" Vector__XXX
 SG_ APS_w023_ECU_Cam_Statemismatc : 22|1@1+ (1,0) [0|0] "" Vector__XXX
 SG_ APS_w024_ECU_Watchdog_Reset : 23|1@1+ (1,0) [0|0] "" Vector__XXX
 SG_ APS_w025_LC_Steering_Override : 24|1@1+ (1,0) [0|0] "" Vector__XXX
 SG_ APS_w026_ECU_timingIssue : 25|1@1+ (1,0) [0|0] "" Vector__XXX
 SG_ APS_w027_ECU_Reset_Fault : 26|1@1+ (1,0) [0|0] "" Vector__XXX
 SG_ APS_w028_spi_rx_error : 27|1@1+ (1,0) [0|0] "" Vector__XXX
 SG_ APS_w029_spi_tx_error : 28|1@1+ (1,0) [0|0] "" Vector__XXX
 SG_ APS_w030_Heater_Issue : 29|1@1+ (1,0) [0|0] "" Vector__XXX
 SG_ APS_w031_canRxError : 30|1@1+ (1,0) [0|0] "" Vector__XXX
 SG_ APS_w032_canTxError : 31|1@1+ (1,0) [0|0] "" Vector__XXX
 SG_ APS_w033_gtwMia : 32|1@1+ (1,0) [0|0] "" Vector__XXX
 SG_ APS_w034_sccmMia : 33|1@1+ (1,0) [0|0] "" Vector__XXX
 SG_ APS_w035_espMia : 34|1@1+ (1,0) [0|0] "" Vector__XXX
 SG_ APS_w036_bdyMia : 35|1@1+ (1,0) [0|0] "" Vector__XXX
 SG_ APS_w037_camTacIssue : 36|1@1+ (1,0) [0|0] "" Vector__XXX
 SG_ APS_w038_camFailure : 37|1@1+ (1,0) [0|0] "" Vector__XXX
 SG_ APS_w039_sdm_rcm_Mia : 38|1@1+ (1,0) [0|0] "" Vector__XXX
 SG_ APS_w040_autopilotAngleSaturated : 39|1@1+ (1,0) [0|0] "" Vector__XXX
 SG_ APS_w041_autopilotRateSaturated : 40|1@1+ (1,0) [0|0] "" Vector__XXX
 SG_ APS_w042_autopilotAborting : 41|1@1+ (1,0) [0|0] "" Vector__XXX
 SG_ APS_w043_camLongRunTime : 42|1@1+ (1,0) [0|0] "" Vector__XXX
 SG_ APS_w044_appMobileyeFailure : 43|1@1+ (1,0) [0|0] "" Vector__XXX
 SG_ APS_w045_radMia : 44|1@1+ (1,0) [0|0] "" Vector__XXX
 SG_ APS_w046_eepromRecordAbsent : 45|1@1+ (1,0) [0|0] "" Vector__XXX
 SG_ APS_w047_edrEvent : 46|1@1+ (1,0) [0|0] "" Vector__XXX
 SG_ APS_w048_DAS_Features_Disabled : 47|1@1+ (1,0) [0|0] "" Vector__XXX
 SG_ APS_w049_eyeqVersionMismatch : 48|1@1+ (1,0) [0|0] "" Vector__XXX
 SG_ APS_w050_aeb_event : 49|1@1+ (1,0) [0|0] "" Vector__XXX
 SG_ APS_w051_radcEcuIssue : 50|1@1+ (1,0) [0|0] "" Vector__XXX
 SG_ APS_w052_radcSensorIssue : 51|1@1+ (1,0) [0|0] "" Vector__XXX
 SG_ APS_w053_radcCommIssue : 52|1@1+ (1,0) [0|0] "" Vector__XXX
 SG_ APS_w054_camAutofix : 53|1@1+ (1,0) [0|0] "" Vector__XXX
 SG_ APS_w055_radcVersionMismatch : 54|1@1+ (1,0) [0|0] "" Vector__XXX
 SG_ APS_w056_diMia : 55|1@1+ (1,0) [0|0] "" Vector__XXX
 SG_ APS_w057_mcuMia : 56|1@1+ (1,0) [0|0] "" Vector__XXX
 SG_ APS_w058_epbMia : 57|1@1+ (1,0) [0|0] "" Vector__XXX
 SG_ APS_w059_parkMia : 58|1@1+ (1,0) [0|0] "" Vector__XXX
 SG_ APS_w060_fcw_event : 59|1@1+ (1,0) [0|0] "" Vector__XXX
 SG_ APS_w061_tasMia : 60|1@1+ (1,0) [0|0] "" Vector__XXX
 SG_ APS_w062_radcAlignment : 61|1@1+ (1,0) [0|0] "" Vector__XXX
 SG_ APS_w063_parkVersionMismatch : 62|1@1+ (1,0) [0|0] "" Vector__XXX
 SG_ APS_w064_epasMia : 63|1@1+ (1,0) [0|0] "" Vector__XXX

BO_ 812 CC_logData: 8 VEH
 SG_ CC_logIndex M : 0|8@1+ (1,0) [0|0] "" Vector__XXX
 SG_ CC_activeConnectorID m0 : 8|8@1+ (1,0) [0|0] "" Vector__XXX
 SG_ CC_temperature1 m0 : 16|8@1- (1,88) [0|0] "DegC" Vector__XXX
 SG_ CC_temperature2 m0 : 24|8@1- (1,88) [0|0] "DegC" Vector__XXX
 SG_ CC_temperature3 m0 : 32|8@1- (1,88) [0|0] "DegC" Vector__XXX
 SG_ CC_contactor1Closed m0 : 40|2@1+ (1,0) [0|0] "" Vector__XXX
 SG_ CC_contactor2Closed m0 : 42|2@1+ (1,0) [0|0] "" Vector__XXX
 SG_ CC_temperature4 m0 : 44|8@1- (1,88) [0|0] "DegC" Vector__XXX
 SG_ CC_conn1Current m1 : 8|8@1+ (0.5,0) [0|0] "A" Vector__XXX
 SG_ CC_conn2Current m2 : 8|8@1+ (0.5,0) [0|0] "A" Vector__XXX
 SG_ CC_conn3Current m3 : 8|8@1+ (0.5,0) [0|0] "A" Vector__XXX
 SG_ CC_conn4Current m4 : 8|8@1+ (0.5,0) [0|0] "A" Vector__XXX
 SG_ CC_lifetimei2t m10 : 32|32@1+ (0.1,0) [0|0] "A2h" Vector__XXX
 SG_ CC_lifetimeCtrCycles m11 : 8|28@1+ (1,0) [0|0] "" Vector__XXX
 SG_ CC_lifetimeCtrCyclesLoaded m11 : 36|28@1+ (1,0) [0|0] "" Vector__XXX
 SG_ CC_lifetimeAlertCount m12 : 8|28@1+ (1,0) [0|0] "" Vector__XXX
 SG_ CC_lifetimVEHermalFoldbacks m12 : 36|28@1+ (1,0) [0|0] "" Vector__XXX
 SG_ CC_lifetimeAvgStartupTemp m13 : 36|28@1- (0.1,0) [0|0] "degC" Vector__XXX

BO_ 813 IBST_info: 8 CH
 SG_ IBST_infoIndex M : 0|8@1+ (1,0) [0|0] "" Vector__XXX
 SG_ IBST_infoBuildType m10 : 8|8@1+ (1,0) [0|0] "" Vector__XXX
 SG_ IBST_infoComponentID m10 : 48|16@1+ (1,0) [0|0] "" Vector__XXX
 SG_ IBST_infoPcbaID m11 : 16|8@1+ (1,0) [0|0] "" Vector__XXX
 SG_ IBST_infoAssemblyID m11 : 24|8@1+ (1,0) [0|0] "" Vector__XXX
 SG_ IBST_infoUsageID m11 : 32|16@1+ (1,0) [0|0] "" Vector__XXX
 SG_ IBST_infoBootUdsProtoVersion m20 : 8|8@1+ (1,0) [0|0] "" Vector__XXX
 SG_ IBST_infoBootloaderCRC m20 : 32|32@1+ (1,0) [0|0] "" Vector__XXX
 SG_ IBST_infoApplicationCRC m13 : 32|32@1+ (1,0) [0|0] "" Vector__XXX
 SG_ IBST_infoVariantCRC m22 : 32|32@1+ (1,0) [0|0] "" Vector__XXX

BO_ 814 PARK_sensorStatusFront: 5 CH
 SG_ PARK_frontDtcPresent : 26|2@1+ (1,0) [0|0] "" Vector__XXX
 SG_ PARK_frontLeftMiddleSensorState : 4|2@1+ (1,0) [0|0] "" Vector__XXX
 SG_ PARK_frontLeftRawDistData : 8|8@1+ (1,0) [0|0] "cm" Vector__XXX
 SG_ PARK_frontLeftSensorState : 6|2@1+ (1,0) [0|0] "" Vector__XXX
 SG_ PARK_frontRightMiddleSensorState : 2|2@1+ (1,0) [0|0] "" Vector__XXX
 SG_ PARK_frontRightRawDistData : 16|8@1+ (1,0) [0|0] "cm" Vector__XXX
 SG_ PARK_frontRightSensorState : 0|2@1+ (1,0) [0|0] "" Vector__XXX
 SG_ PARK_sensorStatusFrontChecksum : 32|8@1+ (1,0) [0|0] "" Vector__XXX
 SG_ PARK_sensorStatusFrontCounter : 28|4@1+ (1,0) [0|0] "" Vector__XXX
 SG_ PARK_systemStatusFront : 24|2@1+ (1,0) [0|0] "" Vector__XXX

BO_ 815 SCM_alertMatrix1: 8 CH
 SG_ SCM_a001_hwDSPfault : 0|1@1+ (1,0) [0|0] "" Vector__XXX
 SG_ SCM_a002_hwIbatOC : 1|1@1+ (1,0) [0|0] "" Vector__XXX
 SG_ SCM_a003_hwCordOT : 2|1@1+ (1,0) [0|0] "" Vector__XXX
 SG_ SCM_a004_hwVbusOV : 3|1@1+ (1,0) [0|0] "" Vector__XXX
 SG_ SCM_a005_hwHVIL : 4|1@1+ (1,0) [0|0] "" Vector__XXX
 SG_ SCM_a006_hwWeld_V1 : 5|1@1+ (1,0) [0|0] "" Vector__XXX
 SG_ SCM_a007_hwWeld_V2 : 6|1@1+ (1,0) [0|0] "" Vector__XXX
 SG_ SCM_a008_hwOpen_V1 : 7|1@1+ (1,0) [0|0] "" Vector__XXX
 SG_ SCM_a009_hwOpen_V2 : 8|1@1+ (1,0) [0|0] "" Vector__XXX
 SG_ SCM_a010_hwIllegalCntrCmdV1 : 9|1@1+ (1,0) [0|0] "" Vector__XXX
 SG_ SCM_a011_hwIllegalCntrCmdInt : 10|1@1+ (1,0) [0|0] "" Vector__XXX
 SG_ SCM_a012_hwIllegalCntrCmdV2 : 11|1@1+ (1,0) [0|0] "" Vector__XXX
 SG_ SCM_a013_cordTempHiFoldBk : 12|1@1+ (1,0) [0|0] "" Vector__XXX
 SG_ SCM_a014_coolantTempHiFoldBk : 13|1@1+ (1,0) [0|0] "" Vector__XXX
 SG_ SCM_a015_unusedHW15 : 14|1@1+ (1,0) [0|0] "" Vector__XXX
 SG_ SCM_a016_unusedHW16 : 15|1@1+ (1,0) [0|0] "" Vector__XXX
 SG_ SCM_a017_unusedHW17 : 16|1@1+ (1,0) [0|0] "" Vector__XXX
 SG_ SCM_a018_unusedHW18 : 17|1@1+ (1,0) [0|0] "" Vector__XXX
 SG_ SCM_a019_unusedHW19 : 18|1@1+ (1,0) [0|0] "" Vector__XXX
 SG_ SCM_a020_unusedHW20 : 19|1@1+ (1,0) [0|0] "" Vector__XXX
 SG_ SCM_a021_unusedHW21 : 20|1@1+ (1,0) [0|0] "" Vector__XXX
 SG_ SCM_a022_fastChargeLimitActiveV1 : 21|1@1+ (1,0) [0|0] "" Vector__XXX
 SG_ SCM_a023_fastChargeLimitActiveV2 : 22|1@1+ (1,0) [0|0] "" Vector__XXX
 SG_ SCM_a024_emergencyShutdown : 23|1@1+ (1,0) [0|0] "" Vector__XXX
 SG_ SCM_a025_internalIsolationFault : 24|1@1+ (1,0) [0|0] "" Vector__XXX
 SG_ SCM_a026_internalIsolationLow : 25|1@1+ (1,0) [0|0] "" Vector__XXX
 SG_ SCM_a027_externalIsolationLow : 26|1@1+ (1,0) [0|0] "" Vector__XXX
 SG_ SCM_a028_isolationRationality : 27|1@1+ (1,0) [0|0] "" Vector__XXX
 SG_ SCM_a029_VbatOV : 28|1@1+ (1,0) [0|0] "" Vector__XXX
 SG_ SCM_a030_VbusOV : 29|1@1+ (1,0) [0|0] "" Vector__XXX
 SG_ SCM_a031_IbatOC : 30|1@1+ (1,0) [0|0] "" Vector__XXX
 SG_ SCM_a032_VBatRationality : 31|1@1+ (1,0) [0|0] "" Vector__XXX
 SG_ SCM_a033_VBusRationality : 32|1@1+ (1,0) [0|0] "" Vector__XXX
 SG_ SCM_a034_IBatRationality : 33|1@1+ (1,0) [0|0] "" Vector__XXX
 SG_ SCM_a035_unexpectedVbusBehavior : 34|1@1+ (1,0) [0|0] "" Vector__XXX
 SG_ SCM_a036_internalContactorWelded : 35|1@1+ (1,0) [0|0] "" Vector__XXX
 SG_ SCM_a037_outputContactorWelded : 36|1@1+ (1,0) [0|0] "" Vector__XXX
 SG_ SCM_a038_contactorFailedOpen : 37|1@1+ (1,0) [0|0] "" Vector__XXX
 SG_ SCM_a039_ibatRegulation : 38|1@1+ (1,0) [0|0] "" Vector__XXX
 SG_ SCM_a040_plus12VOutOfRange : 39|1@1+ (1,0) [0|0] "" Vector__XXX
 SG_ SCM_a041_minus12VOutOfRange : 40|1@1+ (1,0) [0|0] "" Vector__XXX
 SG_ SCM_a042_pilotOutOfRange : 41|1@1+ (1,0) [0|0] "" Vector__XXX
 SG_ SCM_a043_pilotRationality : 42|1@1+ (1,0) [0|0] "" Vector__XXX
 SG_ SCM_a044_proximityRationality : 43|1@1+ (1,0) [0|0] "" Vector__XXX
 SG_ SCM_a045_pcbaOT : 44|1@1+ (1,0) [0|0] "" Vector__XXX
 SG_ SCM_a046_coolantOT : 45|1@1+ (1,0) [0|0] "" Vector__XXX
 SG_ SCM_a047_cordOT : 46|1@1+ (1,0) [0|0] "" Vector__XXX
 SG_ SCM_a048_ambientOT : 47|1@1+ (1,0) [0|0] "" Vector__XXX
 SG_ SCM_a049_pcbaTempRationality : 48|1@1+ (1,0) [0|0] "" Vector__XXX
 SG_ SCM_a050_coolantTempRationality : 49|1@1+ (1,0) [0|0] "" Vector__XXX
 SG_ SCM_a051_cordTempRationality : 50|1@1+ (1,0) [0|0] "" Vector__XXX
 SG_ SCM_a052_ambientTempRationality : 51|1@1+ (1,0) [0|0] "" Vector__XXX
 SG_ SCM_a053_unexpectedThermalBehavi : 52|1@1+ (1,0) [0|0] "" Vector__XXX
 SG_ SCM_a054_pumpRegulation : 53|1@1+ (1,0) [0|0] "" Vector__XXX
 SG_ SCM_a055_coolantLevelLow : 54|1@1+ (1,0) [0|0] "" Vector__XXX
 SG_ SCM_a056_stateTransitionDenied : 55|1@1+ (1,0) [0|0] "" Vector__XXX
 SG_ SCM_a057_watchdogReset : 56|1@1+ (1,0) [0|0] "" Vector__XXX
 SG_ SCM_a058_adcRef : 57|1@1+ (1,0) [0|0] "" Vector__XXX
 SG_ SCM_a059_memoryError : 58|1@1+ (1,0) [0|0] "" Vector__XXX
 SG_ SCM_a060_swHVIL : 59|1@1+ (1,0) [0|0] "" Vector__XXX
 SG_ SCM_a061_postOutOfService : 60|1@1+ (1,0) [0|0] "" Vector__XXX
 SG_ SCM_a062_unused : 61|1@1+ (1,0) [0|0] "" Vector__XXX
 SG_ SCM_a063_canRationality : 62|1@1+ (1,0) [0|0] "" Vector__XXX
 SG_ SCM_a064_vehicleCommandTimeout : 63|1@1+ (1,0) [0|0] "" Vector__XXX

BO_ 816 SCCM_info: 8 VEH
 SG_ SCCM_infoIndex M : 0|8@1+ (1,0) [0|0] "" Vector__XXX
 SG_ SCCM_infoBuildType m10 : 8|8@1+ (1,0) [0|0] "" Vector__XXX
 SG_ SCCM_infoBuildConfigId m10 : 16|16@1+ (1,0) [0|0] "" Vector__XXX
 SG_ SCCM_infoHardwareId m10 : 32|16@1+ (1,0) [0|0] "" Vector__XXX
 SG_ SCCM_infoComponentId m10 : 48|16@1+ (1,0) [0|0] "" Vector__XXX
 SG_ SCCM_infoPcbaId m11 : 16|8@1+ (1,0) [0|0] "" Vector__XXX
 SG_ SCCM_infoAssemblyId m11 : 24|8@1+ (1,0) [0|0] "" Vector__XXX
 SG_ SCCM_infoUsageId m11 : 32|16@1+ (1,0) [0|0] "" Vector__XXX
 SG_ SCCM_infoSubUsageId m11 : 48|16@1+ (1,0) [0|0] "" Vector__XXX
 SG_ SCCM_infoPlatformType m13 : 8|8@1+ (1,0) [0|0] "" Vector__XXX
 SG_ SCCM_infoAppCrc m13 : 32|32@0+ (1,0) [0|0] "" Vector__XXX
 SG_ SCCM_infoBootSvnRev m14 : 8|24@1+ (1,0) [0|0] "" Vector__XXX
 SG_ SCCM_infoBootSvnUrlHash m14 : 32|32@1+ (1,0) [0|0] "" Vector__XXX
 SG_ SCCM_infoSubcomponent1Version m16 : 16|32@1+ (1,0) [0|0] "" Vector__XXX
 SG_ SCCM_infoAppSvnHash m17 : 10|54@1+ (4,0) [0|0] "" Vector__XXX
 SG_ SCCM_infoBootSvnHash m18 : 10|54@1+ (4,0) [0|0] "" Vector__XXX
 SG_ SCCM_infoUdsProtoVersion m20 : 8|8@1+ (1,0) [0|0] "" Vector__XXX
 SG_ SCCM_infoBootCrc m20 : 32|32@1+ (1,0) [0|0] "" Vector__XXX

BO_ 817 EPAS3P_info: 8 VEH
 SG_ EPAS3P_infoIndex M : 0|8@1+ (1,0) [0|0] "" Vector__XXX
 SG_ EPAS3P_infoBuildType m10 : 8|8@1+ (1,0) [0|0] "" Vector__XXX
 SG_ EPAS3P_infoComponentID m10 : 48|16@1+ (1,0) [0|0] "" Vector__XXX
 SG_ EPAS3P_infoPcbaID m11 : 16|8@1+ (1,0) [0|0] "" Vector__XXX
 SG_ EPAS3P_infoAssemblyID m11 : 24|8@1+ (1,0) [0|0] "" Vector__XXX
 SG_ EPAS3P_infoUsageID m11 : 32|16@1+ (1,0) [0|0] "" Vector__XXX
 SG_ EPAS3P_infoBootUdsProtoVersion m20 : 8|8@1+ (1,0) [0|0] "" Vector__XXX
 SG_ EPAS3P_infoBootloaderCRC m20 : 32|32@1+ (1,0) [0|0] "" Vector__XXX
 SG_ EPAS3P_infoApplicationCRC m13 : 32|32@1+ (1,0) [0|0] "" Vector__XXX

BO_ 818 BMS_bmbMinMax: 6 VEH
 SG_ BMS_bmbMinMaxMultiplexer M : 0|2@1+ (1,0) [0|0] "" Vector__XXX
 SG_ BMS_thermistorNumTMax m0 : 2|4@1+ (1,0) [0|0] "" Vector__XXX
 SG_ BMS_thermistorNumTMin m0 : 8|4@1+ (1,0) [0|0] "" Vector__XXX
 SG_ BMS_thermistorTMax m0 : 16|8@1+ (0.5,-40) [0|0] "DegC" Vector__XXX
 SG_ BMS_thermistorTMin m0 : 24|8@1+ (0.5,-40) [0|0] "DegC" Vector__XXX
 SG_ BMS_modelTMax m0 : 32|8@1+ (0.5,-40) [0|0] "DegC" Vector__XXX
 SG_ BMS_modelTMin m0 : 40|8@1+ (0.5,-40) [0|0] "DegC" Vector__XXX
 SG_ BMS_brickVoltageMax m1 : 2|12@1+ (0.002,0) [0|0] "V" Vector__XXX
 SG_ BMS_brickVoltageMin m1 : 16|12@1+ (0.002,0) [0|0] "V" Vector__XXX
 SG_ BMS_brickNumVoltageMax m1 : 32|7@1+ (1,1) [0|0] "" Vector__XXX
 SG_ BMS_brickNumVoltageMin m1 : 40|7@1+ (1,1) [0|0] "" Vector__XXX

BO_ 819 UI_chargeRequest: 4 VEH
 SG_ UI_acChargeCurrentLimit : 8|7@1+ (1,0) [0|0] "A" Vector__XXX
 SG_ UI_chargeEnableRequest : 2|1@1+ (1,0) [0|0] "" Vector__XXX
 SG_ UI_chargeTerminationPct : 16|10@1+ (0.1,0) [0|0] "%" Vector__XXX
 SG_ UI_closeChargePortDoorRequest : 1|1@1+ (1,0) [0|0] "" Vector__XXX
 SG_ UI_openChargePortDoorRequest : 0|1@1+ (1,0) [0|0] "" Vector__XXX
 SG_ UI_brickBalancingDisabled : 4|1@1+ (1,0) [0|1] ""  Receiver
 SG_ UI_brickVLoggingRequest : 3|1@1+ (1,0) [0|1] ""  Receiver
 SG_ UI_scheduledDepartureEnabled : 27|1@1+ (1,0) [0|1] ""  Receiver
 SG_ UI_smartAcChargingEnabled : 26|1@1+ (1,0) [0|1] ""  Receiver
 SG_ UI_cpInletHeaterRequest : 32|1@1+ (1,0) [0|0] ""  Receiver
 SG_ UI_socSnapshotExpirationTime : 28|4@1+ (1,2) [0|0] "weeks"  Receiver

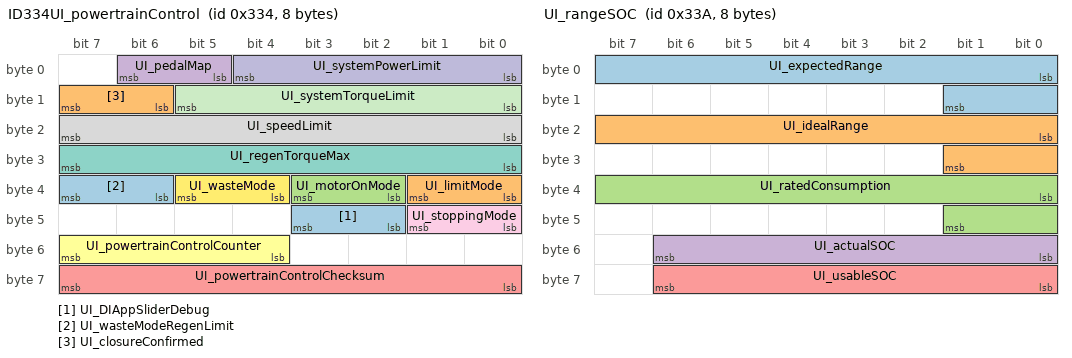
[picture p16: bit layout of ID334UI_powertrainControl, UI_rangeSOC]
BO_ 820 ID334UI_powertrainControl: 8 VehicleBus
 SG_ UI_DIAppSliderDebug : 42|2@1+ (1,0) [0|3] ""  Receiver
 SG_ UI_limitMode : 32|2@1+ (1,0) [0|3] ""  Receiver
 SG_ UI_motorOnMode : 34|2@1+ (1,0) [0|2] ""  Receiver
 SG_ UI_pedalMap : 5|2@1+ (1,0) [0|2] ""  Receiver
 SG_ UI_powertrainControlChecksum : 56|8@1+ (1,0) [0|255] ""  Receiver
 SG_ UI_powertrainControlCounter : 52|4@1+ (1,0) [0|15] ""  Receiver
 SG_ UI_regenTorqueMax : 24|8@1+ (0.5,0) [0|100] "%"  Receiver
 SG_ UI_speedLimit : 16|8@1+ (1,50) [50|285] "kph"  Receiver
 SG_ UI_stoppingMode : 40|2@1+ (1,0) [0|2] ""  Receiver
 SG_ UI_systemPowerLimit : 0|5@1+ (20,20) [20|640] "kW"  Receiver
 SG_ UI_systemTorqueLimit : 8|6@1+ (100,4000) [4000|10300] "Nm"  Receiver
 SG_ UI_wasteMode : 36|2@1+ (1,0) [0|2] ""  Receiver
 SG_ UI_wasteModeRegenLimit : 38|2@1+ (1,0) [0|3] ""  Receiver
 SG_ UI_closureConfirmed : 14|2@1+ (1,0) [0|2] ""  Receiver

BO_ 821 DIS_info: 8 VEH
 SG_ DIS_infoIndex M : 0|8@1+ (1,0) [0|0] "" Vector__XXX
 SG_ DIS_buildType m10 : 8|3@1+ (1,0) [0|0] "" Vector__XXX
 SG_ DIS_buildConfigurationId m10 : 16|16@1+ (1,0) [0|0] "" Vector__XXX
 SG_ DIS_hardwareId m10 : 32|8@1+ (1,0) [0|0] "" Vector__XXX
 SG_ DIS_componentId m10 : 48|16@1+ (1,0) [0|0] "" Vector__XXX
 SG_ DIS_pcbaId m11 : 16|8@1+ (1,0) [0|0] "" Vector__XXX
 SG_ DIS_assemblyId m11 : 24|8@1+ (1,0) [0|0] "" Vector__XXX
 SG_ DIS_usageId m11 : 32|16@1+ (1,0) [0|0] "" Vector__XXX
 SG_ DIS_subUsageId m11 : 48|16@1+ (1,0) [0|0] "" Vector__XXX
 SG_ DIS_applicationSvnRevision m12 : 8|24@1+ (1,0) [0|0] "" Vector__XXX
 SG_ DIS_applicationSvnUrlHash m12 : 32|32@1+ (1,0) [0|0] "" Vector__XXX
 SG_ DIS_applicationCrc m13 : 32|32@1+ (1,0) [0|0] "" Vector__XXX
 SG_ DIS_bootloaderSvnRevision m14 : 8|24@1+ (1,0) [0|0] "" Vector__XXX
 SG_ DIS_bootloaderSvnUrlHash m14 : 32|32@1+ (1,0) [0|0] "" Vector__XXX
 SG_ DIS_oilPumpBuildType m16 : 8|3@1+ (1,0) [0|0] "" Vector__XXX
 SG_ DIS_oilPumpAppCrc m16 : 16|32@1+ (1,0) [0|0] "" Vector__XXX
 SG_ DIS_appGitHash m17 : 10|54@1+ (4,0) [0|0] "" Vector__XXX
 SG_ DIS_bootGitHash m18 : 10|54@1+ (4,0) [0|0] "" Vector__XXX
 SG_ DIS_platformTyp m19 : 8|8@1+ (1,0) [0|0] "" Vector__XXX
 SG_ DIS_infoBootLdUdsProtocolVersion m20 : 8|8@1+ (1,0) [0|0] "" Vector__XXX
 SG_ DIS_bootloaderCrc m20 : 32|32@1+ (1,0) [0|0] "" Vector__XXX
 SG_ DIS_subcomponentGitHash m31 : 10|54@1+ (4,0) [0|0] "" Vector__XXX

BO_ 822 DI_maxRatedPower: 3 VEH
 SG_ DI_sysDrivePowerRated : 0|9@1+ (1,0) [0|0] "kW" Vector__XXX
 SG_ DI_sysRegenPowerRated : 16|8@1+ (1,-100) [0|0] "kW" Vector__XXX
 SG_ DI_performancePackage : 24|3@1+ (1,0) [0|4] ""  Receiver

VAL_ 822 DI_performancePackage 0 "BASE" 3 "BASE_PLUS" 1 "PERFORMANCE" 4 "SNA" ;

BO_ 824 UMC_alertMatrix1: 8 VEH
 SG_ UMC_a001_gndMonIntrptLineSide : 0|1@1+ (1,0) [0|0] "" Vector__XXX
 SG_ UMC_a002_GFCITripped : 1|1@1+ (1,0) [0|0] "" Vector__XXX
 SG_ UMC_a003_GFCISelfTestFault : 2|1@1+ (1,0) [0|0] "" Vector__XXX
 SG_ UMC_a004_inputOverVoltage : 3|1@1+ (1,0) [0|0] "" Vector__XXX
 SG_ UMC_a005_inputUnderVoltage : 4|1@1+ (1,0) [0|0] "" Vector__XXX
 SG_ UMC_a006_contactorWelded : 5|1@1+ (1,0) [0|0] "" Vector__XXX
 SG_ UMC_a007_pcbaOT : 6|1@1+ (1,0) [0|0] "" Vector__XXX
 SG_ UMC_a008_wallPlugOT : 7|1@1+ (1,0) [0|0] "" Vector__XXX
 SG_ UMC_a009_vehConnOT : 8|1@1+ (1,0) [0|0] "" Vector__XXX
 SG_ UMC_a010_inputOT : 9|1@1+ (1,0) [0|0] "" Vector__XXX
 SG_ UMC_a011_proxDisconnected : 10|1@1+ (1,0) [0|0] "" Vector__XXX
 SG_ UMC_a012_pilotFault : 11|1@1+ (1,0) [0|0] "" Vector__XXX
 SG_ UMC_a013_SA_Temperature : 12|1@1+ (1,0) [0|0] "" Vector__XXX
 SG_ UMC_a014_SA_Genealogy : 13|1@1+ (1,0) [0|0] "" Vector__XXX
 SG_ UMC_a015_SA_Connection : 14|1@1+ (1,0) [0|0] "" Vector__XXX
 SG_ UMC_a016_pcbaOTFoldback : 15|1@1+ (1,0) [0|0] "" Vector__XXX
 SG_ UMC_a017_wallPlugOTFoldback : 16|1@1+ (1,0) [0|0] "" Vector__XXX
 SG_ UMC_a018_vehConnOTFoldback : 17|1@1+ (1,0) [0|0] "" Vector__XXX
 SG_ UMC_a019_inputOTFoldback : 18|1@1+ (1,0) [0|0] "" Vector__XXX
 SG_ UMC_a020_applicationCRC : 19|1@1+ (1,0) [0|0] "" Vector__XXX
 SG_ UMC_a021_dataBus : 20|1@1+ (1,0) [0|0] "" Vector__XXX
 SG_ UMC_a022_criticalRAM : 21|1@1+ (1,0) [0|0] "" Vector__XXX
 SG_ UMC_a023_adcSelfTest : 22|1@1+ (1,0) [0|0] "" Vector__XXX

BO_ 825 VCSEC_authentication: 8 VEH
 SG_ VCSEC_MCUCommandType : 36|3@1+ (1,0) [0|0] "" Vector__XXX
 SG_ VCSEC_alarmStatus : 43|4@1+ (1,0) [0|0] "" Vector__XXX
 SG_ VCSEC_authRequested : 60|1@1+ (1,0) [0|0] "" Vector__XXX
 SG_ VCSEC_authenticationStatus : 16|2@1+ (1,0) [0|0] "" Vector__XXX
 SG_ VCSEC_chargePortLockStatus : 18|1@1+ (1,0) [0|0] "" Vector__XXX
 SG_ VCSEC_frunkRequest : 34|2@1+ (1,0) [0|0] "" Vector__XXX
 SG_ VCSEC_immobilizerState : 48|3@1+ (1,0) [0|0] "" Vector__XXX
 SG_ VCSEC_keyChannelIndexed : 56|4@1+ (1,0) [0|0] "" Vector__XXX
 SG_ VCSEC_leftFrontLockStatus : 19|1@1+ (1,0) [0|0] "" Vector__XXX
 SG_ VCSEC_leftRearLockStatus : 20|1@1+ (1,0) [0|0] "" Vector__XXX
 SG_ VCSEC_lockIndicationRequest : 51|3@1+ (1,0) [0|0] "" Vector__XXX
 SG_ VCSEC_lockRequestType : 24|5@1+ (1,0) [0|0] "" Vector__XXX
 SG_ VCSEC_numberOfPubKeysOnWhitelist : 6|5@1+ (1,0) [0|0] "" Vector__XXX
 SG_ VCSEC_prsntRsnDeltaD : 3|1@1+ (1,0) [0|0] "" Vector__XXX
 SG_ VCSEC_prsntRsnDeltaP : 39|1@1+ (1,0) [0|0] "" Vector__XXX
 SG_ VCSEC_prsntRsnDeltaR : 4|1@1+ (1,0) [0|0] "" Vector__XXX
 SG_ VCSEC_prsntRsnHighThresholdC : 0|1@1+ (1,0) [0|0] "" Vector__XXX
 SG_ VCSEC_prsntRsnHighThresholdD : 1|1@1+ (1,0) [0|0] "" Vector__XXX
 SG_ VCSEC_prsntRsnHighThresholdP : 2|1@1+ (1,0) [0|0] "" Vector__XXX
 SG_ VCSEC_prsntRsnHighThresholdR : 5|1@1+ (1,0) [0|0] "" Vector__XXX
 SG_ VCSEC_rightFrontLockStatus : 21|1@1+ (1,0) [0|0] "" Vector__XXX
 SG_ VCSEC_rightRearLockStatus : 22|1@1+ (1,0) [0|0] "" Vector__XXX
 SG_ VCSEC_simpleLockStatus : 54|2@1+ (1,0) [0|0] "" Vector__XXX
 SG_ VCSEC_summonRequest : 29|3@1+ (1,0) [0|0] "" Vector__XXX
 SG_ VCSEC_trunkLockStatus : 23|1@1+ (1,0) [0|0] "" Vector__XXX
 SG_ VCSEC_trunkRequest : 32|2@1+ (1,0) [0|0] "" Vector__XXX
 SG_ VCSEC_usingModifiedMACAddress : 40|1@1+ (1,0) [0|0] "" Vector__XXX
 SG_ VCSEC_vehicleLockStatus : 12|4@1+ (1,0) [0|0] "" Vector__XXX

BO_ 826 UI_rangeSOC: 8 VEH
 SG_ UI_expectedRange : 0|10@1+ (1.6,0) [0|1023] "km" Vector__XXX
 SG_ UI_idealRange : 16|10@1+ (1.6,0) [0|1023] "km" Vector__XXX
 SG_ UI_ratedConsumption : 32|10@1+ (0.625,0) [0|1023] "Wh/km" Vector__XXX
 SG_ UI_actualSOC : 48|7@1+ (1,0) [0|127] "%" Vector__XXX
 SG_ UI_usableSOC : 56|7@1+ (1,0) [0|127] "%" Vector__XXX

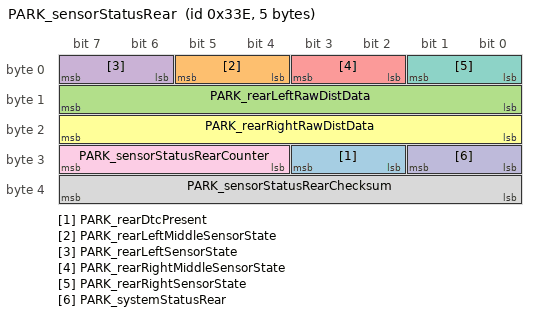
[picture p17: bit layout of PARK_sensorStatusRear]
BO_ 830 PARK_sensorStatusRear: 5 CH
 SG_ PARK_rearDtcPresent : 26|2@1+ (1,0) [0|0] "" Vector__XXX
 SG_ PARK_rearLeftMiddleSensorState : 4|2@1+ (1,0) [0|0] "" Vector__XXX
 SG_ PARK_rearLeftRawDistData : 8|8@1+ (1,0) [0|0] "cm" Vector__XXX
 SG_ PARK_rearLeftSensorState : 6|2@1+ (1,0) [0|0] "" Vector__XXX
 SG_ PARK_rearRightMiddleSensorState : 2|2@1+ (1,0) [0|0] "cm" Vector__XXX
 SG_ PARK_rearRightRawDistData : 16|8@1+ (1,0) [0|0] "cm" Vector__XXX
 SG_ PARK_rearRightSensorState : 0|2@1+ (1,0) [0|0] "" Vector__XXX
 SG_ PARK_sensorStatusRearChecksum : 32|8@1+ (1,0) [0|0] "" Vector__XXX
 SG_ PARK_sensorStatusRearCounter : 28|4@1+ (1,0) [0|0] "" Vector__XXX
 SG_ PARK_systemStatusRear : 24|2@1+ (1,0) [0|0] "" Vector__XXX

BO_ 831 FC_alertMatrix2: 8 VEH
 SG_ FC_a065_userData : 0|1@1+ (1,0) [0|0] "" Vector__XXX

BA_DEF_ BO_  "GenMsgSendType" ENUM  "Cyclic";
BA_DEF_ BO_  "GenMsgCycleTime" INT 0 10000;
BA_ "GenMsgSendType" BO_ 809 0;
BA_ "GenMsgCycleTime" BO_ 809 1000;
BA_ "GenMsgSendType" BO_ 811 0;
BA_ "GenMsgCycleTime" BO_ 811 1000;
BA_ "GenMsgSendType" BO_ 800 0;
BA_ "GenMsgCycleTime" BO_ 800 1000;
BA_ "GenMsgSendType" BO_ 818 0;
BA_ "GenMsgCycleTime" BO_ 818 1000;
BA_ "GenMsgSendType" BO_ 690 0;
BA_ "GenMsgCycleTime" BO_ 690 100;
BA_ "GenMsgSendType" BO_ 722 0;
BA_ "GenMsgCycleTime" BO_ 722 100;
BA_ "GenMsgSendType" BO_ 768 0;
BA_ "GenMsgCycleTime" BO_ 768 1000;
BA_ "GenMsgSendType" BO_ 658 0;
BA_ "GenMsgCycleTime" BO_ 658 100;
BA_ "GenMsgSendType" BO_ 786 0;
BA_ "GenMsgCycleTime" BO_ 786 1000;
BA_ "GenMsgSendType" BO_ 754 0;
BA_ "GenMsgCycleTime" BO_ 754 100;
BA_ "GenMsgSendType" BO_ 796 0;
BA_ "GenMsgCycleTime" BO_ 796 100;
BA_ "GenMsgSendType" BO_ 797 0;
BA_ "GenMsgCycleTime" BO_ 797 100;
BA_ "GenMsgSendType" BO_ 812 0;
BA_ "GenMsgCycleTime" BO_ 812 1000;
BA_ "GenMsgSendType" BO_ 798 0;
BA_ "GenMsgCycleTime" BO_ 798 1000;
BA_ "GenMsgSendType" BO_ 697 0;
BA_ "GenMsgCycleTime" BO_ 697 40;
BA_ "GenMsgSendType" BO_ 777 0;
BA_ "GenMsgCycleTime" BO_ 777 30;
BA_ "GenMsgSendType" BO_ 810 0;
BA_ "GenMsgCycleTime" BO_ 810 1000;
BA_ "GenMsgSendType" BO_ 821 0;
BA_ "GenMsgCycleTime" BO_ 821 1000;
BA_ "GenMsgSendType" BO_ 741 0;
BA_ "GenMsgCycleTime" BO_ 741 10;
BA_ "GenMsgSendType" BO_ 694 0;
BA_ "GenMsgCycleTime" BO_ 694 100;
BA_ "GenMsgSendType" BO_ 646 0;
BA_ "GenMsgCycleTime" BO_ 646 100;
BA_ "GenMsgSendType" BO_ 822 0;
BA_ "GenMsgCycleTime" BO_ 822 1000;
BA_ "GenMsgSendType" BO_ 789 0;
BA_ "GenMsgCycleTime" BO_ 789 1000;
BA_ "GenMsgSendType" BO_ 817 0;
BA_ "GenMsgCycleTime" BO_ 817 1000;
BA_ "GenMsgSendType" BO_ 785 0;
BA_ "GenMsgCycleTime" BO_ 785 1000;
BA_ "GenMsgSendType" BO_ 648 0;
BA_ "GenMsgCycleTime" BO_ 648 100;
BA_ "GenMsgSendType" BO_ 681 0;
BA_ "GenMsgCycleTime" BO_ 681 100;
BA_ "GenMsgSendType" BO_ 744 0;
BA_ "GenMsgCycleTime" BO_ 744 100;
BA_ "GenMsgSendType" BO_ 808 0;
BA_ "GenMsgCycleTime" BO_ 808 10000;
BA_ "GenMsgSendType" BO_ 805 0;
BA_ "GenMsgCycleTime" BO_ 805 1000;
BA_ "GenMsgSendType" BO_ 831 0;
BA_ "GenMsgCycleTime" BO_ 831 1000;
BA_ "GenMsgSendType" BO_ 784 0;
BA_ "GenMsgCycleTime" BO_ 784 10000;
BA_ "GenMsgSendType" BO_ 813 0;
BA_ "GenMsgCycleTime" BO_ 813 10000;
BA_ "GenMsgSendType" BO_ 771 0;
BA_ "GenMsgCycleTime" BO_ 771 500;
BA_ "GenMsgSendType" BO_ 806 0;
BA_ "GenMsgCycleTime" BO_ 806 1000;
BA_ "GenMsgSendType" BO_ 814 0;
BA_ "GenMsgCycleTime" BO_ 814 100;
BA_ "GenMsgSendType" BO_ 830 0;
BA_ "GenMsgCycleTime" BO_ 830 100;
BA_ "GenMsgSendType" BO_ 782 0;
BA_ "GenMsgCycleTime" BO_ 782 250;
BA_ "GenMsgSendType" BO_ 708 0;
BA_ "GenMsgCycleTime" BO_ 708 1000;
BA_ "GenMsgSendType" BO_ 676 0;
BA_ "GenMsgCycleTime" BO_ 676 1000;
BA_ "GenMsgSendType" BO_ 772 0;
BA_ "GenMsgCycleTime" BO_ 772 1000;
BA_ "GenMsgSendType" BO_ 790 0;
BA_ "GenMsgCycleTime" BO_ 790 1000;
BA_ "GenMsgSendType" BO_ 647 0;
BA_ "GenMsgCycleTime" BO_ 647 100;
BA_ "GenMsgSendType" BO_ 816 0;
BA_ "GenMsgCycleTime" BO_ 816 1000;
BA_ "GenMsgSendType" BO_ 815 0;
BA_ "GenMsgCycleTime" BO_ 815 1000;
BA_ "GenMsgSendType" BO_ 799 0;
BA_ "GenMsgCycleTime" BO_ 799 500;
BA_ "GenMsgSendType" BO_ 819 0;
BA_ "GenMsgCycleTime" BO_ 819 500;
BA_ "GenMsgSendType" BO_ 659 0;
BA_ "GenMsgCycleTime" BO_ 659 500;
BA_ "GenMsgSendType" BO_ 664 0;
BA_ "GenMsgCycleTime" BO_ 664 500;
BA_ "GenMsgSendType" BO_ 679 0;
BA_ "GenMsgCycleTime" BO_ 679 500;
BA_ "GenMsgSendType" BO_ 755 0;
BA_ "GenMsgCycleTime" BO_ 755 500;
BA_ "GenMsgSendType" BO_ 787 0;
BA_ "GenMsgCycleTime" BO_ 787 500;
BA_ "GenMsgSendType" BO_ 698 0;
BA_ "GenMsgCycleTime" BO_ 698 500;
BA_ "GenMsgSendType" BO_ 723 0;
BA_ "GenMsgCycleTime" BO_ 723 1000;
BA_ "GenMsgSendType" BO_ 824 0;
BA_ "GenMsgCycleTime" BO_ 824 1000;
BA_ "GenMsgSendType" BO_ 753 0;
BA_ "GenMsgCycleTime" BO_ 753 100;
BA_ "GenMsgSendType" BO_ 769 0;
BA_ "GenMsgCycleTime" BO_ 769 1000;
BA_ "GenMsgSendType" BO_ 705 0;
BA_ "GenMsgCycleTime" BO_ 705 17;
BA_ "GenMsgSendType" BO_ 721 0;
BA_ "GenMsgCycleTime" BO_ 721 100;
BA_ "GenMsgSendType" BO_ 801 0;
BA_ "GenMsgCycleTime" BO_ 801 1000;
BA_ "GenMsgSendType" BO_ 737 0;
BA_ "GenMsgCycleTime" BO_ 737 20;
BA_ "GenMsgSendType" BO_ 770 0;
BA_ "GenMsgCycleTime" BO_ 770 1000;
BA_ "GenMsgSendType" BO_ 778 0;
BA_ "GenMsgCycleTime" BO_ 778 50;
BA_ "GenMsgSendType" BO_ 774 0;
BA_ "GenMsgCycleTime" BO_ 774 1000;
BA_ "GenMsgSendType" BO_ 691 0;
BA_ "GenMsgCycleTime" BO_ 691 90;
BA_ "GenMsgSendType" BO_ 794 0;
BA_ "GenMsgCycleTime" BO_ 794 50;
BA_ "GenMsgSendType" BO_ 825 0;
BA_ "GenMsgCycleTime" BO_ 825 100;
BA_ "GenMsgSendType" BO_ 793 0;
BA_ "GenMsgCycleTime" BO_ 793 1000;
VAL_ 646 DI_aebState 0 "UNAVAILABLE" 1 "STANDBY" 2 "ENABLED" 3 "STANDSTILL" 4 "FAULT" 7 "SNA" ;
VAL_ 646 DI_autoparkState 0 "UNAVAILABLE" 1 "STANDBY" 2 "STARTED" 3 "ACTIVE" 4 "COMPLETE" 5 "PAUSED" 6 "ABORTED" 7 "RESUMED" 8 "UNPARK_COMPLETE" 9 "SELFPARK_STARTED" 15 "SNA" ;
VAL_ 646 DI_autopilotRequest 0 "IDLE" 1 "ACTIVATE" ;
VAL_ 646 DI_cruiseSetSpeedUnits 0 "MPH" 1 "KPH" ;
VAL_ 646 DI_cruiseState 0 "UNAVAILABLE" 1 "STANDBY" 2 "ENABLED" 3 "STANDSTILL" 4 "OVERRIDE" 5 "FAULT" 6 "PRE_FAULT" 7 "PRE_CANCEL" ;
VAL_ 646 DI_parkBrakeState 0 "UNAVAILABLE" 1 "RELEASED" 2 "REQUESTED" 3 "APPLIED" 4 "FAULTED" 5 "PANIC_EPB" 6 "PANIC_SKID" 7 "RELEASING" 15 "SNA" ;
VAL_ 646 DI_pmmStatus 0 "INACTIVE" 1 "ACTIVE" 2 "LOGGING_ACTIVE" 3 "SNA" ;
VAL_ 646 DI_rollPreventionState 0 "UNAVAILABLE" 1 "STANDBY" 2 "READY" 3 "BUILD" 4 "HOLD" 5 "PARK" 6 "FAULT" 7 "INIT" ;
VAL_ 646 DI_vehicleHoldState 0 "UNAVAILABLE" 1 "STANDBY" 2 "BLEND_IN" 3 "STANDSTILL" 4 "BLEND_OUT" 5 "PARK" 6 "FAULT" 7 "INIT" ;
VAL_ 648 EPBL_csmFaultReason 0 "NONE" 1 "EPBM_DISABLED" 2 "EPBM_FAULTED" 3 "STATE_MISMATCH" 4 "TIMEOUT_CALIBRATE" 5 "APPLY_BLOCKED" 6 "RELEASE_BLOCKED" 7 "TIMEOUT_APPLY_COMPLETE" 8 "TIMEOUT_APPLY_INRUSH" 9 "TIMEOUT_WAIT_FOR_CLAMP" 10 "TIMEOUT_RELEASE_INRUSH" 11 "TIMEOUT_RELEASE_WAIT_FOR_ENDSTOP" 12 "TIMEOUT_RELEASE_COMPLETE" 13 "TIMEOUT_EPBM_CUTOFF" 14 "TIMEOUT_NO_RAMP" 15 "TIMEOUT_EPBM_START" 16 "MOTOR_IDLE_FAULT" 17 "MOTOR_ACTIVE_FAULT" 18 "MOTOR_NOT_READY" 19 "EPBM_MIA" 20 "NVM_MISMATCH" 21 "REMOTE_MIA" ;
VAL_ 648 EPBL_epbmCDPQualified 0 "IDLE" 1 "VALID" 2 "INVALID" ;
VAL_ 648 EPBL_esmCaliperRequest 0 "INVALID" 1 "NONE" 2 "APPLY" 3 "RELEASE" 4 "ENDSTOP" ;
VAL_ 648 EPBL_esmOperationTrigger 0 "PBUTTON_PRESSED_STOPPED" 1 "PBUTTON_PRESSED_OKTOPARK" 2 "PBUTTON_PRESSED_FAST" 3 "PBUTTON_PRESSED_UNKNOWN" 4 "PBUTTON_RELEASED" 5 "ACTIVE_PARK_REQUEST" 6 "DI_UNPARK" 7 "TOUCHSCREEN" 8 "WINCHMODE_EXIT" 9 "WINCHMODE_ENTER" 10 "WINCHMODE_UNAVAILABLE" 11 "SERVICE" 12 "DIAG_CLOSE" 13 "DIAG_OPEN" 14 "DIAG_EXIT" 15 "USER_CONFIRMED" 16 "USER_CANCEL" 17 "SPEED_STOPPED" 18 "SPEED_OKAYTOPARK" 19 "SPEED_FAST" 20 "TIMEOUT" 21 "SAVESTATE_ON_BOOT" 22 "REAPPLY" 23 "SUMMON_COMPLETE" 24 "FAULT" 25 "SUMMON_FAULT" 26 "DISQUALIFIED" 27 "EPBM_DISQUALIFIED" 28 "ACCELERATION" 29 "SYSTEM_APPLY" 30 "DRIVER_IS_LEAVING" ;
VAL_ 648 EPBL_internalCDPRequest 0 "NOT_REQUESTED" 1 "REQUESTED" ;
VAL_ 648 EPBL_summonFaultReason 0 "NONE" 1 "DI_MIA" 2 "DAS_MIA" 3 "ESP_MIA" 4 "EPBM_MIA" 5 "DI_FAULT" 6 "DI_APC_FAULT" 7 "DAS_FAULT" 8 "ESP_FAULT" 9 "VEH_CAN_FAULT" 10 "EAC_NOT_ALLOWED" 11 "EPBM_REQUEST" 12 "SPEED" 13 "EXTERNAL" 14 "PARK_MIA" 15 "PM_MIA" 16 "PM_REQUEST" 17 "OOC" 18 "MISMATCH" 19 "EPB_FAULT" 20 "DI_STATE_INVALID" 21 "PASSIVE_REQUEST" 22 "EPBREMOTE_MIA" 23 "REMOTE_SUMMON_FAULTED" 24 "LOCAL_UNIT_FAULTED" 25 "REMOTE_UNIT_FAULTED" 26 "START_IN_UNAVAILABLE" 27 "INVALID_REMOTE_STATE" 28 "REMOTE_DID_NOT_START" ;
VAL_ 648 EPBL_summonState 0 "INIT" 1 "IDLE" 2 "ARMED" 3 "ACTIVE" 4 "COMPLETE" 5 "FAULT" 6 "UNAVAILABLE" ;
VAL_ 648 EPBL_unitFaultStatus 0 "NOMINAL" 1 "RETRY" 2 "FAULT" 3 "FAULT_IDLE" ;
VAL_ 648 EPBL_unitStatus 0 "UNKNOWN" 1 "OPEN" 2 "DYNAMIC" 3 "PARK" 4 "START" 5 "SERVICE" 6 "WINCHMODE" 7 "WINCHMODE_RELEASING" 8 "PARKING" 9 "DYNAMIC_APPLYING" 10 "RELEASING" 11 "SERVICE_RELEASING" 12 "PARK_PENDING" 13 "WINCHMODE_PENDING" 14 "SUMMON" 15 "SUMMON_RELEASING" 16 "SUMMON_PARKING" 17 "EXTERNAL_DYNAMIC" 18 "RELEASING_FOR_EXTERNAL_PARK" 19 "EXTERNAL_PARKING" 20 "DYNAMIC_PARKING" 21 "COUNT" ;
VAL_ 658 BattBeginningOfLifeEnergy292 1023 "SNA" ;
VAL_ 659 UI_accOvertakeEnable 0 "ACC_OVERTAKE_OFF" 1 "ACC_OVERTAKE_ON" 3 "SNA" ;
VAL_ 659 UI_aebEnable 0 "AEB_OFF" 1 "AEB_ON" 3 "SNA" ;
VAL_ 659 UI_aesEnable 0 "AES_OFF" 1 "AES_ON" 3 "SNA" ;
VAL_ 659 UI_ahlbEnable 0 "AHLB_OFF" 1 "AHLB_ON" 3 "SNA" ;
VAL_ 659 UI_autoLaneChangeEnable 0 "OFF" 1 "ON" 3 "SNA" ;
VAL_ 659 UI_autoParkRequest 0 "NONE" 1 "PARK_LEFT_PARALLEL" 2 "PARK_LEFT_CROSS" 3 "PARK_RIGHT_PARALLEL" 4 "PARK_RIGHT_CROSS" 5 "PARALLEL_PULL_OUT_TO_LEFT" 6 "PARALLEL_PULL_OUT_TO_RIGHT" 7 "ABORT" 8 "COMPLETE" 9 "SEARCH" 10 "PAUSE" 11 "RESUME" 15 "SNA" ;
VAL_ 659 UI_bsdEnable 0 "BSD_OFF" 1 "BSD_ON" 3 "SNA" ;
VAL_ 659 UI_distanceUnits 0 "KM" 1 "MILES" ;
VAL_ 659 UI_fcwEnable 0 "FCW_OFF" 1 "FCW_ON" 3 "SNA" ;
VAL_ 659 UI_fcwSensitivity 0 "AEB_SENSITIVITY_EARLY" 1 "AEB_SENSITIVITY_AVERAGE" 2 "AEB_SENSITIVITY_LATE" 3 "SNA" ;
VAL_ 659 UI_latControlEnable 0 "OFF" 1 "ON" 2 "UNAVAILABLE" 3 "SNA" ;
VAL_ 659 UI_ldwEnable 0 "NO_HAPTIC" 1 "LDW_TRIGGERS_HAPTIC" 3 "SNA" ;
VAL_ 659 UI_parkBrakeRequest 0 "IDLE" 1 "PRESSED" 3 "SNA" ;
VAL_ 659 UI_pedalSafetyEnable 0 "PEDAL_SAFETY_OFF" 1 "PEDAL_SAFETY_ON" 3 "SNA" ;
VAL_ 659 UI_redLightStopSignEnable 0 "RLSSW_OFF" 1 "RLSSW_ON" 3 "SNA" ;
VAL_ 659 UI_selfParkTune 15 "SNA" ;
VAL_ 659 UI_steeringTuneRequest 0 "COMFORT" 1 "STANDARD" 2 "SPORT" ;
VAL_ 659 UI_suspensionLevelRequest 0 "NO_CHANGE_SNA" 1 "REQUEST_LOW_LEVEL" 2 "REQUEST_NORMAL_LEVEL" 3 "REQUEST_HIGH_LEVEL" 4 "REQUEST_VERY_HIGH_LEVEL" 5 "TOGGLE_JACK_MODE" 6 "SWITCH_DEFECT" 7 "REQUEST_VERY_LOW_LEVEL" ;
VAL_ 659 UI_tractionControlMode 0 "NORMAL_SELECTED" 1 "SLIP_START_SELECTED" 2 "DEV_MODE_1_SELECTED" 3 "DEV_MODE_2_SELECTED" 4 "ROLLS_MODE_SELECTED" 5 "DYNO_MODE_SELECTED" ;
VAL_ 659 UI_trailerMode 0 "OFF" 1 "ON" ;
VAL_ 659 UI_winchModeRequest 0 "IDLE" 1 "ENTER" 2 "EXIT" ;
VAL_ 659 UI_zeroSpeedConfirmed 0 "CANCELED" 1 "CONFIRMED" 2 "UNUSED" 3 "SNA" ;
VAL_ 676 PCS_ambientTemp 1023 "TEMPERATURE_SNA" ;
VAL_ 676 PCS_chgPhATemp 1023 "TEMPERATURE_SNA" ;
VAL_ 676 PCS_chgPhBTemp 1023 "TEMPERATURE_SNA" ;
VAL_ 676 PCS_chgPhCTemp 1023 "TEMPERATURE_SNA" ;
VAL_ 676 PCS_dcdcTemp 1023 "TEMPERATURE_SNA" ;
VAL_ 680 CMPD_state 3 "CMPD_STATE_FAULT" 4 "CMPD_STATE_IDLE" 0 "CMPD_STATE_INIT" 1 "CMPD_STATE_RUNNING" 15 "CMPD_STATE_SNA" 2 "CMPD_STATE_STANDBY" ;
VAL_ 680 CMPD_state 3 "CMPD_STATE_FAULT" 4 "CMPD_STATE_IDLE" 0 "CMPD_STATE_INIT" 1 "CMPD_STATE_RUNNING" 15 "CMPD_STATE_SNA" 2 "CMPD_STATE_STANDBY" ;
VAL_ 680 CMPD_wasteHeatState 1 "CMPD_WASTE_HEAT_STATE_ACTIVE" 2 "CMPD_WASTE_HEAT_STATE_NOT_AVAILABLE" 0 "CMPD_WASTE_HEAT_STATE_OFF" 3 "CMPD_WASTE_HEAT_STATE_UNUSED" ;
VAL_ 681 EPBL_brakeDiscWipeRequest 0 "NONE" 1 "LIGHT" 2 "STRONG" 3 "SNA" ;
VAL_ 681 EPBL_cdpRequest 0 "NOT_REQUESTED" 1 "REQUESTED" ;
VAL_ 681 EPBL_systemStatus 0 "UNKNOWN" 1 "RELEASED" 2 "PARKED" 3 "DYNAMIC" 4 "PARKING" 5 "RELEASING" 6 "FAULT" 7 "FAULT_SECURE" 8 "MISMATCH" ;
VAL_ 691 VCRIGHT_logging1HzIndex 0 "HVAC_TEMP_SENSORS_AND_ESTIMATES_1" 1 "HVAC_TEMP_SENSORS_AND_ESTIMATES_2" 2 "HVAC_HUMIDITY_HEATER" 3 "HVAC_STATUS_AIRFLOW" 4 "HVAC_COMFORT_SOLAR" 5 "HEATER_AND_DUCT_TARGETS" 6 "HVAC_ACTUATOR_VOLTAGES" 7 "HVAC_ACTUATOR_ENDSTOP" 8 "HVAC_ACTUATOR_ZEROSTOP" 9 "HVAC_MISCELLANEOUS_1" 10 "HVAC_MISCELLANEOUS_2" 11 "END" ;
VAL_ 691 VCRIGHT_cabinTempBreathLevel 255 "SNA" ;
VAL_ 691 VCRIGHT_cabinTempGlassRoof 255 "SNA" ;
VAL_ 691 VCRIGHT_cabinTempInterior 240 "SNA" ;
VAL_ 691 VCRIGHT_cabinTempInteriorL2 240 "SNA" ;
VAL_ 691 VCRIGHT_cabinTempInteriorL3 240 "SNA" ;
VAL_ 691 VCRIGHT_cabinTempInteriorSunny 240 "SNA" ;
VAL_ 691 VCRIGHT_cabinTempInteriorSunnyL2 240 "SNA" ;
VAL_ 691 VCRIGHT_cabinTempInteriorSunnyL3 240 "SNA" ;
VAL_ 691 VCRIGHT_cabinTempSideGlassLeft 255 "SNA" ;
VAL_ 691 VCRIGHT_cabinTempSideGlassRight 255 "SNA" ;
VAL_ 691 VCRIGHT_cabinTempTopPadAir 240 "SNA" ;
VAL_ 691 VCRIGHT_cabinTempWindshield 255 "SNA" ;
VAL_ 691 VCRIGHT_convectionDeliveredLeft 255 "SNA" ;
VAL_ 691 VCRIGHT_convectionDeliveredRight 255 "SNA" ;
VAL_ 691 VCRIGHT_convectionTargetLeft 255 "SNA" ;
VAL_ 691 VCRIGHT_convectionTargetRight 255 "SNA" ;
VAL_ 691 VCRIGHT_hvacAirFlowModeRow1 0 "NONE" 1 "FLOOR" 2 "PANEL" 3 "PANEL_FLOOR" 4 "DEFROST" 5 "DEFROST_FLOOR" 6 "DEFROST_PANEL" 7 "DEFROST_PANEL_FLOOR" ;
VAL_ 691 VCRIGHT_hvacAirFlowModeRow2 0 "NONE" 1 "FLOOR" 2 "PANEL" 3 "PANEL_FLOOR" 4 "DEFROST" 5 "DEFROST_FLOOR" 6 "DEFROST_PANEL" 7 "DEFROST_PANEL_FLOOR" ;
VAL_ 691 VCRIGHT_hvacAirflowReason 0 "HVAC_OFF" 1 "MANUAL_FAN_SPEED" 2 "UI_SHORTCUT" 3 "CABIN_TEMPERATURE_CONTROL" 4 "MINIMUM_AUTO_AIRFLOW" 5 "STRATIFICATION_GLASS_ROOF" 6 "STRATIFICATION_INTERIOR_SURFACES" 7 "OCCUPANT_CONVECTION_REQUIREMENT" 8 "COLD_DUCT_LOCKOUT" 9 "CABIN_PURGE" 10 "CABIN_OVERHEAT_PROTECT" 11 "SCREEN_PROTECTION" 12 "EVAP_DRYING" 13 "NONE" ;
VAL_ 691 VCRIGHT_hvacAutoTransitionReason 0 "NONE" 1 "HUMIDITY_HIGH" 2 "HUMIDITY_MODERATE" 3 "HUMIDITY_LOW" 4 "TEMP_TARGET_BELOW_THRESHOLD" 5 "TEMP_TARGET_ABOVE_THRESHOLD" 6 "EXCESS_OCCUPANT_CONVECTION" 7 "OCCUPANT_CONVECTION_REQUIREMENT" 8 "TEMP_TARGET_LOW" 9 "DUCTS_COLD" 10 "BI_LEVEL_LANDING" 11 "DEFOG_OVERRIDE" 12 "SET_TEMP_LO" 13 "SET_TEMP_HI" 14 "CABIN_PURGE" 15 "EVAP_DRYING" 16 "HVAC_OFF" 17 "END" ;
VAL_ 691 VCRIGHT_solarLoadLeftOccupant 255 "SNA" ;
VAL_ 691 VCRIGHT_solarLoadOnVehFiltered 255 "SNA" ;
VAL_ 691 VCRIGHT_solarLoadOnVehicle 255 "SNA" ;
VAL_ 691 VCRIGHT_solarLoadRightOccupant 255 "SNA" ;
VAL_ 691 VCRIGHT_tempDuctModeledLeft 511 "SNA" ;
VAL_ 691 VCRIGHT_tempDuctModeledRight 511 "SNA" ;
VAL_ 691 VCRIGHT_tempHtrSurfaceModeledL 511 "SNA" ;
VAL_ 691 VCRIGHT_tempHtrSurfaceModeledR 511 "SNA" ;
VAL_ 691 VCRIGHT_tempIncarCabinDeep 255 "SNA" ;
VAL_ 691 VCRIGHT_tempIncarCabinMid 250 "SNA" ;
VAL_ 691 VCRIGHT_tempIncarCabinProbe 255 "SNA" ;
VAL_ 694 DI_btcStateUI 0 "OFF" 1 "ON" ;
VAL_ 694 DI_ptcStateUI 0 "FAULTED" 1 "BACKUP" 2 "ON" 3 "SNA" ;
VAL_ 694 DI_tcTelltaleFlash 0 "OFF" 1 "ON" ;
VAL_ 694 DI_tcTelltaleOn 0 "OFF" 1 "ON" ;
VAL_ 694 DI_tractionControlModeUI 0 "NORMAL" 1 "SLIP_START" 2 "DEV_MODE_1" 3 "DEV_MODE_2" 4 "ROLLS_MODE" 5 "DYNO_MODE" ;
VAL_ 694 DI_vdcTelltaleFlash 0 "OFF" 1 "ON" ;
VAL_ 694 DI_vdcTelltaleOn 0 "OFF" 1 "ON" ;
VAL_ 697 DAS_accState 0 "ACC_CANCEL_GENERIC" 1 "ACC_CANCEL_CAMERA_BLIND" 2 "ACC_CANCEL_RADAR_BLIND" 3 "ACC_HOLD" 4 "ACC_ON" 5 "APC_BACKWARD" 6 "APC_FORWARD" 7 "APC_COMPLETE" 8 "APC_ABORT" 9 "APC_PAUSE" 10 "APC_UNPARK_COMPLETE" 11 "APC_SELFPARK_START" 12 "ACC_CANCEL_PATH_NOT_CLEAR" 13 "ACC_CANCEL_GENERIC_SILENT" 14 "ACC_CANCEL_OUT_OF_CALIBRATION" 15 "FAULT_SNA" ;
VAL_ 697 DAS_accelMax 511 "SNA" ;
VAL_ 697 DAS_accelMin 511 "SNA" ;
VAL_ 697 DAS_aebEvent 0 "NOT_ACTIVE" 1 "ACTIVE" 2 "FAULT" 3 "SNA" ;
VAL_ 697 DAS_jerkMax 255 "SNA" ;
VAL_ 697 DAS_jerkMin 511 "SNA" ;
VAL_ 697 DAS_setSpeed 4095 "SNA" ;
VAL_ 698 UI_radarTargetDx 255 "NO_OBJECT" ;
VAL_ 698 UI_radarTargetDxEnd 255 "NO_OBJECT" ;
VAL_ 705 VCFRONT_logging10HzIndex 0 "COOLANT_PUMPS" 1 "THERMAL_FAN" 2 "FIVE_WAY_VALVE" 3 "REFRIGERANT_LV8907" 4 "COMPRESSOR" 5 "EXV_EVAP_SOLENOID_AIRFLOW" 6 "END" ;
VAL_ 705 VCFRONT_activeLouverMotorState 0 "UNPOWERED" 1 "INIT_I2C" 2 "INIT_EEPROM" 3 "I2C_ERROR" 4 "READY" 5 "BRAKE" 6 "STALL" 7 "FAULT_MOTOR_DISCONNECTED" 8 "DRIVER_FAULT" ;
VAL_ 705 VCFRONT_activeLouverState 0 "UNCALIBRATED" 1 "CALIB_CLOSE" 2 "CALIB_OPEN" 3 "READY" 4 "FAULTED" ;
VAL_ 705 VCFRONT_coolantTempBasedMode 0 "SERIES" 1 "PARALLEL" ;
VAL_ 705 VCFRONT_exvMotorState 0 "UNPOWERED" 1 "HARD_RESET_SETUP" 2 "HARD_RESET" 3 "INIT_SPI" 4 "SPI_ERROR" 5 "ENABLE_MOTOR" 6 "READY" 7 "STALL" 8 "FAULT_SHORT_COIL" 9 "FAULT_OPEN_COIL" 10 "DRIVER_FAULT" 11 "SPI_COMMS_DOWN" ;
VAL_ 705 VCFRONT_pumpBatteryRPMTarget 1023 "SNA" ;
VAL_ 705 VCFRONT_pumpPowertrainRPMTarget 1023 "SNA" ;
VAL_ 705 VCFRONT_radiatorFanRPMTarget 1023 "SNA" ;
VAL_ 705 VCFRONT_tempDischargeSimulated 2047 "SNA" ;
VAL_ 708 PCS_logMessageSelect 0 "PHA_1" 1 "PHB_1" 2 "PHC_1" 3 "CHG_1" 4 "CHG_2" 5 "CHG_3" 6 "DCDC_1" 7 "DCDC_2" 8 "DCDC_3" 9 "SYSTEM_1" 10 "PHA_2" 11 "PHB_2" 12 "PHC_2" 13 "CHG_4" 14 "DLOG_1" 15 "DLOG_2" 16 "DLOG_3" 17 "DLOG_4" 18 "DCDC_4" 19 "DCDC_5" 20 "CHG_NO_FLOW" 21 "CHG_LINE_OFFSET" 22 "DCDC_STATISTICS" 23 "CHG_STATISTICS" 24 "NUM_MSGS" ;
VAL_ 708 PCS_chgInputFrequencyL1N 0 "FREQUENCY_UNKNOWN" ;
VAL_ 708 PCS_chgInputFrequencyL2N 0 "FREQUENCY_UNKNOWN" ;
VAL_ 708 PCS_chgInputFrequencyL3N 0 "FREQUENCY_UNKNOWN" ;
VAL_ 708 PCS_chgInternalPhaseConfig 0 "SNA" 1 "SINGLE_PHASE" 2 "THREE_PHASE" 3 "THREE_PHASE_DELTA" 4 "SINGLE_PHASE_IEC_GB" 5 "MFG_TEST_CONFIG_1" 6 "MFG_TEST_CONFIG_2" 7 "TOTAL_NUM" ;
VAL_ 708 PCS_chgPhAState 0 "INIT" 1 "IDLE" 2 "PRECHARGE" 3 "ENABLE" 4 "FAULT" 5 "CLEAR_FAULTS" 6 "SHUTTING_DOWN" ;
VAL_ 708 PCS_chgPhBState 0 "INIT" 1 "IDLE" 2 "PRECHARGE" 3 "ENABLE" 4 "FAULT" 5 "CLEAR_FAULTS" 6 "SHUTTING_DOWN" ;
VAL_ 708 PCS_chgPhCState 0 "INIT" 1 "IDLE" 2 "PRECHARGE" 3 "ENABLE" 4 "FAULT" 5 "CLEAR_FAULTS" 6 "SHUTTING_DOWN" ;
VAL_ 708 PCS_chgPhALastShutdownReason 0 "REASON_NONE" 1 "SW_ENABLE" 2 "HW_ENABLE" 3 "SW_FAULT" 4 "HW_FAULT" 5 "PLL_NOT_LOCKED" 6 "INPUT_UV" 7 "INPUT_OV" 8 "OUTPUT_UV" 9 "OUTPUT_OV" 10 "PRECHARGE_TIMEOUT" 11 "INT_BUS_UV" 12 "CONTROL_REGULATION_FAULT" 13 "OVER_TEMPERATURE" 14 "TEMP_IRRATIONAL" 15 "SENSOR_IRRATIONAL" 16 "FREQ_OUT_OF_RANGE" 17 "LINE_TRANSIENT_FAULT" ;
VAL_ 708 PCS_chgPhBLastShutdownReason 0 "REASON_NONE" 1 "SW_ENABLE" 2 "HW_ENABLE" 3 "SW_FAULT" 4 "HW_FAULT" 5 "PLL_NOT_LOCKED" 6 "INPUT_UV" 7 "INPUT_OV" 8 "OUTPUT_UV" 9 "OUTPUT_OV" 10 "PRECHARGE_TIMEOUT" 11 "INT_BUS_UV" 12 "CONTROL_REGULATION_FAULT" 13 "OVER_TEMPERATURE" 14 "TEMP_IRRATIONAL" 15 "SENSOR_IRRATIONAL" 16 "FREQ_OUT_OF_RANGE" 17 "LINE_TRANSIENT_FAULT" ;
VAL_ 708 PCS_chgPhCLastShutdownReason 0 "REASON_NONE" 1 "SW_ENABLE" 2 "HW_ENABLE" 3 "SW_FAULT" 4 "HW_FAULT" 5 "PLL_NOT_LOCKED" 6 "INPUT_UV" 7 "INPUT_OV" 8 "OUTPUT_UV" 9 "OUTPUT_OV" 10 "PRECHARGE_TIMEOUT" 11 "INT_BUS_UV" 12 "CONTROL_REGULATION_FAULT" 13 "OVER_TEMPERATURE" 14 "TEMP_IRRATIONAL" 15 "SENSOR_IRRATIONAL" 16 "FREQ_OUT_OF_RANGE" 17 "LINE_TRANSIENT_FAULT" ;
VAL_ 708 PCS_dcdcTankVoltage 1024 "TANK_VOLTAGE_SNA" ;
VAL_ 708 PCS_cpu2BootState 0 "BOOTROM" 1 "BOOTLOADER" 2 "APPLICATION" 3 "ERROR" ;
VAL_ 708 PCS_acChargeSelfTestState 0 "IDLE" 1 "STARTED" ;
VAL_ 708 PCS_chgInputFreqWobblePHAPeak 0 "FREQUENCY_UNKNOWN" ;
VAL_ 708 PCS_chgInputFreqWobblePHBPeak 0 "FREQUENCY_UNKNOWN" ;
VAL_ 708 PCS_chgInputFreqWobblePHCPeak 0 "FREQUENCY_UNKNOWN" ;
VAL_ 708 PCS_dLogPhAChannel1Content 0 "INPUT_VOLTAGE" 1 "INPUT_CURRENT" 2 "OUTPUT_CURRENT" 3 "INT_BUS_VOLTAGE" ;
VAL_ 708 PCS_dLogPhBChannel1Content 0 "INPUT_VOLTAGE" 1 "INPUT_CURRENT" 2 "OUTPUT_CURRENT" 3 "INT_BUS_VOLTAGE" ;
VAL_ 708 PCS_dLogPhCChannel1Content 0 "INPUT_VOLTAGE" 1 "INPUT_CURRENT" 2 "OUTPUT_CURRENT" 3 "INT_BUS_VOLTAGE" ;
VAL_ 708 PCS_dLogPhAChannel2Content 0 "INPUT_VOLTAGE" 1 "INPUT_CURRENT" 2 "OUTPUT_CURRENT" 3 "INT_BUS_VOLTAGE" ;
VAL_ 708 PCS_dLogPhBChannel2Content 0 "INPUT_VOLTAGE" 1 "INPUT_CURRENT" 2 "OUTPUT_CURRENT" 3 "INT_BUS_VOLTAGE" ;
VAL_ 708 PCS_dLogPhCChannel2Content 0 "INPUT_VOLTAGE" 1 "INPUT_CURRENT" 2 "OUTPUT_CURRENT" 3 "INT_BUS_VOLTAGE" ;
VAL_ 708 PCS_dLogPhAChannel3Content 0 "INPUT_VOLTAGE" 1 "INPUT_CURRENT" 2 "OUTPUT_CURRENT" 3 "INT_BUS_VOLTAGE" ;
VAL_ 708 PCS_dLogPhBChannel3Content 0 "INPUT_VOLTAGE" 1 "INPUT_CURRENT" 2 "OUTPUT_CURRENT" 3 "INT_BUS_VOLTAGE" ;
VAL_ 708 PCS_dLogPhCChannel3Content 0 "INPUT_VOLTAGE" 1 "INPUT_CURRENT" 2 "OUTPUT_CURRENT" 3 "INT_BUS_VOLTAGE" ;
VAL_ 708 PCS_dLogPhAChannel4Content 0 "INPUT_VOLTAGE" 1 "INPUT_CURRENT" 2 "OUTPUT_CURRENT" 3 "INT_BUS_VOLTAGE" ;
VAL_ 708 PCS_dLogPhBChannel4Content 0 "INPUT_VOLTAGE" 1 "INPUT_CURRENT" 2 "OUTPUT_CURRENT" 3 "INT_BUS_VOLTAGE" ;
VAL_ 708 PCS_dLogPhCChannel4Content 0 "INPUT_VOLTAGE" 1 "INPUT_CURRENT" 2 "OUTPUT_CURRENT" 3 "INT_BUS_VOLTAGE" ;
VAL_ 723 UI_isSunUp 0 "DOWN" 1 "UP" 3 "SNA" ;
VAL_ 723 UI_solarAzimuthAngle 32768 "SNA" ;
VAL_ 723 UI_solarAzimuthAngleCarRef 255 "SNA" ;
VAL_ 723 UI_solarElevationAngle 127 "SNA" ;
VAL_ 737 VCFRONT_statusIndex 0 "BODY_CONTROLS" 1 "VEHICLE_AND_RAILS" 2 "HOMELINK" 3 "REFRIGERANT_SYSTEM" 4 "LV_BATTERY_DEBUG" 5 "INVALID" ;
VAL_ 737 VCFRONT_AS8510Voltage 4095 "SNA" ;
VAL_ 737 VCFRONT_airCompressorStatus 0 "OFF" 1 "ON" 2 "TURNING_OFF" 3 "TURNING_ON" 4 "FAULT" 5 "RETRY_AVAILABLE" 7 "SNA" ;
VAL_ 737 VCFRONT_batterySMState 0 "INIT" 1 "CHARGE" 2 "DISCHARGE" 3 "STANDBY" 4 "RESISTANCE_ESTIMATION" 5 "OTA_STANDBY" 6 "DISCONNECTED_BATTERY_TEST" 7 "FAULT" ;
VAL_ 737 VCFRONT_coolantFillRoutineStatus 3 "FAULTED" 1 "MOVING_TO_FILL_POSITION" 0 "NOT_READY" 2 "READY_TO_FILL" ;
VAL_ 737 VCFRONT_crashDetectedType 0 "NONE" 1 "MINOR" 2 "SEVERE" ;
VAL_ 737 VCFRONT_crashState 0 "IDLE" 1 "MINOR" 2 "SEVERE" ;
VAL_ 737 VCFRONT_frunkLatchStatus 0 "SNA" 1 "OPENED" 2 "CLOSED" 3 "CLOSING" 4 "OPENING" 5 "AJAR" 6 "TIMEOUT" 7 "DEFAULT" 8 "FAULT" ;
VAL_ 737 VCFRONT_homelinkCommStatus 0 "SNA" 1 "OFF" 2 "ON" 3 "FAULT" ;
VAL_ 737 VCFRONT_hvacPerfTestCommand 2 "BLOW" 1 "INIT" 0 "NOT_STARTED" 3 "STOP" ;
VAL_ 737 VCFRONT_iBoosterStateDBG 0 "OFF" 1 "ON" 2 "GOING_DOWN" 3 "WRITING_DATA_SHUTDOWN" 4 "FORCE_OFF" ;
VAL_ 737 VCFRONT_pressureRefrigDischarge 255 "SNA" ;
VAL_ 737 VCFRONT_pressureRefrigSuction 127 "SNA" ;
VAL_ 737 VCFRONT_radarHeaterState 4 "HEATER_STATE_FAULT" 2 "HEATER_STATE_OFF" 3 "HEATER_STATE_OFF_UNAVAILABLE" 1 "HEATER_STATE_ON" 0 "HEATER_STATE_SNA" ;
VAL_ 737 VCFRONT_refrigFillRoutineStatus 3 "FAULTED" 1 "MOVING_TO_FILL_POSITION" 0 "NOT_READY" 2 "READY_TO_FILL" ;
VAL_ 737 VCFRONT_vbatMonitorVoltage 4095 "SNA" ;
VAL_ 737 VCFRONT_vehicleStatusDBG 0 "INIT" 1 "LOW_POWER_STANDBY" 2 "SILENT_WAKE" 3 "BATTERY_POST_WAKE" 4 "SYSTEM_CHECKS" 5 "SLEEP_SHUTDOWN" 6 "SLEEP_STANDBY" 7 "LV_SHUTDOWN" 8 "LV_AWAKE" 9 "HV_UP_STANDBY" 10 "ACCESSORY" 11 "ACCESSORY_PLUS" 12 "CONDITIONING" 13 "DRIVE" 14 "CRASH" 15 "OTA" 16 "TURN_ON_RAILS" 17 "RESET" ;
VAL_ 737 VCFRONT_voltageProfile 3 "VOLTAGE_PROFILE_ALWAYS_CLOSED_CONTACTORS" 0 "VOLTAGE_PROFILE_CHARGE" 1 "VOLTAGE_PROFILE_FLOAT" 2 "VOLTAGE_PROFILE_REDUCED_FLOAT" ;
VAL_ 737 VCFRONT_wiperPosition 0 "SNA" 1 "SERVICE" 2 "DEPRESSED_PARK" 3 "DELAYED_REST" 4 "WIPING" ;
VAL_ 737 VCFRONT_wiperSpeed 0 "SNA" 1 "OFF" 2 "1" 3 "2" 4 "3" 5 "4" 6 "5" 7 "LOW" 8 "HIGH" ;
VAL_ 737 VCFRONT_wiperState 0 "SNA" 1 "SERVICE" 2 "FAULT" 3 "DELAYED_REST" 4 "PARK" 5 "WASH" 6 "MOMENTARY_WIPE" 7 "INTERMITTENT_HIGH" 8 "INTERMITTENT_LOW" 9 "CONT_FAST" 10 "CONT_SLOW" 11 "INT_AUTO_LOW" 12 "INT_AUTO_HIGH" ;
VAL_ 741 DIS_drivePowerMax 511 "SNA" ;
VAL_ 741 DIS_elecPower 1024 "DIS_elecPower_SNA" ;
VAL_ 744 EPBR_brakeDiscWipeRequest 0 "NONE" 1 "LIGHT" 2 "STRONG" 3 "SNA" ;
VAL_ 744 EPBR_cdpRequest 0 "NOT_REQUESTED" 1 "REQUESTED" ;
VAL_ 744 EPBR_systemStatus 0 "UNKNOWN" 1 "RELEASED" 2 "PARKED" 3 "DYNAMIC" 4 "PARKING" 5 "RELEASING" 6 "FAULT" 7 "FAULT_SECURE" 8 "MISMATCH" ;
VAL_ 753 VCFRONT_eFuseDebugStatusIndex 0 "VCRIGHT" 1 "VCLEFT" 2 "PCS" 3 "IBOOSTER" 4 "EPAS3P" 5 "EPAS3S" 6 "ESP_MOTOR" 7 "ESP_VALVE" 8 "AUTOPILOT_1" 9 "AUTOPILOT_2" 10 "SLEEP_BYPASS" 11 "UI" 12 "HEADLAMPS" 13 "VBAT_FUSED_HIGH_CURRENT" 14 "PUMPS" 15 "RAILS_A_B" 16 "MISC_RAILS" 17 "INVALID" ;
VAL_ 753 VCFRONT_rightControllerState 0 "OFF" 1 "ON" 2 "LOCKED_OUT" ;
VAL_ 753 VCFRONT_vcrightSelfTestResult 0 "NOT_RUN" 1 "PASSED" 2 "FAILED_EFUSE_OUTPUT_SHORT" 3 "FAILED_POWER_FET_STUCK_ON" 4 "FAILED_ENABLE_LOW_MALFUNCTION" 5 "FAILED_POWER_FET_CHANNEL_OPEN" 6 "FAILED_ENABLE_HIGH_MALFUNCTION" 7 "FAILED_TURN_OFF_PATH_TOO_SLOW" 8 "FAILED_NOT_LATCHED" 9 "SKIPPED" ;
VAL_ 753 VCFRONT_leftControllerState 0 "OFF" 1 "ON" 2 "LOCKED_OUT" ;
VAL_ 753 VCFRONT_vcleftSelfTestResult 0 "NOT_RUN" 1 "PASSED" 2 "FAILED_EFUSE_OUTPUT_SHORT" 3 "FAILED_POWER_FET_STUCK_ON" 4 "FAILED_ENABLE_LOW_MALFUNCTION" 5 "FAILED_POWER_FET_CHANNEL_OPEN" 6 "FAILED_ENABLE_HIGH_MALFUNCTION" 7 "FAILED_TURN_OFF_PATH_TOO_SLOW" 8 "FAILED_NOT_LATCHED" 9 "SKIPPED" ;
VAL_ 753 VCFRONT_PCSState 0 "OFF" 1 "ON" 2 "LOCKED_OUT" ;
VAL_ 753 VCFRONT_pcsSelfTestResult 0 "NOT_RUN" 1 "PASSED" 2 "FAILED_EFUSE_OUTPUT_SHORT" 3 "FAILED_POWER_FET_STUCK_ON" 4 "FAILED_ENABLE_LOW_MALFUNCTION" 5 "FAILED_POWER_FET_CHANNEL_OPEN" 6 "FAILED_ENABLE_HIGH_MALFUNCTION" 7 "FAILED_TURN_OFF_PATH_TOO_SLOW" 8 "FAILED_NOT_LATCHED" 9 "SKIPPED" ;
VAL_ 753 VCFRONT_iBoosterState 0 "OFF" 1 "ON" 2 "LOCKED_OUT" ;
VAL_ 753 VCFRONT_iBoosterSelfTestResult 0 "NOT_RUN" 1 "PASSED" 2 "FAILED_EFUSE_OUTPUT_SHORT" 3 "FAILED_POWER_FET_STUCK_ON" 4 "FAILED_ENABLE_LOW_MALFUNCTION" 5 "FAILED_POWER_FET_CHANNEL_OPEN" 6 "FAILED_ENABLE_HIGH_MALFUNCTION" 7 "FAILED_TURN_OFF_PATH_TOO_SLOW" 8 "FAILED_NOT_LATCHED" 9 "SKIPPED" ;
VAL_ 753 VCFRONT_EPAS3PState 0 "OFF" 1 "ON" 2 "LOCKED_OUT" ;
VAL_ 753 VCFRONT_EPAS3PSelfTestResult 0 "NOT_RUN" 1 "PASSED" 2 "FAILED_EFUSE_OUTPUT_SHORT" 3 "FAILED_POWER_FET_STUCK_ON" 4 "FAILED_ENABLE_LOW_MALFUNCTION" 5 "FAILED_POWER_FET_CHANNEL_OPEN" 6 "FAILED_ENABLE_HIGH_MALFUNCTION" 7 "FAILED_TURN_OFF_PATH_TOO_SLOW" 8 "FAILED_NOT_LATCHED" 9 "SKIPPED" ;
VAL_ 753 VCFRONT_EPAS3SState 0 "OFF" 1 "ON" 2 "LOCKED_OUT" ;
VAL_ 753 VCFRONT_EPAS3SSelfTestResult 0 "NOT_RUN" 1 "PASSED" 2 "FAILED_EFUSE_OUTPUT_SHORT" 3 "FAILED_POWER_FET_STUCK_ON" 4 "FAILED_ENABLE_LOW_MALFUNCTION" 5 "FAILED_POWER_FET_CHANNEL_OPEN" 6 "FAILED_ENABLE_HIGH_MALFUNCTION" 7 "FAILED_TURN_OFF_PATH_TOO_SLOW" 8 "FAILED_NOT_LATCHED" 9 "SKIPPED" ;
VAL_ 753 VCFRONT_ESPMotorState 0 "OFF" 1 "ON" 2 "LOCKED_OUT" ;
VAL_ 753 VCFRONT_ESPMotorSelfTestResult 0 "NOT_RUN" 1 "PASSED" 2 "FAILED_EFUSE_OUTPUT_SHORT" 3 "FAILED_POWER_FET_STUCK_ON" 4 "FAILED_ENABLE_LOW_MALFUNCTION" 5 "FAILED_POWER_FET_CHANNEL_OPEN" 6 "FAILED_ENABLE_HIGH_MALFUNCTION" 7 "FAILED_TURN_OFF_PATH_TOO_SLOW" 8 "FAILED_NOT_LATCHED" 9 "SKIPPED" ;
VAL_ 753 VCFRONT_ESPValveState 0 "OFF" 1 "ON" 2 "LOCKED_OUT" ;
VAL_ 753 VCFRONT_autopilot1State 0 "OFF" 1 "ON" 2 "LOCKED_OUT" ;
VAL_ 753 VCFRONT_autopilot2State 0 "OFF" 1 "ON" 2 "LOCKED_OUT" ;
VAL_ 753 VCFRONT_headlampLeftVoltage 255 "SNA" ;
VAL_ 753 VCFRONT_headlampRightVoltage 255 "SNA" ;
VAL_ 753 VCFRONT_headlampLeftTemperature 128 "SNA" ;
VAL_ 753 VCFRONT_headlampRightTemperature 128 "SNA" ;
VAL_ 753 VCFRONT_vbatFusedSelfTestResult 0 "NOT_RUN" 1 "PASSED" 2 "FAILED_EFUSE_OUTPUT_SHORT" 3 "FAILED_POWER_FET_STUCK_ON" 4 "FAILED_ENABLE_LOW_MALFUNCTION" 5 "FAILED_POWER_FET_CHANNEL_OPEN" 6 "FAILED_ENABLE_HIGH_MALFUNCTION" 7 "FAILED_TURN_OFF_PATH_TOO_SLOW" 8 "FAILED_NOT_LATCHED" 9 "SKIPPED" ;
VAL_ 754 BMS_nmKeepAwakeReason 0 "NONE_SNA" 1 "CTRS_CLOSED" 2 "CRITICAL_ALERT" 3 "FC_CTR_CLEANING" 4 "HVP_ACTIVE" 5 "BMS_ACTIVE" 6 "CP_ACTIVE" ;
VAL_ 754 BMS_nmWakeUpReason 0 "NONE" 1 "CAN_VEH" 2 "CAN_HVS" 3 "WANTTOCHARGE" 4 "CRITICALALERT" 5 "WANTTOWARM" ;
VAL_ 755 UI_hvacReqACDisable 0 "AUTO" 1 "OFF" 2 "ON" ;
VAL_ 755 UI_hvacReqAirDistributionMode 0 "AUTO" 1 "MANUAL_FLOOR" 2 "MANUAL_PANEL" 3 "MANUAL_PANEL_FLOOR" 4 "MANUAL_DEFROST" 5 "MANUAL_DEFROST_FLOOR" 6 "MANUAL_DEFROST_PANEL" 7 "MANUAL_DEFROST_PANEL_FLOOR" ;
VAL_ 755 UI_hvacReqBlowerSegment 0 "OFF" 1 "1" 2 "2" 3 "3" 4 "4" 5 "5" 6 "6" 7 "7" 8 "8" 9 "9" 10 "10" 11 "AUTO" ;
VAL_ 755 UI_hvacReqKeepClimateOn 2 "KEEP_CLIMATE_ON_REQ_DOG" 0 "KEEP_CLIMATE_ON_REQ_OFF" 1 "KEEP_CLIMATE_ON_REQ_ON" 3 "KEEP_CLIMATE_ON_REQ_PARTY" ;
VAL_ 755 UI_hvacReqManualDefogState 0 "NONE" 1 "DEFOG" 2 "DEFROST" ;
VAL_ 755 UI_hvacReqRecirc 0 "AUTO" 1 "RECIRC" 2 "FRESH" ;
VAL_ 755 UI_hvacReqSecondRowState 0 "AUTO" 1 "OFF" 2 "LOW" 3 "MED" 4 "HIGH" ;
VAL_ 755 UI_hvacReqTempSetpointLeft 0 "LO" 26 "HI" ;
VAL_ 755 UI_hvacReqTempSetpointRight 0 "LO" 26 "HI" ;
VAL_ 755 UI_hvacReqUserPowerState 0 "OFF" 1 "ON" 2 "PRECONDITION" 3 "OVERHEAT_PROTECT_FANONLY" 4 "OVERHEAT_PROTECT" ;
VAL_ 768 BMS_infoIndex 0 "DEPRECATED_0" 1 "DEPRECATED_1" 2 "DEPRECATED_2" 3 "DEPRECATED_3" 4 "DEPRECATED_4" 5 "DEPRECATED_5" 6 "DEPRECATED_6" 7 "DEPRECATED_7" 8 "DEPRECATED_8" 9 "DEPRECATED_9" 10 "BUILD_HWID_COMPONENTID" 11 "PCBAID_ASSYID_USAGEID" 13 "APP_CRC" 14 "BOOTLOADER_SVN" 15 "BOOTLOADER_CRC" 16 "SUBCOMPONENT" 17 "APP_GITHASH" 18 "BOOTLOADER_GITHASH" 19 "VERSION_DEPRECATED" 20 "UDS_PROTOCOL_BOOTCRC" 22 "VARIANTCRC" 25 "PACKAGE_PN_1_7" 26 "PACKAGE_PN_8_14" 27 "PACKAGE_PN_15_20" 29 "PACKAGE_SN_1_7" 30 "PACKAGE_SN_8_14" 31 "SUBCOMPONENT_GITHASH" 255 "END" ;
VAL_ 768 BMS_buildType 0 "UNKNOWN_BUILD" 1 "PLATFORM_BUILD" 2 "LOCAL_BUILD" 3 "TRACEABLE_CI_BUILD" 4 "MFG_BUILD" ;
VAL_ 769 VCFRONT_infoIndex 0 "DEPRECATED_0" 1 "DEPRECATED_1" 2 "DEPRECATED_2" 3 "DEPRECATED_3" 4 "DEPRECATED_4" 5 "DEPRECATED_5" 6 "DEPRECATED_6" 7 "DEPRECATED_7" 8 "DEPRECATED_8" 9 "DEPRECATED_9" 10 "BUILD_HWID_COMPONENTID" 11 "PCBAID_ASSYID_USAGEID" 13 "APP_CRC" 14 "BOOTLOADER_SVN" 15 "BOOTLOADER_CRC" 16 "SUBCOMPONENT1" 17 "APP_GITHASH" 18 "BOOTLOADER_GITHASH" 19 "VERSION_DEPRECATED" 20 "UDS_PROTOCOL_BOOTCRC" 23 "SUBCOMPONENT2" 24 "SUBCOMPONENT3" 31 "SUBCOMPONENT4" 255 "END" ;
VAL_ 769 VCFRONT_infoBuildType 0 "UNKNOWN_BUILD" 1 "PLATFORM_BUILD" 2 "LOCAL_BUILD" 3 "TRACEABLE_CI_BUILD" 4 "MFG_BUILD" ;
VAL_ 769 VCFRONT_infoAssemblyId 1 "ASSEMBLY1" 255 "ASSEMBLY_SNA" ;
VAL_ 770 VCLEFT_infoIndex 0 "DEPRECATED_0" 1 "DEPRECATED_1" 2 "DEPRECATED_2" 3 "DEPRECATED_3" 4 "DEPRECATED_4" 5 "DEPRECATED_5" 6 "DEPRECATED_6" 7 "DEPRECATED_7" 8 "DEPRECATED_8" 9 "DEPRECATED_9" 10 "BUILD_HWID_COMPONENTID" 11 "PCBAID_ASSYID_USAGEID" 13 "APP_CRC" 14 "BOOTLOADER_SVN" 15 "BOOTLOADER_CRC" 16 "SUBCOMPONENT1" 17 "APP_GITHASH" 18 "BOOTLOADER_GITHASH" 19 "VERSION_DEPRECATED" 20 "UDS_PROTOCOL_BOOTCRC" 23 "SUBCOMPONENT2" 24 "SUBCOMPONENT3" 31 "SUBCOMPONENT4" 255 "END" ;
VAL_ 770 VCLEFT_infoBuildType 0 "UNKNOWN_BUILD" 1 "PLATFORM_BUILD" 2 "LOCAL_BUILD" 3 "TRACEABLE_CI_BUILD" 4 "MFG_BUILD" ;
VAL_ 770 VCLEFT_infoAssemblyId 1 "ASSEMBLY1" 255 "ASSEMBLY_SNA" ;
VAL_ 771 OCS1P_classificationHoldState 0 "OFF" 1 "BASIC" 2 "EXTERNAL" 3 "FAULT" ;
VAL_ 771 OCS1P_occupantClassification 0 "EMPTY" 1 "OCCUPIED_INHIBIT" 2 "OCCUPIED_ALLOW_SMALL" 3 "OCCUPIED_ALLOW_LARGE" 4 "INIT" 255 "SNA" ;
VAL_ 771 OCS1P_occupantClassificationQF 0 "FAULTED" 1 "NOT_FAULTED" ;
VAL_ 771 OCS1P_occupantClassificationRaw 0 "EMPTY" 1 "OCCUPIED_INHIBIT" 2 "OCCUPIED_ALLOW_SMALL" 3 "OCCUPIED_ALLOW_LARGE" 4 "INIT" 255 "SNA" ;
VAL_ 771 OCS1P_occupantClassificationSelf 0 "EMPTY" 1 "OCCUPIED_INHIBIT" 2 "OCCUPIED_ALLOW_SMALL" 3 "OCCUPIED_ALLOW_LARGE" 4 "INIT" 255 "SNA" ;
VAL_ 771 OCS1P_occupiedState 0 "UNOCCUPIED" 1 "OCCUPIED" 3 "SNA" ;
VAL_ 774 VCRIGHT_infoIndex 0 "DEPRECATED_0" 1 "DEPRECATED_1" 2 "DEPRECATED_2" 3 "DEPRECATED_3" 4 "DEPRECATED_4" 5 "DEPRECATED_5" 6 "DEPRECATED_6" 7 "DEPRECATED_7" 8 "DEPRECATED_8" 9 "DEPRECATED_9" 10 "BUILD_HWID_COMPONENTID" 11 "PCBAID_ASSYID_USAGEID" 13 "APP_CRC" 14 "BOOTLOADER_SVN" 15 "BOOTLOADER_CRC" 16 "SUBCOMPONENT1" 17 "APP_GITHASH" 18 "BOOTLOADER_GITHASH" 19 "VERSION_DEPRECATED" 20 "UDS_PROTOCOL_BOOTCRC" 23 "SUBCOMPONENT2" 24 "SUBCOMPONENT3" 31 "SUBCOMPONENT4" 255 "END" ;
VAL_ 774 VCRIGHT_infoBuildType 0 "UNKNOWN_BUILD" 1 "PLATFORM_BUILD" 2 "LOCAL_BUILD" 3 "TRACEABLE_CI_BUILD" 4 "MFG_BUILD" ;
VAL_ 774 VCRIGHT_infoAssemblyId 1 "ASSEMBLY1" 255 "ASSEMBLY_SNA" ;
VAL_ 777 DAS_objectId 0 "LEAD_VEHICLES" 1 "LEFT_VEHICLES" 2 "RIGHT_VEHICLES" 3 "CUTIN_VEHICLE" 4 "ROAD_SIGN" 5 "VEHICLE_HEADINGS" ;
VAL_ 777 DAS_leadVehType 0 "UNKNOWN" 1 "TRUCK" 2 "CAR" 3 "MOTORCYCLE" 4 "BICYCLE" 5 "PEDESTRIAN" 6 "IPSO" ;
VAL_ 777 DAS_leadVehDx 255 "SNA" ;
VAL_ 777 DAS_leadVehVxRel 15 "SNA" ;
VAL_ 777 DAS_leadVehId 127 "SNA" ;
VAL_ 777 DAS_leadVeh2Type 0 "UNKNOWN" 1 "TRUCK" 2 "CAR" 3 "MOTORCYCLE" 4 "BICYCLE" 5 "PEDESTRIAN" ;
VAL_ 777 DAS_leadVeh2Dx 255 "SNA" ;
VAL_ 777 DAS_leadVeh2VxRel 15 "SNA" ;
VAL_ 777 DAS_leadVeh2Id 0 "SNA" ;
VAL_ 777 DAS_leftVehType 0 "UNKNOWN" 1 "TRUCK" 2 "CAR" 3 "MOTORCYCLE" 4 "BICYCLE" 5 "PEDESTRIAN" ;
VAL_ 777 DAS_leftVehDx 255 "SNA" ;
VAL_ 777 DAS_leftVehVxRel 15 "SNA" ;
VAL_ 777 DAS_leftVehId 127 "SNA" ;
VAL_ 777 DAS_leftVeh2Type 0 "UNKNOWN" 1 "TRUCK" 2 "CAR" 3 "MOTORCYCLE" 4 "BICYCLE" 5 "PEDESTRIAN" ;
VAL_ 777 DAS_leftVeh2Dx 255 "SNA" ;
VAL_ 777 DAS_leftVeh2VxRel 15 "SNA" ;
VAL_ 777 DAS_leftVeh2Id 0 "SNA" ;
VAL_ 777 DAS_rightVehType 0 "UNKNOWN" 1 "TRUCK" 2 "CAR" 3 "MOTORCYCLE" 4 "BICYCLE" 5 "PEDESTRIAN" ;
VAL_ 777 DAS_rightVehDx 255 "SNA" ;
VAL_ 777 DAS_rightVehVxRel 15 "SNA" ;
VAL_ 777 DAS_rightVehId 127 "SNA" ;
VAL_ 777 DAS_rightVeh2Type 0 "UNKNOWN" 1 "TRUCK" 2 "CAR" 3 "MOTORCYCLE" 4 "BICYCLE" 5 "PEDESTRIAN" ;
VAL_ 777 DAS_rightVeh2Dx 255 "SNA" ;
VAL_ 777 DAS_rightVeh2VxRel 15 "SNA" ;
VAL_ 777 DAS_rightVeh2Id 0 "SNA" ;
VAL_ 777 DAS_cutinVehType 0 "UNKNOWN" 1 "TRUCK" 2 "CAR" 3 "MOTORCYCLE" 4 "BICYCLE" 5 "PEDESTRIAN" ;
VAL_ 777 DAS_cutinVehDx 255 "SNA" ;
VAL_ 777 DAS_cutinVehVxRel 15 "SNA" ;
VAL_ 777 DAS_cutinVehId 127 "SNA" ;
VAL_ 777 DAS_roadSignColor 0 "NONE" 1 "RED" 2 "YELLOW" 3 "GREEN" 4 "RED_YELLOW" ;
VAL_ 777 DAS_roadSignId 0 "STOP_SIGN" 1 "TRAFFIC_LIGHT" 255 "SNA" ;
VAL_ 777 DAS_roadSignStopLineDist 1023 "SNA" ;
VAL_ 777 DAS_roadSignSource 0 "NONE" 1 "NAV" 2 "VISION" ;
VAL_ 777 DAS_roadSignArrow 0 "CIRCLE" 1 "LEFT" 2 "RIGHT" 3 "STRAIGHT" 4 "UNKNOWN" ;
VAL_ 777 DAS_roadSignOrientation 0 "UNKNOWN" 1 "VERTICAL_3_LIGHT" 2 "HORIZONTAL_3_LIGHT" ;
VAL_ 777 DAS_leadVehHeading 255 "SNA" ;
VAL_ 777 DAS_leadVeh2Heading 255 "SNA" ;
VAL_ 777 DAS_leftVehHeading 255 "SNA" ;
VAL_ 777 DAS_leftVeh2Heading 255 "SNA" ;
VAL_ 777 DAS_rightVehHeading 255 "SNA" ;
VAL_ 777 DAS_rightVeh2Heading 255 "SNA" ;
VAL_ 777 DAS_cutinVehHeading 255 "SNA" ;
VAL_ 778 VCLEFT_frontBuckleStatus 0 "UNLATCHED" 1 "LATCHED" 2 "FAULTED" 3 "SNA" ;
VAL_ 778 VCLEFT_frontOccupancyStatus 0 "UNOCCUPIED" 1 "OCCUPIED" 2 "OCCUPANCY_FAULTED" 3 "NOT_CONFIGURED" 7 "OCCUPANCY_SNA" ;
VAL_ 778 VCLEFT_rearCenterOccupancyStatus 0 "UNOCCUPIED" 1 "OCCUPIED" 2 "OCCUPANCY_FAULTED" 3 "OCCUPANCY_SNA" ;
VAL_ 778 VCLEFT_rearLeftBuckleStatus 0 "UNLATCHED" 1 "LATCHED" 2 "FAULTED" 3 "SNA" ;
VAL_ 778 VCLEFT_rearLeftOccupancyStatus 0 "UNOCCUPIED" 1 "OCCUPIED" 2 "OCCUPANCY_FAULTED" 3 "OCCUPANCY_SNA" ;
VAL_ 778 VCLEFT_rearRightOccupancyStatus 0 "UNOCCUPIED" 1 "OCCUPIED" 2 "OCCUPANCY_FAULTED" 3 "OCCUPANCY_SNA" ;
VAL_ 782 PARK_autoCalComplete 0 "INCOMPLETE" 1 "COMPLETE" ;
VAL_ 782 PARK_geometryType 0 "MODELS" 1 "MODELS_2" 2 "MODELX" 3 "MODEL3" ;
VAL_ 782 PARK_pscLeftCurbType 0 "VIRTUAL_CURB" 1 "LOW_CURB" 2 "HIGH_CURB" ;
VAL_ 782 PARK_pscRightCurbType 0 "VIRTUAL_CURB" 1 "LOW_CURB" 2 "HIGH_CURB" ;
VAL_ 782 PARK_rackDetected 0 "UNKNOWN" 1 "NO_RACK" 2 "RACK_DETECTED" 3 "SNA" ;
VAL_ 782 PARK_sdiActive 0 "DISABLED" 1 "ENABLED" ;
VAL_ 782 PARK_sdiBlindSpotLeft 0 "NO_WARNING" 1 "WARNING" 2 "UNUSED" 3 "SNA" ;
VAL_ 782 PARK_sdiBlindSpotRight 0 "NO_WARNING" 1 "WARNING" 2 "UNUSED" 3 "SNA" ;
VAL_ 782 PARK_sdiNoise 0 "NOMINAL" 1 "HIGH" 2 "RAIN" 3 "SNA" ;
VAL_ 782 PARK_tireFitment 0 "SQUARE" 1 "STAGGERED" 2 "NOT_USED" 3 "SNA" ;
VAL_ 784 HVP_infoIndex 0 "DEPRECATED_0" 1 "DEPRECATED_1" 2 "DEPRECATED_2" 3 "DEPRECATED_3" 4 "DEPRECATED_4" 5 "DEPRECATED_5" 6 "DEPRECATED_6" 7 "DEPRECATED_7" 8 "DEPRECATED_8" 9 "DEPRECATED_9" 10 "BUILD_HWID_COMPONENTID" 11 "PCBAID_ASSYID_USAGEID" 13 "APP_CRC" 14 "BOOTLOADER_SVN" 15 "BOOTLOADER_CRC" 16 "SUBCOMPONENT" 17 "APP_GITHASH" 18 "BOOTLOADER_GITHASH" 19 "VERSION_DEPRECATED" 20 "UDS_PROTOCOL_BOOTCRC" 22 "VARIANTCRC" 25 "PACKAGE_PN_1_7" 26 "PACKAGE_PN_8_14" 27 "PACKAGE_PN_15_20" 29 "PACKAGE_SN_1_7" 30 "PACKAGE_SN_8_14" 31 "SUBCOMPONENT_GITHASH" 255 "END" ;
VAL_ 784 HVP_buildType 0 "UNKNOWN_BUILD" 1 "PLATFORM_BUILD" 2 "LOCAL_BUILD" 3 "TRACEABLE_CI_BUILD" 4 "MFG_BUILD" ;
VAL_ 785 EPAS3S_infoIndex 0 "DEPRECATED_0" 1 "DEPRECATED_1" 2 "DEPRECATED_2" 3 "DEPRECATED_3" 4 "DEPRECATED_4" 5 "DEPRECATED_5" 6 "DEPRECATED_6" 7 "DEPRECATED_7" 8 "DEPRECATED_8" 9 "DEPRECATED_9" 10 "BUILD_HWID_COMPONENTID" 11 "PCBAID_ASSYID_USAGEID" 13 "APP_CRC" 14 "BOOTLOADER_SVN" 15 "BOOTLOADER_CRC" 16 "SUBCOMPONENT" 17 "APP_GITHASH" 18 "BOOTLOADER_GITHASH" 19 "VERSION_DEPRECATED" 20 "UDS_PROTOCOL_BOOTCRC" 22 "VARIANTCRC" 25 "PACKAGE_PN_1_7" 26 "PACKAGE_PN_8_14" 27 "PACKAGE_PN_15_20" 29 "PACKAGE_SN_1_7" 30 "PACKAGE_SN_8_14" 31 "SUBCOMPONENT_GITHASH" 255 "END" ;
VAL_ 785 EPAS3S_infoBuildType 0 "UNKNOWN_BUILD" 1 "PLATFORM_BUILD" 2 "LOCAL_BUILD" 3 "TRACEABLE_CI_BUILD" 4 "MFG_BUILD" ;
VAL_ 787 UI_creepTorque 0 "OFF" 1 "ON" ;
VAL_ 787 UI_limitMode 0 "NORMAL" 1 "VALET" 2 "FACTORY" ;
VAL_ 787 UI_motorOnMode 0 "NORMAL" 1 "FRONT_ONLY" 2 "REAR_ONLY" ;
VAL_ 787 UI_pedalMap 0 "CHILL" 1 "SPORT" ;
VAL_ 787 UI_speedLimit 255 "SNA" ;
VAL_ 787 UI_systemPowerLimit 31 "SNA" ;
VAL_ 787 UI_systemTorqueLimit 63 "SNA" ;
VAL_ 787 UI_trackModeRequest 0 "IDLE" 1 "ON" 2 "OFF" ;
VAL_ 787 UI_wasteMode 0 "NONE" 1 "PARTIAL" 2 "FULL" ;
VAL_ 787 UI_wasteModeRegenLimit 0 "MAX" 1 "30A" 2 "10A" 3 "0A" ;
VAL_ 789 DI_inverterTQF 0 "INIT" 1 "IRRATIONAL" 2 "RATIONAL" 3 "UNKNOWN" ;
VAL_ 790 PM_infoIndex 0 "DEPRECATED_0" 1 "DEPRECATED_1" 2 "DEPRECATED_2" 3 "DEPRECATED_3" 4 "DEPRECATED_4" 5 "DEPRECATED_5" 6 "DEPRECATED_6" 7 "DEPRECATED_7" 8 "DEPRECATED_8" 9 "DEPRECATED_9" 10 "BUILD_HWID_COMPONENTID" 11 "PCBAID_ASSYID_USAGEID" 13 "APP_CRC" 14 "BOOTLOADER_SVN" 15 "BOOTLOADER_CRC" 16 "SUBCOMPONENT" 17 "APP_GITHASH" 18 "BOOTLOADER_GITHASH" 19 "VERSION_DEPRECATED" 20 "UDS_PROTOCOL_BOOTCRC" 22 "VARIANTCRC" 25 "PACKAGE_PN_1_7" 26 "PACKAGE_PN_8_14" 27 "PACKAGE_PN_15_20" 29 "PACKAGE_SN_1_7" 30 "PACKAGE_SN_8_14" 31 "SUBCOMPONENT_GITHASH" 255 "END" ;
VAL_ 790 PM_buildType 0 "UNKNOWN_BUILD" 1 "PLATFORM_BUILD" 2 "LOCAL_BUILD" 3 "TRACEABLE_CI_BUILD" 4 "MFG_BUILD" ;
VAL_ 790 PM_hardwareId 252 "CONFIGURABLE_HWID_PLACEHOLDER" ;
VAL_ 793 VCSEC_infoIndex 0 "DEPRECATED_0" 1 "DEPRECATED_1" 2 "DEPRECATED_2" 3 "DEPRECATED_3" 4 "DEPRECATED_4" 5 "DEPRECATED_5" 6 "DEPRECATED_6" 7 "DEPRECATED_7" 8 "DEPRECATED_8" 9 "DEPRECATED_9" 10 "BUILD_HWID_COMPONENTID" 11 "PCBAID_ASSYID_USAGEID" 13 "APP_CRC" 14 "BOOTLOADER_SVN" 15 "BOOTLOADER_CRC" 16 "SUBCOMPONENT1" 17 "APP_GITHASH" 18 "BOOTLOADER_GITHASH" 19 "VERSION_DEPRECATED" 20 "UDS_PROTOCOL_BOOTCRC" 23 "SUBCOMPONENT2" 24 "SUBCOMPONENT3" 31 "SUBCOMPONENT4" 255 "END" ;
VAL_ 793 VCSEC_infoBuildType 0 "UNKNOWN_BUILD" 1 "PLATFORM_BUILD" 2 "LOCAL_BUILD" 3 "TRACEABLE_CI_BUILD" 4 "MFG_BUILD" ;
VAL_ 793 VCSEC_infoAssemblyId 1 "ASSEMBLY1" 255 "ASSEMBLY_SNA" ;
VAL_ 794 VCRIGHT_frontBuckleStatus 0 "UNLATCHED" 1 "LATCHED" 2 "FAULTED" 3 "SNA" ;
VAL_ 794 VCRIGHT_frontOccupancyStatus 0 "UNOCCUPIED" 1 "OCCUPIED" 2 "OCCUPANCY_FAULTED" 3 "NOT_CONFIGURED" 7 "OCCUPANCY_SNA" ;
VAL_ 794 VCRIGHT_rearCenterBuckleStatus 0 "UNLATCHED" 1 "LATCHED" 2 "FAULTED" 3 "SNA" ;
VAL_ 794 VCRIGHT_rearRightBuckleStatus 0 "UNLATCHED" 1 "LATCHED" 2 "FAULTED" 3 "SNA" ;
VAL_ 796 CC_currentLimit 255 "SNA" ;
VAL_ 796 CC_gridGrounding 0 "TN_TT" 1 "IT_SplitPhase" 2 "SNA" ;
VAL_ 796 CC_line1Voltage 511 "SNA" ;
VAL_ 796 CC_line2Voltage 511 "SNA" ;
VAL_ 796 CC_line3Voltage 511 "SNA" ;
VAL_ 796 CC_numPhases 0 "SNA" ;
VAL_ 796 CC_pilotState 0 "READY" 1 "IDLE" 2 "FAULTED" 3 "SNA" ;
VAL_ 797 CC_chgStatus2Index 0 "Mux0" ;
VAL_ 797 CC_buttonState 0 "RELEASED" 1 "PRESSED" ;
VAL_ 798 CP_matrixIndex 0 "AlertMatrix0" 1 "AlertMatrix1" ;
VAL_ 799 TPMS_pressureFL 255 "SNA" ;
VAL_ 799 TPMS_pressureFR 255 "SNA" ;
VAL_ 799 TPMS_pressureRL 255 "SNA" ;
VAL_ 799 TPMS_pressureRR 255 "SNA" ;
VAL_ 799 TPMS_temperatureFL 255 "SNA" ;
VAL_ 799 TPMS_temperatureFR 255 "SNA" ;
VAL_ 799 TPMS_temperatureRL 255 "SNA" ;
VAL_ 799 TPMS_temperatureRR 255 "SNA" ;
VAL_ 800 BMS_matrixIndex 0 "AlertMatrix0" 1 "AlertMatrix1" 2 "AlertMatrix2" ;
VAL_ 801 VCFRONT_brakeFluidLevel 0 "SNA" 1 "LOW" 2 "NORMAL" ;
VAL_ 801 VCFRONT_coolantLevel 0 "NOT_OK" 1 "FILLED" ;
VAL_ 801 VCFRONT_tempAmbient 0 "SNA" ;
VAL_ 801 VCFRONT_tempAmbientFiltered 0 "SNA" ;
VAL_ 801 VCFRONT_tempCoolantBatInlet 1023 "SNA" ;
VAL_ 801 VCFRONT_tempCoolantPTInlet 2047 "SNA" ;
VAL_ 801 VCFRONT_washerFluidLevel 0 "SNA" 1 "LOW" 2 "NORMAL" ;
VAL_ 806 PARK_infoIndex 0 "DEPRECATED_0" 1 "DEPRECATED_1" 2 "DEPRECATED_2" 3 "DEPRECATED_3" 4 "DEPRECATED_4" 5 "DEPRECATED_5" 6 "DEPRECATED_6" 7 "DEPRECATED_7" 8 "DEPRECATED_8" 9 "DEPRECATED_9" 10 "BUILD_HWID_COMPONENTID" 11 "PCBAID_ASSYID_USAGEID" 13 "APP_CRC" 14 "BOOTLOADER_SVN" 15 "BOOTLOADER_CRC" 16 "SUBCOMPONENT" 17 "APP_GITHASH" 18 "BOOTLOADER_GITHASH" 19 "VERSION_DEPRECATED" 20 "UDS_PROTOCOL_BOOTCRC" 22 "VARIANTCRC" 25 "PACKAGE_PN_1_7" 26 "PACKAGE_PN_8_14" 27 "PACKAGE_PN_15_20" 29 "PACKAGE_SN_1_7" 30 "PACKAGE_SN_8_14" 31 "SUBCOMPONENT_GITHASH" 255 "END" ;
VAL_ 806 PARK_infoBuildType 0 "UNKNOWN_BUILD" 1 "PLATFORM_BUILD" 2 "LOCAL_BUILD" 3 "TRACEABLE_CI_BUILD" 4 "MFG_BUILD" ;
VAL_ 808 ESP_infoIndex 0 "DEPRECATED_0" 1 "DEPRECATED_1" 2 "DEPRECATED_2" 3 "DEPRECATED_3" 4 "DEPRECATED_4" 5 "DEPRECATED_5" 6 "DEPRECATED_6" 7 "DEPRECATED_7" 8 "DEPRECATED_8" 9 "DEPRECATED_9" 10 "BUILD_HWID_COMPONENTID" 11 "PCBAID_ASSYID_USAGEID" 13 "APP_CRC" 14 "BOOTLOADER_SVN" 15 "BOOTLOADER_CRC" 16 "SUBCOMPONENT" 17 "APP_GITHASH" 18 "BOOTLOADER_GITHASH" 19 "VERSION_DEPRECATED" 20 "UDS_PROTOCOL_BOOTCRC" 22 "VARIANTCRC" 25 "PACKAGE_PN_1_7" 26 "PACKAGE_PN_8_14" 27 "PACKAGE_PN_15_20" 29 "PACKAGE_SN_1_7" 30 "PACKAGE_SN_8_14" 31 "SUBCOMPONENT_GITHASH" 255 "END" ;
VAL_ 808 ESP_infoBuildType 0 "UNKNOWN_BUILD" 1 "PLATFORM_BUILD" 2 "LOCAL_BUILD" 3 "TRACEABLE_CI_BUILD" 4 "MFG_BUILD" ;
VAL_ 808 ESP_infoVehicleVariant 1 "01" 2 "02" 3 "03" 4 "04" 5 "05" 6 "06" 7 "07" 8 "08" 9 "09" ;
VAL_ 812 CC_logIndex 0 "Mux0" 1 "Mux1" 2 "Mux2" 3 "Mux3" 4 "Mux4" 10 "Mux10" 11 "Mux11" 12 "Mux12" 13 "Mux13" ;
VAL_ 812 CC_activeConnectorID 255 "SNA" ;
VAL_ 812 CC_temperature1 127 "SNA" ;
VAL_ 812 CC_temperature2 127 "SNA" ;
VAL_ 812 CC_temperature3 127 "SNA" ;
VAL_ 812 CC_contactor1Closed 0 "OPEN" 1 "CLOSED" 3 "SNA" ;
VAL_ 812 CC_contactor2Closed 0 "OPEN" 1 "CLOSED" 3 "SNA" ;
VAL_ 812 CC_temperature4 127 "SNA" ;
VAL_ 812 CC_conn1Current 255 "SNA" ;
VAL_ 812 CC_conn2Current 255 "SNA" ;
VAL_ 812 CC_conn3Current 255 "SNA" ;
VAL_ 812 CC_conn4Current 255 "SNA" ;
VAL_ 813 IBST_infoIndex 0 "DEPRECATED_0" 1 "DEPRECATED_1" 2 "DEPRECATED_2" 3 "DEPRECATED_3" 4 "DEPRECATED_4" 5 "DEPRECATED_5" 6 "DEPRECATED_6" 7 "DEPRECATED_7" 8 "DEPRECATED_8" 9 "DEPRECATED_9" 10 "BUILD_HWID_COMPONENTID" 11 "PCBAID_ASSYID_USAGEID" 13 "APP_CRC" 14 "BOOTLOADER_SVN" 15 "BOOTLOADER_CRC" 16 "SUBCOMPONENT" 17 "APP_GITHASH" 18 "BOOTLOADER_GITHASH" 19 "VERSION_DEPRECATED" 20 "UDS_PROTOCOL_BOOTCRC" 22 "VARIANTCRC" 25 "PACKAGE_PN_1_7" 26 "PACKAGE_PN_8_14" 27 "PACKAGE_PN_15_20" 29 "PACKAGE_SN_1_7" 30 "PACKAGE_SN_8_14" 31 "SUBCOMPONENT_GITHASH" 255 "END" ;
VAL_ 813 IBST_infoBuildType 0 "UNKNOWN_BUILD" 1 "PLATFORM_BUILD" 2 "LOCAL_BUILD" 3 "TRACEABLE_CI_BUILD" 4 "MFG_BUILD" ;
VAL_ 814 PARK_frontDtcPresent 0 "FALSE" 1 "TRUE" 2 "UNUSED" 3 "SNA" ;
VAL_ 814 PARK_frontLeftMiddleSensorState 0 "NO_FAILURE" 1 "PERMANENT_FAILURE" 2 "TEMPORARY_FAILURE" 3 "SNA" ;
VAL_ 814 PARK_frontLeftRawDistData 255 "SNA" ;
VAL_ 814 PARK_frontLeftSensorState 0 "NO_FAILURE" 1 "PERMANENT_FAILURE" 2 "TEMPORARY_FAILURE" 3 "SNA" ;
VAL_ 814 PARK_frontRightMiddleSensorState 0 "NO_FAILURE" 1 "PERMANENT_FAILURE" 2 "TEMPORARY_FAILURE" 3 "SNA" ;
VAL_ 814 PARK_frontRightRawDistData 255 "SNA" ;
VAL_ 814 PARK_frontRightSensorState 0 "NO_FAILURE" 1 "PERMANENT_FAILURE" 2 "TEMPORARY_FAILURE" 3 "SNA" ;
VAL_ 814 PARK_systemStatusFront 0 "DISABLED" 1 "ENABLED" 2 "UNUSED" 3 "SNA" ;
VAL_ 816 SCCM_infoIndex 10 "BUILD_HWID_COMPONENTID" 11 "PCBAID_ASSYID_USAGEID" 13 "APP_CRC" 14 "BOOTLOADER_SVN" 16 "SUBCOMPONENT1" 17 "APP_SVNHASH" 18 "BOOTLOADER_SVNHASH" 20 "UDS_PROTOCOL_BOOTCRC" 255 "END" ;
VAL_ 816 SCCM_infoBuildType 0 "UNKNOWN_BUILD" 1 "PLATFORM_BUILD" 2 "LOCAL_BUILD" 3 "TRACEABLE_CI_BUILD" 4 "MFG_BUILD" ;
VAL_ 817 EPAS3P_infoIndex 0 "DEPRECATED_0" 1 "DEPRECATED_1" 2 "DEPRECATED_2" 3 "DEPRECATED_3" 4 "DEPRECATED_4" 5 "DEPRECATED_5" 6 "DEPRECATED_6" 7 "DEPRECATED_7" 8 "DEPRECATED_8" 9 "DEPRECATED_9" 10 "BUILD_HWID_COMPONENTID" 11 "PCBAID_ASSYID_USAGEID" 13 "APP_CRC" 14 "BOOTLOADER_SVN" 15 "BOOTLOADER_CRC" 16 "SUBCOMPONENT" 17 "APP_GITHASH" 18 "BOOTLOADER_GITHASH" 19 "VERSION_DEPRECATED" 20 "UDS_PROTOCOL_BOOTCRC" 22 "VARIANTCRC" 25 "PACKAGE_PN_1_7" 26 "PACKAGE_PN_8_14" 27 "PACKAGE_PN_15_20" 29 "PACKAGE_SN_1_7" 30 "PACKAGE_SN_8_14" 31 "SUBCOMPONENT_GITHASH" 255 "END" ;
VAL_ 817 EPAS3P_infoBuildType 0 "UNKNOWN_BUILD" 1 "PLATFORM_BUILD" 2 "LOCAL_BUILD" 3 "TRACEABLE_CI_BUILD" 4 "MFG_BUILD" ;
VAL_ 818 BMS_bmbMinMaxMultiplexer 0 "THERM_MUX0" 1 "VOLT_MUX1" 2 "END" ;
VAL_ 819 UI_acChargeCurrentLimit 127 "SNA" ;
VAL_ 819 UI_brickBalancingDisabled 0 "FALSE" 1 "TRUE" ;
VAL_ 819 UI_brickVLoggingRequest 0 "FALSE" 1 "TRUE" ;
VAL_ 820 UI_limitMode 2 "LIMIT_FACTORY" 0 "LIMIT_NORMAL" 3 "LIMIT_SERVICE" 1 "LIMIT_VALET" ;
VAL_ 820 UI_motorOnMode 1 "MOTORONMODE_FRONT_ONLY" 0 "MOTORONMODE_NORMAL" 2 "MOTORONMODE_REAR_ONLY" ;
VAL_ 820 UI_pedalMap 0 "CHILL" 2 "PERFORMANCE" 1 "SPORT" ;
VAL_ 820 UI_speedLimit 255 "SNA" ;
VAL_ 820 UI_stoppingMode 1 "CREEP" 2 "HOLD" 0 "STANDARD" ;
VAL_ 820 UI_systemPowerLimit 31 "SNA" ;
VAL_ 820 UI_systemTorqueLimit 63 "SNA" ;
VAL_ 820 UI_wasteMode 2 "WASTE_TYPE_FULL" 0 "WASTE_TYPE_NONE" 1 "WASTE_TYPE_PARTIAL" ;
VAL_ 820 UI_wasteModeRegenLimit 3 "MAX_REGEN_CURRENT_0A" 2 "MAX_REGEN_CURRENT_10A" 1 "MAX_REGEN_CURRENT_30A" 0 "MAX_REGEN_CURRENT_MAX" ;
VAL_ 820 UI_closureConfirmed 1 "CONFIRMED_FRUNK" 0 "CONFIRMED_NONE" 2 "CONFIRMED_PROX" ;
VAL_ 821 DIS_infoIndex 0 "DEPRECATED_0" 1 "DEPRECATED_1" 2 "DEPRECATED_2" 3 "DEPRECATED_3" 4 "DEPRECATED_4" 5 "DEPRECATED_5" 6 "DEPRECATED_6" 7 "DEPRECATED_7" 8 "DEPRECATED_8" 9 "DEPRECATED_9" 10 "BUILD_HWID_COMPONENTID" 11 "PCBAID_ASSYID_USAGEID" 13 "APP_CRC" 14 "BOOTLOADER_SVN" 15 "BOOTLOADER_CRC" 16 "SUBCOMPONENT" 17 "APP_GITHASH" 18 "BOOTLOADER_GITHASH" 19 "VERSION_DEPRECATED" 20 "UDS_PROTOCOL_BOOTCRC" 22 "VARIANTCRC" 25 "PACKAGE_PN_1_7" 26 "PACKAGE_PN_8_14" 27 "PACKAGE_PN_15_20" 29 "PACKAGE_SN_1_7" 30 "PACKAGE_SN_8_14" 31 "SUBCOMPONENT_GITHASH" 255 "END" ;
VAL_ 821 DIS_buildType 0 "UNKNOWN_BUILD" 1 "PLATFORM_BUILD" 2 "LOCAL_BUILD" 3 "TRACEABLE_CI_BUILD" 4 "MFG_BUILD" ;
VAL_ 821 DIS_hardwareId 252 "CONFIGURABLE_HWID_PLACEHOLDER" ;
VAL_ 821 DIS_oilPumpBuildType 0 "UNKNOWN_BUILD" 1 "PLATFORM_BUILD" 2 "LOCAL_BUILD" 3 "TRACEABLE_CI_BUILD" 4 "MFG_BUILD" ;
VAL_ 821 DIR_FPGA_version 254 "FPGA_VERSION_LOCAL_BUILD" 255 "FPGA_VERSION_SNA" ;
VAL_ 822 DI_sysDrivePowerRated 511 "SNA" ;
VAL_ 822 DI_sysRegenPowerRated 255 "SNA" ;
VAL_ 825 VCSEC_MCUCommandType 0 "NONE" 1 "REMOTE_UNLOCK" 2 "REMOTE_START" 3 "COMMAND3" 4 "COMMAND4" 5 "COMMAND5" ;
VAL_ 825 VCSEC_alarmStatus 0 "DISARMED" 1 "ARMED" 2 "PARTIAL_ARMED" 3 "TRIGGERED_FLASH_ACTIVE" 4 "ERROR" 5 "TRIGGERED_FLASH_INACTIVE" 6 "IMMINENT" 7 "DEFAULT" 15 "SNA" ;
VAL_ 825 VCSEC_authenticationStatus 0 "NONE" 1 "AUTHENTICATED_FOR_UNLOCK" 2 "AUTHENTICATED_FOR_DRIVE" ;
VAL_ 825 VCSEC_chargePortLockStatus 0 "UNLOCKED" 1 "LOCKED" ;
VAL_ 825 VCSEC_frunkRequest 0 "NONE" 1 "OPEN" 2 "SNA" ;
VAL_ 825 VCSEC_immobilizerState 0 "IDLE" 1 "PREPARE" 2 "ENCRYPT_BEGIN" 3 "ENCRYPT" 4 "SEND_AUTH_RESPONSE" 5 "SEND_NO_GO_AUTH_RESPONSE" ;
VAL_ 825 VCSEC_keyChannelIndexed 15 "SNA" ;
VAL_ 825 VCSEC_leftFrontLockStatus 0 "UNLOCKED" 1 "LOCKED" ;
VAL_ 825 VCSEC_leftRearLockStatus 0 "UNLOCKED" 1 "LOCKED" ;
VAL_ 825 VCSEC_lockIndicationRequest 0 "NONE_SNA" 1 "SINGLE" 2 "DOUBLE" 3 "TRIPLE" 4 "HOLD" ;
VAL_ 825 VCSEC_lockRequestType 0 "NONE" 1 "PASSIVE_SHIFT_TO_P_UNLOCK" 2 "PASSIVE_PARKBUTTON_UNLOCK" 3 "PASSIVE_INTERNAL_HANDLE_UNLOCK" 4 "PASSIVE_DRIVE_AWAY_LOCK" 5 "PASSIVE_BLE_WALKUP_UNLOCK" 6 "PASSIVE_BLE_EXTERIOR_CHARGEHANDLEBUTTON_UNLOCK" 7 "PASSIVE_BLE_EXTERIOR_HANDLE_UNLOCK" 8 "PASSIVE_BLE_INTERIOR_HANDLE_UNLOCK" 9 "PASSIVE_BLE_LOCK" 10 "CRASH_UNLOCK" 11 "ACTIVE_UI_BUTTON_UNLOCK" 12 "ACTIVE_UI_BUTTON_LOCK" 13 "ACTIVE_REMOTE_UNLOCK" 14 "ACTIVE_REMOTE_LOCK" 15 "ACTIVE_NFC_UNLOCK" 16 "ACTIVE_NFC_LOCK" 17 "ACTIVE_BLE_UNLOCK" 18 "ACTIVE_BLE_LOCK" 19 "PASSIVE_INTERNAL_LOCK_PROMOTION" ;
VAL_ 825 VCSEC_rightFrontLockStatus 0 "UNLOCKED" 1 "LOCKED" ;
VAL_ 825 VCSEC_rightRearLockStatus 0 "UNLOCKED" 1 "LOCKED" ;
VAL_ 825 VCSEC_simpleLockStatus 0 "SNA" 1 "UNLOCKED" 2 "LOCKED" ;
VAL_ 825 VCSEC_summonRequest 0 "IDLE" 1 "PRIME" 2 "FORWARD" 3 "BACKWARD" 4 "STOP" 5 "SNA" ;
VAL_ 825 VCSEC_trunkLockStatus 0 "UNLOCKED" 1 "LOCKED" ;
VAL_ 825 VCSEC_trunkRequest 0 "NONE" 1 "OPEN" 2 "SNA" ;
VAL_ 825 VCSEC_vehicleLockStatus 0 "SNA" 1 "ACTIVE_NFC_UNLOCKED" 2 "ACTIVE_NFC_LOCKED" 3 "PASSIVE_SELECTIVE_UNLOCKED" 4 "PASSIVE_BLE_UNLOCKED" 5 "PASSIVE_BLE_LOCKED" 6 "ACTIVE_SELECTIVE_UNLOCKED" 7 "ACTIVE_BLE_UNLOCKED" 8 "ACTIVE_BLE_LOCKED" 9 "ACTIVE_UI_UNLOCKED" 10 "ACTIVE_UI_LOCKED" 11 "ACTIVE_REMOTE_UNLOCKED" 12 "ACTIVE_REMOTE_LOCKED" 13 "CRASH_UNLOCKED" 14 "PASSIVE_INTERNAL_UNLOCKED" 15 "PASSIVE_INTERNAL_LOCKED" ;
VAL_ 830 PARK_rearDtcPresent 0 "FALSE" 1 "TRUE" 2 "UNUSED" 3 "SNA" ;
VAL_ 830 PARK_rearLeftMiddleSensorState 0 "NO_FAILURE" 1 "PERMANENT_FAILURE" 2 "TEMPORARY_FAILURE" 3 "SNA" ;
VAL_ 830 PARK_rearLeftRawDistData 255 "SNA" ;
VAL_ 830 PARK_rearLeftSensorState 0 "NO_FAILURE" 1 "PERMANENT_FAILURE" 2 "TEMPORARY_FAILURE" 3 "SNA" ;
VAL_ 830 PARK_rearRightMiddleSensorState 0 "NO_FAILURE" 1 "PERMANENT_FAILURE" 2 "TEMPORARY_FAILURE" 3 "SNA" ;
VAL_ 830 PARK_rearRightRawDistData 255 "SNA" ;
VAL_ 830 PARK_rearRightSensorState 0 "NO_FAILURE" 1 "PERMANENT_FAILURE" 2 "TEMPORARY_FAILURE" 3 "SNA" ;
VAL_ 830 PARK_systemStatusRear 0 "DISABLED" 1 "ENABLED" 2 "UNUSED" 3 "SNA" ;
